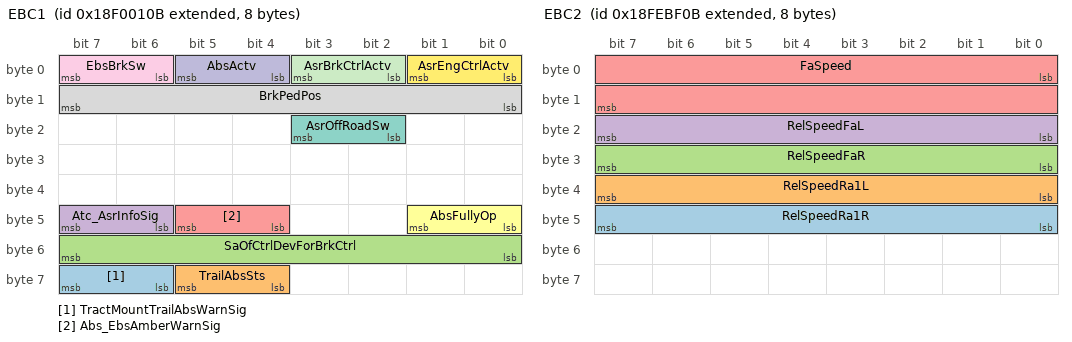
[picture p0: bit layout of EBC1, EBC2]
BO_ 2565865739 EBC1: 8 BSM
 SG_ TractMountTrailAbsWarnSig : 62|2@1+ (1,0) [0|3] ""  PCM
 SG_ TrailAbsSts : 60|2@1+ (1,0) [0|3] ""  PCM
 SG_ SaOfCtrlDevForBrkCtrl : 48|8@1+ (1,0) [0|255] "SA"  PCM
 SG_ Atc_AsrInfoSig : 46|2@1+ (1,0) [0|3] ""  PCM
 SG_ Abs_EbsAmberWarnSig : 44|2@1+ (1,0) [0|3] ""  PCM
 SG_ AbsFullyOp : 40|2@1+ (1,0) [0|3] ""  PCM
 SG_ AsrOffRoadSw : 18|2@1+ (1,0) [0|3] ""  PCM
 SG_ BrkPedPos : 8|8@1+ (0.4,0) [0|100] "%"  PCM
 SG_ EbsBrkSw : 6|2@1+ (1,0) [0|3] ""  PCM
 SG_ AbsActv : 4|2@1+ (1,0) [0|3] ""  PCM
 SG_ AsrBrkCtrlActv : 2|2@1+ (1,0) [0|3] ""  PCM
 SG_ AsrEngCtrlActv : 0|2@1+ (1,0) [0|3] ""  PCM

BO_ 2566831883 EBC2: 8 BSM
 SG_ RelSpeedRa1R : 40|8@1+ (0.0625,-7.8125) [-7.8125|7.8125] "km/h"  PCM
 SG_ RelSpeedRa1L : 32|8@1+ (0.0625,-7.8125) [-7.8125|7.8125] "km/h"  PCM
 SG_ RelSpeedFaR : 24|8@1+ (0.0625,-7.8125) [-7.8125|7.8125] "km/h"  PCM
 SG_ RelSpeedFaL : 16|8@1+ (0.0625,-7.8125) [-7.8125|7.8125] "km/h"  PCM
 SG_ FaSpeed : 0|16@1+ (0.00390625,0) [0|250.996] "km/h"  PCM

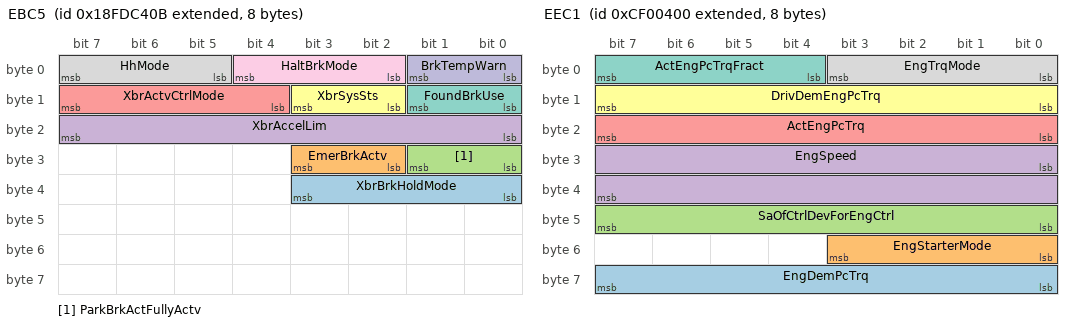
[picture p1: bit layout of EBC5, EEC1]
BO_ 2566767627 EBC5: 8 BSM
 SG_ XbrBrkHoldMode : 32|4@1+ (1,0) [0|15] ""  PCM
 SG_ EmerBrkActv : 26|2@1+ (1,0) [0|3] ""  PCM
 SG_ ParkBrkActFullyActv : 24|2@1+ (1,0) [0|3] ""  PCM
 SG_ XbrAccelLim : 16|8@1+ (0.1,-12.5) [-12.5|12.5] "m/s�"  PCM
 SG_ XbrActvCtrlMode : 12|4@1+ (1,0) [0|15] ""  PCM
 SG_ XbrSysSts : 10|2@1+ (1,0) [0|3] ""  PCM
 SG_ FoundBrkUse : 8|2@1+ (1,0) [0|3] ""  PCM
 SG_ HhMode : 5|3@1+ (1,0) [0|7] ""  PCM
 SG_ HaltBrkMode : 2|3@1+ (1,0) [0|7] ""  PCM
 SG_ BrkTempWarn : 0|2@1+ (1,0) [0|3] ""  PCM

BO_ 2566841088 EC1: 32 ECM
 SG_ EngJ : 240|16@1+ (0.004,0) [0|257.02] "kg*m�"  PCM
 SG_ EngReqSpeedCtrlRngUpLimXr : 224|16@1+ (0.125,0) [0|8031.875] "rpm"  PCM
 SG_ EngReqTrqCtrlRngUpLim : 216|8@1+ (1,-125) [-125|125] "%"  PCM
 SG_ EngReqTrqCtrlRngLowLim : 208|8@1+ (1,-125) [-125|125] "%"  PCM
 SG_ EngReqSpeedCtrlRngUpLim : 200|8@1+ (10,0) [0|2500] "rpm"  PCM
 SG_ EngReqSpeedCtrlRngLowLim : 192|8@1+ (10,0) [0|2500] "rpm"  PCM
 SG_ EngMaxMomOvrTimeLim : 184|8@1+ (0.1,0) [0|25] "s"  PCM
 SG_ EngMaxMomOvrSpeedPnt7 : 168|16@1+ (0.125,0) [0|8031.875] "rpm"  PCM
 SG_ EngRefTrq : 152|16@1+ (1,0) [0|64255] "Nm"  PCM
 SG_ EngGainEndspeedGov : 136|16@1+ (0.00078125,0) [0|50.2] "%/rpm"  PCM
 SG_ EngSpeedAtHighIdlePnt6 : 120|16@1+ (0.125,0) [0|8031.875] "rpm"  PCM
 SG_ EngPcTrqAtPnt5 : 112|8@1+ (1,-125) [-125|125] "%"  PCM
 SG_ EngSpeedAtPnt5 : 96|16@1+ (0.125,0) [0|8031.875] "rpm"  PCM
 SG_ EngPcTrqAtPnt4 : 88|8@1+ (1,-125) [-125|125] "%"  PCM
 SG_ EngSpeedAtPnt4 : 72|16@1+ (0.125,0) [0|8031.875] "rpm"  PCM
 SG_ EngPcTrqAtPnt3 : 64|8@1+ (1,-125) [-125|125] "%"  PCM
 SG_ EngSpeedAtPnt3 : 48|16@1+ (0.125,0) [0|8031.875] "rpm"  PCM
 SG_ EngPcTrqAtPnt2 : 40|8@1+ (1,-125) [-125|125] "%"  PCM
 SG_ EngSpeedAtPnt2 : 24|16@1+ (0.125,0) [0|8031.875] "rpm"  PCM
 SG_ EngPcTrqAtIdlePnt1 : 16|8@1+ (1,-125) [-125|125] "%"  PCM
 SG_ EngSpeedAtIdlePnt1 : 0|16@1+ (0.125,0) [0|8031.875] "rpm"  PCM

BO_ 2566767877 ECUID_05: 1005 NODE_5
 SG_ EcuHwId : 40|8@1+ (1,0) [0|255] "ASCII"  PCM
 SG_ EcuManName : 32|8@1+ (1,0) [0|255] "ASCII"  PCM
 SG_ EcuType : 24|8@1+ (1,0) [0|255] "ASCII"  PCM
 SG_ EcuLoc : 16|8@1+ (1,0) [0|255] "ASCII"  PCM
 SG_ EcuSn : 8|8@1+ (1,0) [0|255] "ASCII"  PCM
 SG_ EcuPn : 0|8@1+ (1,0) [0|255] "ASCII"  PCM

BO_ 2566767879 ECUID_07: 1005 NODE_7
 SG_ EcuHwId_FDC507 : 40|8@1+ (1,0) [0|255] "ASCII"  PCM
 SG_ EcuManName_FDC507 : 32|8@1+ (1,0) [0|255] "ASCII"  PCM
 SG_ EcuType_FDC507 : 24|8@1+ (1,0) [0|255] "ASCII"  PCM
 SG_ EcuLoc_FDC507 : 16|8@1+ (1,0) [0|255] "ASCII"  PCM
 SG_ EcuSn_FDC507 : 8|8@1+ (1,0) [0|255] "ASCII"  PCM
 SG_ EcuPn_FDC507 : 0|8@1+ (1,0) [0|255] "ASCII"  PCM

BO_ 2566767895 ECUID_17: 1005 ICC
 SG_ EcuHwId_FDC517 : 40|8@1+ (1,0) [0|255] "ASCII"  PCM
 SG_ EcuManName_FDC517 : 32|8@1+ (1,0) [0|255] "ASCII"  PCM
 SG_ EcuType_FDC517 : 24|8@1+ (1,0) [0|255] "ASCII"  PCM
 SG_ EcuLoc_FDC517 : 16|8@1+ (1,0) [0|255] "ASCII"  PCM
 SG_ EcuSn_FDC517 : 8|8@1+ (1,0) [0|255] "ASCII"  PCM
 SG_ EcuPn_FDC517 : 0|8@1+ (1,0) [0|255] "ASCII"  PCM

BO_ 2566767898 ECUID_1A: 1005 ECS
 SG_ EcuHwId_FDC51A : 40|8@1+ (1,0) [0|255] "ASCII"  PCM
 SG_ EcuManName_FDC51A : 32|8@1+ (1,0) [0|255] "ASCII"  PCM
 SG_ EcuType_FDC51A : 24|8@1+ (1,0) [0|255] "ASCII"  PCM
 SG_ EcuLoc_FDC51A : 16|8@1+ (1,0) [0|255] "ASCII"  PCM
 SG_ EcuSn_FDC51A : 8|8@1+ (1,0) [0|255] "ASCII"  PCM
 SG_ EcuPn_FDC51A : 0|8@1+ (1,0) [0|255] "ASCII"  PCM

BO_ 2566767901 ECUID_1D: 1005 SGW
 SG_ EcuHwId_FDC51D : 40|8@1+ (1,0) [0|255] "ASCII"  PCM
 SG_ EcuManName_FDC51D : 32|8@1+ (1,0) [0|255] "ASCII"  PCM
 SG_ EcuType_FDC51D : 24|8@1+ (1,0) [0|255] "ASCII"  PCM
 SG_ EcuLoc_FDC51D : 16|8@1+ (1,0) [0|255] "ASCII"  PCM
 SG_ EcuSn_FDC51D : 8|8@1+ (1,0) [0|255] "ASCII"  PCM
 SG_ EcuPn_FDC51D : 0|8@1+ (1,0) [0|255] "ASCII"  PCM

BO_ 2566767908 ECUID_24: 1005 NODE_24
 SG_ EcuHwId_FDC524 : 40|8@1+ (1,0) [0|255] "ASCII"  PCM
 SG_ EcuManName_FDC524 : 32|8@1+ (1,0) [0|255] "ASCII"  PCM
 SG_ EcuType_FDC524 : 24|8@1+ (1,0) [0|255] "ASCII"  PCM
 SG_ EcuLoc_FDC524 : 16|8@1+ (1,0) [0|255] "ASCII"  PCM
 SG_ EcuSn_FDC524 : 8|8@1+ (1,0) [0|255] "ASCII"  PCM
 SG_ EcuPn_FDC524 : 0|8@1+ (1,0) [0|255] "ASCII"  PCM

BO_ 2566767911 ECUID_27: 1005 VCM
 SG_ EcuHwId_FDC527 : 40|8@1+ (1,0) [0|255] "ASCII"  PCM
 SG_ EcuManName_FDC527 : 32|8@1+ (1,0) [0|255] "ASCII"  PCM
 SG_ EcuType_FDC527 : 24|8@1+ (1,0) [0|255] "ASCII"  PCM
 SG_ EcuLoc_FDC527 : 16|8@1+ (1,0) [0|255] "ASCII"  PCM
 SG_ EcuSn_FDC527 : 8|8@1+ (1,0) [0|255] "ASCII"  PCM
 SG_ EcuPn_FDC527 : 0|8@1+ (1,0) [0|255] "ASCII"  PCM

BO_ 2566767919 ECUID_2F: 1005 ECAS
 SG_ EcuHwId_FDC52F : 40|8@1+ (1,0) [0|255] "ASCII"  PCM
 SG_ EcuManName_FDC52F : 32|8@1+ (1,0) [0|255] "ASCII"  PCM
 SG_ EcuLoc_FDC52F : 16|8@1+ (1,0) [0|255] "ASCII"  PCM
 SG_ EcuSn_FDC52F : 8|8@1+ (1,0) [0|255] "ASCII"  PCM
 SG_ EcuPn_FDC52F : 0|8@1+ (1,0) [0|255] "ASCII"  PCM

BO_ 2566767920 ECUID_30: 1005 CDC
 SG_ EcuHwId_FDC530 : 40|8@1+ (1,0) [0|255] "ASCII"  PCM
 SG_ EcuManName_FDC530 : 32|8@1+ (1,0) [0|255] "ASCII"  PCM
 SG_ EcuType_FDC530 : 24|8@1+ (1,0) [0|255] "ASCII"  PCM
 SG_ EcuLoc_FDC530 : 16|8@1+ (1,0) [0|255] "ASCII"  PCM
 SG_ EcuSn_FDC530 : 8|8@1+ (1,0) [0|255] "ASCII"  PCM
 SG_ EcuPn_FDC530 : 0|8@1+ (1,0) [0|255] "ASCII"  PCM

BO_ 2566767923 ECUID_33: 1005 OptiTire
 SG_ EcuHwId_FDC533 : 40|8@1+ (1,0) [0|255] "ASCII"  PCM
 SG_ EcuManName_FDC533 : 32|8@1+ (1,0) [0|255] "ASCII"  PCM
 SG_ EcuType_FDC533 : 24|8@1+ (1,0) [0|255] "ASCII"  PCM
 SG_ EcuLoc_FDC533 : 16|8@1+ (1,0) [0|255] "ASCII"  PCM
 SG_ EcuSn_FDC533 : 8|8@1+ (1,0) [0|255] "ASCII"  PCM
 SG_ EcuPn_FDC533 : 0|8@1+ (1,0) [0|255] "ASCII"  PCM

BO_ 2566767937 ECUID_41: 1005 NIS_RDR
 SG_ EcuHwId_FDC541 : 40|8@1+ (1,0) [0|255] "ASCII"  PCM
 SG_ EcuManName_FDC541 : 32|8@1+ (1,0) [0|255] "ASCII"  PCM
 SG_ EcuType_FDC541 : 24|8@1+ (1,0) [0|255] "ASCII"  PCM
 SG_ EcuLoc_FDC541 : 16|8@1+ (1,0) [0|255] "ASCII"  PCM
 SG_ EcuSn_FDC541 : 8|8@1+ (1,0) [0|255] "ASCII"  PCM
 SG_ EcuPn_FDC541 : 0|8@1+ (1,0) [0|255] "ASCII"  PCM

BO_ 2566767945 ECUID_49: 1005 NODE_49
 SG_ EcuHwId_FDC549 : 40|8@1+ (1,0) [0|255] "ASCII"  PCM
 SG_ EcuManName_FDC549 : 32|8@1+ (1,0) [0|255] "ASCII"  PCM
 SG_ EcuType_FDC549 : 24|8@1+ (1,0) [0|255] "ASCII"  PCM
 SG_ EcuLoc_FDC549 : 16|8@1+ (1,0) [0|255] "ASCII"  PCM
 SG_ EcuSn_FDC549 : 8|8@1+ (1,0) [0|255] "ASCII"  PCM
 SG_ EcuPn_FDC549 : 0|8@1+ (1,0) [0|255] "ASCII"  PCM

BO_ 2566767946 ECUID_4A: 1005 PCM
 SG_ EcuHwId_FDC54A : 40|8@1+ (1,0) [0|255] "ASCII" Vector__XXX
 SG_ EcuManName_FDC54A : 32|8@1+ (1,0) [0|255] "ASCII" Vector__XXX
 SG_ EcuType_FDC54A : 24|8@1+ (1,0) [0|255] "ASCII" Vector__XXX
 SG_ EcuLoc_FDC54A : 16|8@1+ (1,0) [0|255] "ASCII" Vector__XXX
 SG_ EcuSn_FDC54A : 8|8@1+ (1,0) [0|255] "ASCII" Vector__XXX
 SG_ EcuPn_FDC54A : 0|8@1+ (1,0) [0|255] "ASCII" Vector__XXX

BO_ 2566767949 ECUID_4D: 1005 SCU
 SG_ EcuHwId_FDC54D : 40|8@1+ (1,0) [0|255] "ASCII"  PCM
 SG_ EcuManName_FDC54D : 32|8@1+ (1,0) [0|255] "ASCII"  PCM
 SG_ EcuType_FDC54D : 24|8@1+ (1,0) [0|255] "ASCII"  PCM
 SG_ EcuLoc_FDC54D : 16|8@1+ (1,0) [0|255] "ASCII"  PCM
 SG_ EcuSn_FDC54D : 8|8@1+ (1,0) [0|255] "ASCII"  PCM
 SG_ EcuPn_FDC54D : 0|8@1+ (1,0) [0|255] "ASCII"  PCM

BO_ 2566767955 ECUID_53: 1005 Airbag
 SG_ EcuHwId_FDC553 : 40|8@1+ (1,0) [0|255] "ASCII"  PCM
 SG_ EcuManName_FDC553 : 32|8@1+ (1,0) [0|255] "ASCII"  PCM
 SG_ EcuType_FDC553 : 24|8@1+ (1,0) [0|255] "ASCII"  PCM
 SG_ EcuLoc_FDC553 : 16|8@1+ (1,0) [0|255] "ASCII"  PCM
 SG_ EcuSn_FDC553 : 8|8@1+ (1,0) [0|255] "ASCII"  PCM
 SG_ EcuPn_FDC553 : 0|8@1+ (1,0) [0|255] "ASCII"  PCM

BO_ 2566767992 ECUID_78: 1005 PAM
 SG_ EcuHwId_FDC578 : 40|8@1+ (1,0) [0|255] "ASCII"  PCM
 SG_ EcuManName_FDC578 : 32|8@1+ (1,0) [0|255] "ASCII"  PCM
 SG_ EcuType_FDC578 : 24|8@1+ (1,0) [0|255] "ASCII"  PCM
 SG_ EcuLoc_FDC578 : 16|8@1+ (1,0) [0|255] "ASCII"  PCM
 SG_ EcuSn_FDC578 : 8|8@1+ (1,0) [0|255] "ASCII"  PCM
 SG_ EcuPn_FDC578 : 0|8@1+ (1,0) [0|255] "ASCII"  PCM

BO_ 2566767996 ECUID_7C: 1005 NODE_7C
 SG_ EcuHwId_FDC57C : 40|8@1+ (1,0) [0|255] "ASCII"  PCM
 SG_ EcuManName_FDC57C : 32|8@1+ (1,0) [0|255] "ASCII"  PCM
 SG_ EcuType_FDC57C : 24|8@1+ (1,0) [0|255] "ASCII"  PCM
 SG_ EcuLoc_FDC57C : 16|8@1+ (1,0) [0|255] "ASCII"  PCM
 SG_ EcuSn_FDC57C : 8|8@1+ (1,0) [0|255] "ASCII"  PCM
 SG_ EcuPn_FDC57C : 0|8@1+ (1,0) [0|255] "ASCII"  PCM

BO_ 2566768110 ECUID_EE: 1005 DTCO
 SG_ EcuPn_FDC5EE : 0|8@1+ (1,0) [0|255] "ASCII"  PCM

BO_ 2566768111 ECUID_EF: 1005 NODE_EF
 SG_ EcuHwId_FDC5EF : 40|8@1+ (1,0) [0|255] "ASCII"  PCM
 SG_ EcuManName_FDC5EF : 32|8@1+ (1,0) [0|255] "ASCII"  PCM
 SG_ EcuType_FDC5EF : 24|8@1+ (1,0) [0|255] "ASCII"  PCM
 SG_ EcuLoc_FDC5EF : 16|8@1+ (1,0) [0|255] "ASCII"  PCM
 SG_ EcuSn_FDC5EF : 8|8@1+ (1,0) [0|255] "ASCII"  PCM
 SG_ EcuPn_FDC5EF : 0|8@1+ (1,0) [0|255] "ASCII"  PCM

BO_ 2566768114 ECUID_F2: 1005 NODE_F2
 SG_ EcuHwId_FDC5F2 : 40|8@1+ (1,0) [0|255] "ASCII"  PCM
 SG_ EcuManName_FDC5F2 : 32|8@1+ (1,0) [0|255] "ASCII"  PCM
 SG_ EcuType_FDC5F2 : 24|8@1+ (1,0) [0|255] "ASCII"  PCM
 SG_ EcuLoc_FDC5F2 : 16|8@1+ (1,0) [0|255] "ASCII"  PCM
 SG_ EcuSn_FDC5F2 : 8|8@1+ (1,0) [0|255] "ASCII"  PCM
 SG_ EcuPn_FDC5F2 : 0|8@1+ (1,0) [0|255] "ASCII"  PCM

BO_ 2566768115 ECUID_F3: 1005 NODE_F3
 SG_ EcuHwId_FDC5F3 : 40|8@1+ (1,0) [0|255] "ASCII"  PCM
 SG_ EcuManName_FDC5F3 : 32|8@1+ (1,0) [0|255] "ASCII"  PCM
 SG_ EcuType_FDC5F3 : 24|8@1+ (1,0) [0|255] "ASCII"  PCM
 SG_ EcuLoc_FDC5F3 : 16|8@1+ (1,0) [0|255] "ASCII"  PCM
 SG_ EcuSn_FDC5F3 : 8|8@1+ (1,0) [0|255] "ASCII"  PCM
 SG_ EcuPn_FDC5F3 : 0|8@1+ (1,0) [0|255] "ASCII"  PCM

BO_ 2566856960 Edc2Bc: 8 ECM
 SG_ AtDpfAregenSts : 60|2@1+ (1,0) [0|3] ""  PCM
 SG_ FuelType : 58|2@1+ (1,0) [0|3] ""  PCM
 SG_ AcComprSts : 56|2@1+ (1,0) [0|3] ""  PCM
 SG_ EdcOpSts : 52|4@1+ (1,0) [0|15] ""  PCM
 SG_ EngDegrLev : 48|4@1+ (1,0) [0|15] ""  PCM
 SG_ FuelFiltHeat : 44|2@1+ (1,0) [0|3] ""  PCM
 SG_ WaterInFuelInd1 : 42|2@1+ (1,0) [0|3] ""  PCM
 SG_ EngOilPrsLow : 40|2@1+ (1,0) [0|3] ""  PCM
 SG_ RegenStsLamp : 34|2@1+ (1,0) [0|3] ""  PCM
 SG_ OilLifeMonSts : 32|2@1+ (1,0) [0|3] ""  PCM
 SG_ ExhGasTempSts : 30|2@1+ (1,0) [0|3] ""  PCM
 SG_ VslaSts : 28|2@1+ (1,0) [0|3] ""  PCM
 SG_ ElLoadReq : 26|2@1+ (1,0) [0|3] ""  PCM
 SG_ ObdMilSts : 24|2@1+ (1,0) [0|3] ""  PCM
 SG_ MaxVslSetp : 16|8@1+ (1,0) [0|250] "km/h"  PCM
 SG_ EngOverTemp : 13|3@1+ (1,0) [0|7] ""  PCM
 SG_ UnsuccRegenStsLamp1 : 12|1@1+ (1,0) [0|1] ""  PCM
 SG_ EngOverspeed : 10|2@1+ (1,0) [0|3] ""  PCM
 SG_ VslSts : 8|2@1+ (1,0) [0|3] ""  PCM
 SG_ FuelBlkByImmo : 4|2@1+ (1,0) [0|3] ""  PCM
 SG_ AtDpfSts : 0|3@1+ (1,0) [0|7] ""  PCM

BO_ 2364539904 EEC1: 8 ECM
 SG_ EngDemPcTrq : 56|8@1+ (1,-125) [-125|125] "%"  PCM
 SG_ EngStarterMode : 48|4@1+ (1,0) [0|15] ""  PCM
 SG_ SaOfCtrlDevForEngCtrl : 40|8@1+ (1,0) [0|255] "SA"  PCM
 SG_ EngSpeed : 24|16@1+ (0.125,0) [0|8031.875] "rpm"  PCM
 SG_ ActEngPcTrq : 16|8@1+ (1,-125) [-125|125] "%"  PCM
 SG_ DrivDemEngPcTrq : 8|8@1+ (1,-125) [-125|125] "%"  PCM
 SG_ ActEngPcTrqFract : 4|4@1+ (0.125,0) [0|0.875] "%"  PCM
 SG_ EngTrqMode : 0|4@1+ (1,0) [0|15] ""  PCM

BO_ 2566767104 EEC14: 8 ECM
 SG_ FuelType_FDC200 : 48|8@1+ (1,0) [0|255] ""  PCM

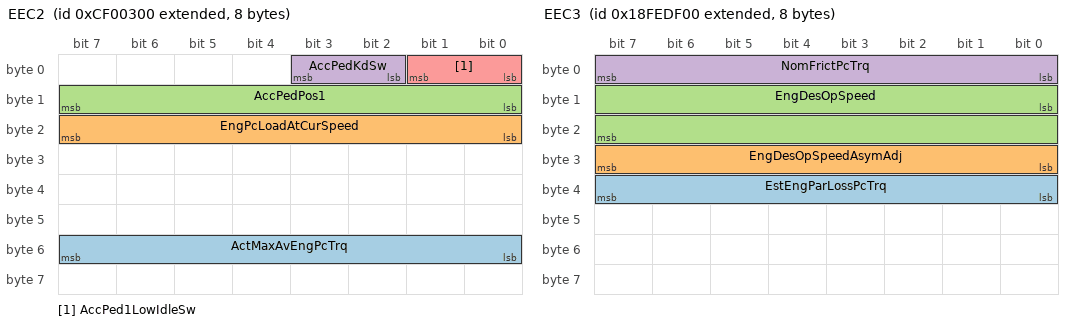
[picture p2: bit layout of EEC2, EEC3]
BO_ 2364539648 EEC2: 8 ECM
 SG_ ActMaxAvEngPcTrq : 48|8@1+ (0.4,0) [0|100] "%"  PCM
 SG_ EngPcLoadAtCurSpeed : 16|8@1+ (1,0) [0|250] "%"  PCM
 SG_ AccPedPos1 : 8|8@1+ (0.4,0) [0|100] "%"  PCM
 SG_ AccPedKdSw : 2|2@1+ (1,0) [0|3] ""  PCM
 SG_ AccPed1LowIdleSw : 0|2@1+ (1,0) [0|3] ""  PCM

BO_ 2566840064 EEC3: 8 ECM
 SG_ EstEngParLossPcTrq : 32|8@1+ (1,-125) [-125|125] "%"  PCM
 SG_ EngDesOpSpeedAsymAdj : 24|8@1+ (1,0) [0|250] ""  PCM
 SG_ EngDesOpSpeed : 8|16@1+ (0.125,0) [0|8031.875] "rpm"  PCM
 SG_ NomFrictPcTrq : 0|8@1+ (1,-125) [-125|125] "%"  PCM

BO_ 2566844160 EFLP1: 8 ECM
 SG_ EngCoolPrs1 : 48|8@1+ (2,0) [0|500] "kPa"  PCM
 SG_ EngOilLev : 16|8@1+ (0.4,0) [0|100] "%"  PCM

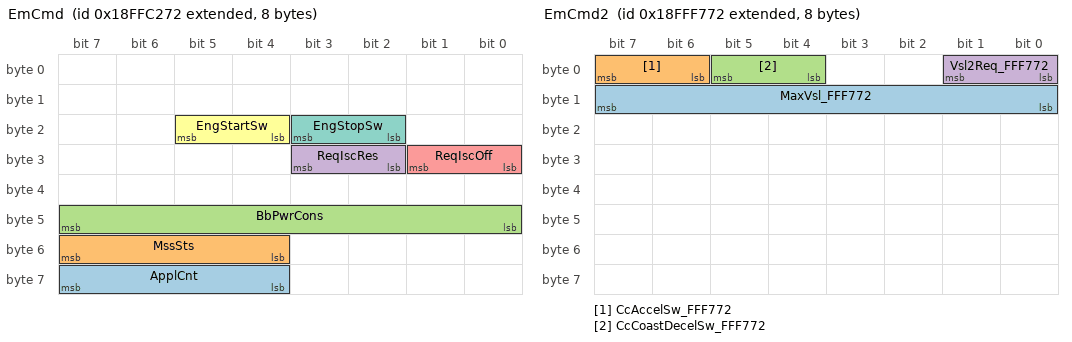
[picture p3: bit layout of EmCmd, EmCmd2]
BO_ 2566898290 EmCmd: 8 EM_PTO
 SG_ ApplCnt : 60|4@1+ (1,0) [0|15] ""  PCM
 SG_ MssSts : 52|4@1+ (1,0) [0|15] ""  PCM
 SG_ BbPwrCons : 40|8@1+ (1,0) [0|250] "kW"  PCM
 SG_ ReqIscRes : 26|2@1+ (1,0) [0|3] ""  PCM
 SG_ ReqIscOff : 24|2@1+ (1,0) [0|3] ""  PCM
 SG_ EngStartSw : 20|2@1+ (1,0) [0|3] ""  PCM
 SG_ EngStopSw : 18|2@1+ (1,0) [0|3] ""  PCM

BO_ 2566911858 EmCmd2: 8 EM_PTO
 SG_ MaxVsl_FFF772 : 8|8@1+ (1,0) [0|250] "km/h"  PCM
 SG_ CcAccelSw_FFF772 : 6|2@1+ (1,0) [0|3] ""  PCM
 SG_ CcCoastDecelSw_FFF772 : 4|2@1+ (1,0) [0|3] ""  PCM
 SG_ Vsl2Req_FFF772 : 0|2@1+ (1,0) [0|3] ""  PCM

BO_ 2565865505 ERC1_21: 8 BCM
 SG_ RetSelNonEng : 48|8@1+ (0.4,0) [0|100] "%"  PCM
 SG_ RetEnaBrkAssSw : 4|2@1+ (1,0) [0|3] ""  PCM

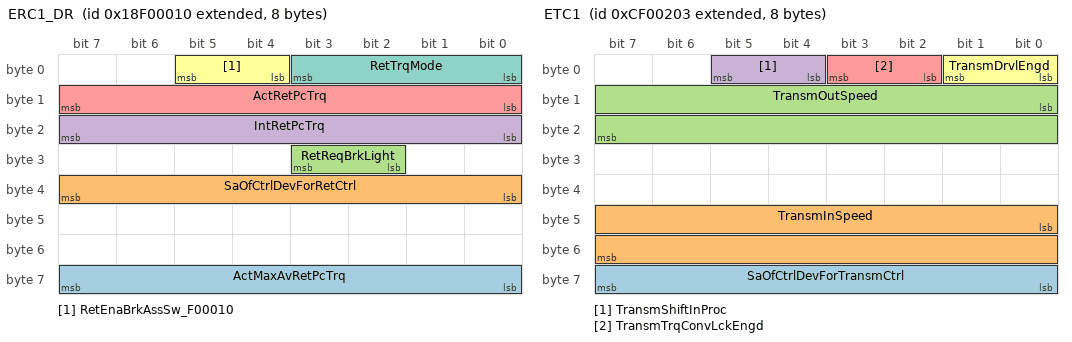
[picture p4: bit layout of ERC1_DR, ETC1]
BO_ 2565865488 ERC1_DR: 8 EST54_IRCS
 SG_ ActMaxAvRetPcTrq : 56|8@1+ (1,-125) [-125|125] "%"  PCM
 SG_ SaOfCtrlDevForRetCtrl : 32|8@1+ (1,0) [0|255] "SA"  PCM
 SG_ RetReqBrkLight : 26|2@1+ (1,0) [0|3] ""  PCM
 SG_ IntRetPcTrq : 16|8@1+ (1,-125) [-125|125] "%"  PCM
 SG_ ActRetPcTrq : 8|8@1+ (1,-125) [-125|125] "%"  PCM
 SG_ RetEnaBrkAssSw_F00010 : 4|2@1+ (1,0) [0|3] ""  PCM
 SG_ RetTrqMode : 0|4@1+ (1,0) [0|15] ""  PCM

BO_ 2566843904 ET1: 8 ECM
 SG_ EngFuel1Temp1 : 8|8@1+ (1,-40) [-40|210] "�C"  PCM
 SG_ EngCoolTemp : 0|8@1+ (1,-40) [-40|210] "�C"  PCM

BO_ 2364539395 ETC1: 8 AI_G5_TCM
 SG_ SaOfCtrlDevForTransmCtrl : 56|8@1+ (1,0) [0|255] "SA"  PCM
 SG_ TransmInSpeed : 40|16@1+ (0.125,0) [0|8031.875] "rpm"  PCM
 SG_ TransmOutSpeed : 8|16@1+ (0.125,0) [0|8031.875] "rpm"  PCM
 SG_ TransmShiftInProc : 4|2@1+ (1,0) [0|3] ""  PCM
 SG_ TransmTrqConvLckEngd : 2|2@1+ (1,0) [0|3] ""  PCM
 SG_ TransmDrvlEngd : 0|2@1+ (1,0) [0|3] ""  PCM

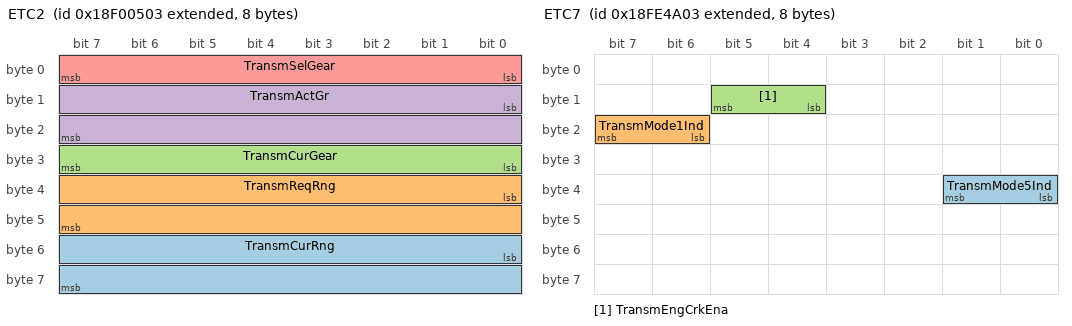
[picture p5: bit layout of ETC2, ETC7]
BO_ 2565866755 ETC2: 8 AI_G5_TCM
 SG_ TransmCurRng : 48|16@1+ (1,0) [0|255] "ASCII"  PCM
 SG_ TransmReqRng : 32|16@1+ (1,0) [0|255] "ASCII"  PCM
 SG_ TransmCurGear : 24|8@1+ (1,-125) [-125|125] "gear value"  PCM
 SG_ TransmActGr : 8|16@1+ (0.001,0) [0|64.255] ""  PCM
 SG_ TransmSelGear : 0|8@1+ (1,-125) [-125|125] "gear value"  PCM

BO_ 2633941763 ETC5: 8 AI_G5_TCM
 SG_ TransmRevDirSw : 8|2@1+ (1,0) [0|3] ""  PCM

BO_ 2566801923 ETC7: 8 AI_G5_TCM
 SG_ TransmMode5Ind : 32|2@1+ (1,0) [0|3] ""  PCM
 SG_ TransmMode1Ind : 22|2@1+ (1,0) [0|3] ""  PCM
 SG_ TransmEngCrkEna : 12|2@1+ (1,0) [0|3] ""  PCM

BO_ 2364541955 ETC8: 8 AI_G5_TCM
 SG_ TransmTrqConvRatio : 0|16@1+ (0.001,0) [0|64.255] ""  PCM

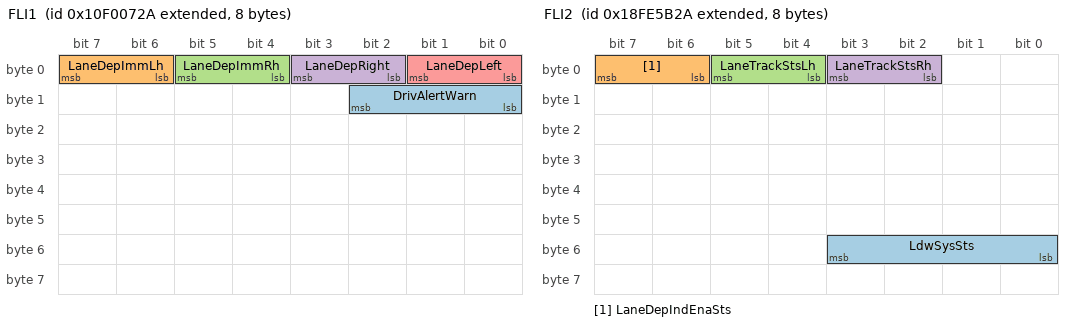
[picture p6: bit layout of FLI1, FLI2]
BO_ 2431649578 FLI1: 8 LDW
 SG_ DrivAlertWarn : 8|3@1+ (1,0) [0|7] ""  PCM
 SG_ LaneDepImmLh : 6|2@1+ (1,0) [0|3] ""  PCM
 SG_ LaneDepImmRh : 4|2@1+ (1,0) [0|3] ""  PCM
 SG_ LaneDepRight : 2|2@1+ (1,0) [0|3] ""  PCM
 SG_ LaneDepLeft : 0|2@1+ (1,0) [0|3] ""  PCM

BO_ 2566806314 FLI2: 8 LDW
 SG_ LdwSysSts : 48|4@1+ (1,0) [0|15] ""  PCM
 SG_ LaneDepIndEnaSts : 6|2@1+ (1,0) [0|3] ""  PCM
 SG_ LaneTrackStsLh : 4|2@1+ (1,0) [0|3] ""  PCM
 SG_ LaneTrackStsRh : 2|2@1+ (1,0) [0|3] ""  PCM

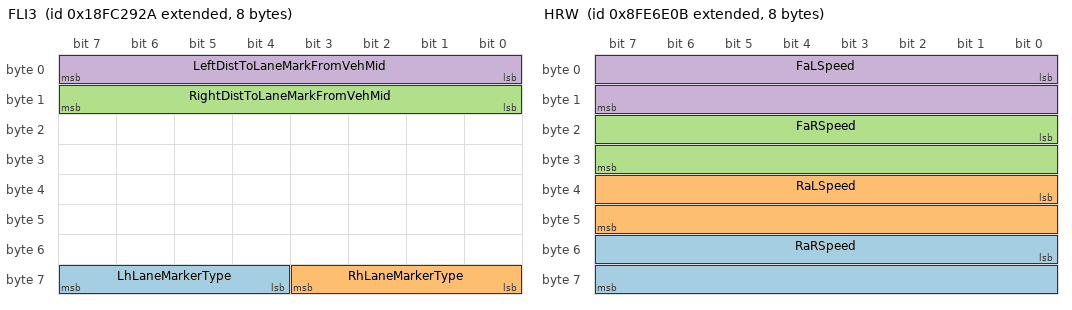
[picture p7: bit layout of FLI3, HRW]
BO_ 2566662442 FLI3: 8 LDW
 SG_ LhLaneMarkerType : 60|4@1+ (1,0) [0|15] ""  PCM
 SG_ RhLaneMarkerType : 56|4@1+ (1,0) [0|15] ""  PCM
 SG_ RightDistToLaneMarkFromVehMid : 8|8@1+ (0.02,0) [0|5] "m"  PCM
 SG_ LeftDistToLaneMarkFromVehMid : 0|8@1+ (0.02,0) [0|5] "m"  PCM

BO_ 2561223201 FLIC: 8 BCM
 SG_ LdwEnaCmd : 0|2@1+ (1,0) [0|3] ""  PCM,LDW

BO_ 2566749463 FMS1_17: 8 ICC
 SG_ FrontFogLight m0 : 60|3@1+ (1,0) [0|7] ""  PCM
 SG_ LdwSwdOff m3 : 60|3@1+ (1,0) [0|7] ""  PCM
 SG_ PosLightSideLight m0 : 56|3@1+ (1,0) [0|7] ""  PCM
 SG_ EngCoolLev m1 : 56|3@1+ (1,0) [0|7] ""  PCM
 SG_ EscSwdOff m3 : 56|3@1+ (1,0) [0|7] ""  PCM
 SG_ EngOil m0 : 52|3@1+ (1,0) [0|7] ""  PCM
 SG_ EngOilLev_FD7D17 m1 : 52|3@1+ (1,0) [0|7] ""  PCM
 SG_ TcoInd m3 : 52|3@1+ (1,0) [0|7] ""  PCM
 SG_ BatChgCond m0 : 48|3@1+ (1,0) [0|7] ""  PCM
 SG_ EngCoolTemp_FD7D17 m0 : 44|3@1+ (1,0) [0|7] ""  PCM
 SG_ Malf_GenFail m1 : 44|3@1+ (1,0) [0|7] ""  PCM
 SG_ AdblueLev m2 : 44|3@1+ (1,0) [0|7] ""  PCM
 SG_ Airbag m3 : 44|3@1+ (1,0) [0|7] ""  PCM
 SG_ FuelLev m0 : 40|3@1+ (1,0) [0|7] ""  PCM
 SG_ TireFail_Malf m1 : 40|3@1+ (1,0) [0|7] ""  PCM
 SG_ ElMotSts m4 : 40|3@1+ (1,0) [0|7] ""  PCM
 SG_ HatchOpen m0 : 36|3@1+ (1,0) [0|7] ""  PCM
 SG_ BatCool m4 : 36|3@1+ (1,0) [0|7] ""  PCM
 SG_ BrkFail_BrkSysMalf m0 : 32|3@1+ (1,0) [0|7] ""  PCM
 SG_ WornBrkLin m1 : 32|3@1+ (1,0) [0|7] ""  PCM
 SG_ Acc m3 : 32|3@1+ (1,0) [0|7] ""  PCM
 SG_ LimPerfElMot m4 : 32|3@1+ (1,0) [0|7] ""  PCM
 SG_ ParkBrk m0 : 28|3@1+ (1,0) [0|7] ""  PCM
 SG_ AntiLckBrkSysFail m1 : 28|3@1+ (1,0) [0|7] ""  PCM
 SG_ Aebs m3 : 28|3@1+ (1,0) [0|7] ""  PCM
 SG_ BatTemp_FD7D17 m4 : 28|3@1+ (1,0) [0|7] ""  PCM
 SG_ TransmFail_Malf m1 : 24|3@1+ (1,0) [0|7] ""  PCM
 SG_ BrkLight m2 : 24|3@1+ (1,0) [0|7] ""  PCM
 SG_ LaneDepInd m3 : 24|3@1+ (1,0) [0|7] ""  PCM
 SG_ HighVSysCaution m4 : 24|3@1+ (1,0) [0|7] ""  PCM
 SG_ HazardWarn m0 : 20|3@1+ (1,0) [0|7] ""  PCM
 SG_ TransmFluidTemp m1 : 20|3@1+ (1,0) [0|7] ""  PCM
 SG_ EscInd m2 : 20|3@1+ (1,0) [0|7] ""  PCM
 SG_ Bat m4 : 20|3@1+ (1,0) [0|7] ""  PCM
 SG_ TurnSigs m0 : 16|3@1+ (1,0) [0|7] ""  PCM
 SG_ ServCallForMaint m1 : 16|3@1+ (1,0) [0|7] ""  PCM
 SG_ EngEmisSysFailMil m2 : 16|3@1+ (1,0) [0|7] ""  PCM
 SG_ SeatBelt m3 : 16|3@1+ (1,0) [0|7] ""  PCM
 SG_ LowBeamDipBeam m0 : 12|3@1+ (1,0) [0|7] ""  PCM
 SG_ Eng_Mil m1 : 12|3@1+ (1,0) [0|7] ""  PCM
 SG_ Ret m2 : 12|3@1+ (1,0) [0|7] ""  PCM
 SG_ FuelFiltDiffPrs m3 : 12|3@1+ (1,0) [0|7] ""  PCM
 SG_ HighBeamMainBeam m0 : 8|3@1+ (1,0) [0|7] ""  PCM
 SG_ HtCtrl m2 : 8|3@1+ (1,0) [0|7] ""  PCM
 SG_ AirFiltClog m3 : 8|3@1+ (1,0) [0|7] ""  PCM
 SG_ ElMotFails m4 : 8|3@1+ (1,0) [0|7] ""  PCM
 SG_ RearFogLight m1 : 4|3@1+ (1,0) [0|7] ""  PCM
 SG_ EngEmisFilt m4 : 4|3@1+ (1,0) [0|7] ""  PCM
 SG_ TtBlkId M : 0|4@1+ (1,0) [0|15] ""  PCM

BO_ 2566896128 FUELE2: 8 ECM
 SG_ EngInstFuelEcon : 16|16@1+ (0.001953125,0) [0|125.498046875] "km/L"  PCM
 SG_ EngFuelRate : 0|16@1+ (0.05,0) [0|3212.75] "L/h"  PCM

BO_ 2566841600 HOURS: 8 ECM
 SG_ EngTotRevl : 32|32@1+ (1000,0) [0|4211081215000] "r"  PCM
 SG_ EngTotHrOfOp : 0|32@1+ (0.05,0) [0|210554060.75] "h"  PCM

BO_ 2566719744 HRLFC: 8 ECM
 SG_ EngTotFuelUsedHr : 32|32@1+ (0.001,0) [0|4211081.215] "L"  PCM

BO_ 2298375691 HRW: 8 BSM
 SG_ RaRSpeed : 48|16@1+ (0.00390625,0) [0|250.996] "km/h"  PCM
 SG_ RaLSpeed : 32|16@1+ (0.00390625,0) [0|250.996] "km/h"  PCM
 SG_ FaRSpeed : 16|16@1+ (0.00390625,0) [0|250.996] "km/h"  PCM
 SG_ FaLSpeed : 0|16@1+ (0.00390625,0) [0|250.996] "km/h"  PCM

BO_ 2566609652 HVESP1CFG_F4: 16 NODE_F4
 SG_ Hvesp1CellVminLim : 120|8@1+ (0.02044,0) [0|5.11] "V"  PCM
 SG_ Hvesp1CellVmaxLim : 112|8@1+ (0.02044,0) [0|5.11] "V"  PCM
 SG_ Hvesp1RecomMinOpTemp : 96|16@1+ (0.03125,-273) [-273|1734.96875] "�C"  PCM
 SG_ Hvesp1RecomMaxOpTemp : 80|16@1+ (0.03125,-273) [-273|1734.96875] "�C"  PCM
 SG_ Hvesp1RecomMaxSoc : 64|16@1+ (0.0015625,0) [0|100.3984375] "%"  PCM
 SG_ Hvesp1RecomMinSoc : 48|16@1+ (0.0015625,0) [0|100.3984375] "%"  PCM
 SG_ Hvesp1RecomMaxOpV : 32|16@1+ (0.05,0) [0|3212.75] "V"  PCM
 SG_ Hvesp1RecomMinOpV : 16|16@1+ (0.05,0) [0|3212.75] "V"  PCM
 SG_ Hvesp1NomV : 0|16@1+ (0.05,0) [0|3212.75] "V"  PCM

BO_ 2566609141 HVESP2CFG_F5: 16 NODE_F5
 SG_ Hvesp2CellVminLim : 120|8@1+ (0.02044,0) [0|5.11] "V"  PCM
 SG_ Hvesp2CellVmaxLim : 112|8@1+ (0.02044,0) [0|5.11] "V"  PCM
 SG_ Hvesp2RecomMinOpTemp : 96|16@1+ (0.03125,-273) [-273|1734.96875] "�C"  PCM
 SG_ Hvesp2RecomMaxOpTemp : 80|16@1+ (0.03125,-273) [-273|1734.96875] "�C"  PCM
 SG_ Hvesp2RecomMaxSoc : 64|16@1+ (0.0015625,0) [0|100.3984375] "%"  PCM
 SG_ Hvesp2RecomMinSoc : 48|16@1+ (0.0015625,0) [0|100.3984375] "%"  PCM
 SG_ Hvesp2RecomMaxOpV : 32|16@1+ (0.05,0) [0|3212.75] "V"  PCM
 SG_ Hvesp2RecomMinOpV : 16|16@1+ (0.05,0) [0|3212.75] "V"  PCM
 SG_ Hvesp2NomV : 0|16@1+ (0.05,0) [0|3212.75] "V"  PCM

BO_ 2566608630 HVESP3CFG_F6: 16 NODE_F6
 SG_ Hvesp3CellVminLim : 120|8@1+ (0.02044,0) [0|5.11] "V"  PCM
 SG_ Hvesp3CellVmaxLim : 112|8@1+ (0.02044,0) [0|5.11] "V"  PCM
 SG_ Hvesp3RecomMinOpTemp : 96|16@1+ (0.03125,-273) [-273|1734.96875] "�C"  PCM
 SG_ Hvesp3RecomMaxOpTemp : 80|16@1+ (0.03125,-273) [-273|1734.96875] "�C"  PCM
 SG_ Hvesp3RecomMaxSoc : 64|16@1+ (0.0015625,0) [0|100.3984375] "%"  PCM
 SG_ Hvesp3RecomMinSoc : 48|16@1+ (0.0015625,0) [0|100.3984375] "%"  PCM
 SG_ Hvesp3RecomMaxOpV : 32|16@1+ (0.05,0) [0|3212.75] "V"  PCM
 SG_ Hvesp3RecomMinOpV : 16|16@1+ (0.05,0) [0|3212.75] "V"  PCM
 SG_ Hvesp3NomV : 0|16@1+ (0.05,0) [0|3212.75] "V"  PCM

BO_ 2566608006 HVESP4CFG_86: 16 NODE_86
 SG_ Hvesp4CellVminLim : 120|8@1+ (0.02044,0) [0|5.11] "V"  PCM
 SG_ Hvesp4CellVmaxLim : 112|8@1+ (0.02044,0) [0|5.11] "V"  PCM
 SG_ Hvesp4RecomMinOpTemp : 96|16@1+ (0.03125,-273) [-273|1734.96875] "�C"  PCM
 SG_ Hvesp4RecomMaxOpTemp : 80|16@1+ (0.03125,-273) [-273|1734.96875] "�C"  PCM
 SG_ Hvesp4RecomMaxSoc : 64|16@1+ (0.0015625,0) [0|100.3984375] "%"  PCM
 SG_ Hvesp4RecomMinSoc : 48|16@1+ (0.0015625,0) [0|100.3984375] "%"  PCM
 SG_ Hvesp4RecomMaxOpV : 32|16@1+ (0.05,0) [0|3212.75] "V"  PCM
 SG_ Hvesp4RecomMinOpV : 16|16@1+ (0.05,0) [0|3212.75] "V"  PCM
 SG_ Hvesp4NomV : 0|16@1+ (0.05,0) [0|3212.75] "V"  PCM

BO_ 2566607495 HVESP5CFG_87: 16 NODE_87
 SG_ Hvesp5CellVminLim : 120|8@1+ (0.02044,0) [0|5.11] "V"  PCM
 SG_ Hvesp5CellVmaxLim : 112|8@1+ (0.02044,0) [0|5.11] "V"  PCM
 SG_ Hvesp5RecomMinOpTemp : 96|16@1+ (0.03125,-273) [-273|1734.96875] "�C"  PCM
 SG_ Hvesp5RecomMaxOpTemp : 80|16@1+ (0.03125,-273) [-273|1734.96875] "�C"  PCM
 SG_ Hvesp5RecomMaxSoc : 64|16@1+ (0.0015625,0) [0|100.3984375] "%"  PCM
 SG_ Hvesp5RecomMinSoc : 48|16@1+ (0.0015625,0) [0|100.3984375] "%"  PCM
 SG_ Hvesp5RecomMaxOpV : 32|16@1+ (0.05,0) [0|3212.75] "V"  PCM
 SG_ Hvesp5RecomMinOpV : 16|16@1+ (0.05,0) [0|3212.75] "V"  PCM
 SG_ Hvesp5NomV : 0|16@1+ (0.05,0) [0|3212.75] "V"  PCM

CM_ BO_ 2565865739 "- FMS Trans.Rate=100ms";
CM_ BO_ 2566831883 "- SGW MY19 routes this message on DTB only for retrocompatibily of DTCO 3.x and DTCO2.x";
CM_ BO_ 2566841088 "- Multipacket message handled by SAE Transport Protocol (J1939/21, par 5.10, Multipacket Broadcast with TP.CM/BAM, TP.DT)
-  Sae Trans.Rate=5000ms/OnChange";
CM_ BO_ 2566767877 "- Multipacket message handled by SAE Transport Protocol (J1939/21, par 5.10, Multipacket Broadcast with TP.CM/BAM, TP.DT)
-  Variable Message Length, maximum value used for dbc generation";
CM_ SG_ 2566767877 EcuHwId "- 15+1 characters maximum, (IVECO Std. 18-2253)
-  Variable signal length, 8 bits used for dbc generation only";
CM_ SG_ 2566767877 EcuManName "- 15+1 characters maximum, (IVECO Std. 18-2253)
-  Variable signal length, 8 bits used for dbc generation only";
CM_ SG_ 2566767877 EcuType "- 1 character, Empty field, delimiter only (IVECO Std. 18-2253)";
CM_ SG_ 2566767877 EcuLoc "- 10+1 characters maximum; concatenation of Subnetwork Identifiers Hex number in ASCII (IVECO Std. 18-2254)
-  Variable signal length, 8 bits used for dbc generation only";
CM_ SG_ 2566767877 EcuSn "- 10+1 characters maximum; Manufacturer assigned (IVECO Std. 18-2253)
-  Variable signal length, 8 bits used for dbc generation only";
CM_ SG_ 2566767877 EcuPn "- 15+1 characters maximum; Iveco assigned ECU Hw+Sw P/N (IVECO Std. 18-2253)
-  Variable signal length, 8 bits used for dbc generation only";
CM_ BO_ 2566767879 "- Multipacket message handled by SAE Transport Protocol (J1939/21, par 5.10, Multipacket Broadcast with TP.CM/BAM, TP.DT)
-  Transport Protocol with Control Flow  (RTS, CTS, EndOfMsgAck, Conn_Abort) shall be also supported by the receiver if the multipacket message has been solicited by a Destination Specific Request
-  Variable Message Length, maximum value used for dbc generation";
CM_ SG_ 2566767879 EcuHwId_FDC507 "- 15+1 characters maximum, (IVECO Std. 18-2253)
-  Variable signal length, 8 bits used for dbc generation only";
CM_ SG_ 2566767879 EcuManName_FDC507 "- 15+1 characters maximum, (IVECO Std. 18-2253)
-  Variable signal length, 8 bits used for dbc generation only";
CM_ SG_ 2566767879 EcuType_FDC507 "- 1 character, Empty field, delimiter only (IVECO Std. 18-2253)";
CM_ SG_ 2566767879 EcuLoc_FDC507 "- 10+1 characters maximum; concatenation of Subnetwork Identifiers Hex number in ASCII (IVECO Std. 18-2254)
-  Variable signal length, 8 bits used for dbc generation only";
CM_ SG_ 2566767879 EcuSn_FDC507 "- 10+1 characters maximum; Manufacturer assigned (IVECO Std. 18-2253)
-  Variable signal length, 8 bits used for dbc generation only";
CM_ SG_ 2566767879 EcuPn_FDC507 "- 15+1 characters maximum; Iveco assigned ECU Hw+Sw P/N (IVECO Std. 18-2253)
-  Variable signal length, 8 bits used for dbc generation only";
CM_ BO_ 2566767895 "- Multipacket message handled by SAE Transport Protocol (J1939/21, par 5.10, Multipacket Broadcast with TP.CM/BAM, TP.DT)
-  Variable Message Length, maximum value used for dbc generation";
CM_ SG_ 2566767895 EcuHwId_FDC517 "- 15+1 characters maximum, (IVECO Std. 18-2253)
-  Variable signal length, 8 bits used for dbc generation only";
CM_ SG_ 2566767895 EcuManName_FDC517 "- 15+1 characters maximum, (IVECO Std. 18-2253)
-  Variable signal length, 8 bits used for dbc generation only";
CM_ SG_ 2566767895 EcuType_FDC517 "- 1 character, Empty field, delimiter only (IVECO Std. 18-2253)";
CM_ SG_ 2566767895 EcuLoc_FDC517 "- 10+1 characters maximum; concatenation of Subnetwork Identifiers Hex number in ASCII (IVECO Std. 18-2254)
-  Variable signal length, 8 bits used for dbc generation only";
CM_ SG_ 2566767895 EcuSn_FDC517 "- 10+1 characters maximum; Manufacturer assigned (IVECO Std. 18-2253)
-  Variable signal length, 8 bits used for dbc generation only";
CM_ SG_ 2566767895 EcuPn_FDC517 "- 15+1 characters maximum; Iveco assigned ECU Hw+Sw P/N (IVECO Std. 18-2253)
-  Variable signal length, 8 bits used for dbc generation only";
CM_ BO_ 2566767898 "- Multipacket message handled by SAE Transport Protocol (J1939/21, par 5.10, Multipacket Broadcast with TP.CM/BAM, TP.DT)
-  Transport Protocol with Control Flow  (RTS, CTS, EndOfMsgAck, Conn_Abort) shall be also supported by the receiver if the multipacket message has been solicited by a Destination Specific Request
-  Variable Message Length, maximum value used for dbc generation";
CM_ SG_ 2566767898 EcuHwId_FDC51A "- 15+1 characters maximum, (IVECO Std. 18-2253)
-  Variable signal length, 8 bits used for dbc generation only";
CM_ SG_ 2566767898 EcuManName_FDC51A "- 15+1 characters maximum, (IVECO Std. 18-2253)
-  Variable signal length, 8 bits used for dbc generation only";
CM_ SG_ 2566767898 EcuType_FDC51A "- 1 character, Empty field, delimiter only (IVECO Std. 18-2253)";
CM_ SG_ 2566767898 EcuLoc_FDC51A "- 10+1 characters maximum; concatenation of Subnetwork Identifiers Hex number in ASCII (IVECO Std. 18-2254)
-  Variable signal length, 8 bits used for dbc generation only";
CM_ SG_ 2566767898 EcuSn_FDC51A "- 10+1 characters maximum; Manufacturer assigned (IVECO Std. 18-2253)
-  Variable signal length, 8 bits used for dbc generation only";
CM_ SG_ 2566767898 EcuPn_FDC51A "- 15+1 characters maximum; Iveco assigned ECU Hw+Sw P/N (IVECO Std. 18-2253)
-  Variable signal length, 8 bits used for dbc generation only";
CM_ BO_ 2566767901 "- Multipacket message handled by SAE Transport Protocol (J1939/21, par 5.10, Multipacket Broadcast with TP.CM/BAM, TP.DT)
-  Transport Protocol with Control Flow  (RTS, CTS, EndOfMsgAck, Conn_Abort) shall be also supported by the receiver if the multipacket message has been solicited by a Destination Specific Request
-  Variable Message Length, maximum value used for dbc generation";
CM_ SG_ 2566767901 EcuHwId_FDC51D "- 15+1 characters maximum, (IVECO Std. 18-2253)
-  Variable signal length, 8 bits used for dbc generation only";
CM_ SG_ 2566767901 EcuManName_FDC51D "- 15+1 characters maximum, (IVECO Std. 18-2253)
-  Variable signal length, 8 bits used for dbc generation only";
CM_ SG_ 2566767901 EcuType_FDC51D "- 1 character, Empty field, delimiter only (IVECO Std. 18-2253)";
CM_ SG_ 2566767901 EcuLoc_FDC51D "- 10+1 characters maximum; concatenation of Subnetwork Identifiers Hex number in ASCII (IVECO Std. 18-2254)
-  Variable signal length, 8 bits used for dbc generation only";
CM_ SG_ 2566767901 EcuSn_FDC51D "- 10+1 characters maximum; Manufacturer assigned (IVECO Std. 18-2253)
-  Variable signal length, 8 bits used for dbc generation only";
CM_ SG_ 2566767901 EcuPn_FDC51D "- 15+1 characters maximum; Iveco assigned ECU Hw+Sw P/N (IVECO Std. 18-2253)
-  Variable signal length, 8 bits used for dbc generation only";
CM_ BO_ 2566767908 "- Multipacket message handled by SAE Transport Protocol (J1939/21, par 5.10, Multipacket Broadcast with TP.CM/BAM, TP.DT)
-  Transport Protocol with Control Flow  (RTS, CTS, EndOfMsgAck, Conn_Abort) shall be also supported by the receiver if the multipacket message has been solicited by a Destination Specific Request
-  Variable Message Length, maximum value used for dbc generation";
CM_ SG_ 2566767908 EcuHwId_FDC524 "- 15+1 characters maximum, (IVECO Std. 18-2253)
-  Variable signal length, 8 bits used for dbc generation only";
CM_ SG_ 2566767908 EcuManName_FDC524 "- 15+1 characters maximum, (IVECO Std. 18-2253)
-  Variable signal length, 8 bits used for dbc generation only";
CM_ SG_ 2566767908 EcuType_FDC524 "- 1 character, Empty field, delimiter only (IVECO Std. 18-2253)";
CM_ SG_ 2566767908 EcuLoc_FDC524 "- 10+1 characters maximum; concatenation of Subnetwork Identifiers Hex number in ASCII (IVECO Std. 18-2254)
-  Variable signal length, 8 bits used for dbc generation only";
CM_ SG_ 2566767908 EcuSn_FDC524 "- 10+1 characters maximum; Manufacturer assigned (IVECO Std. 18-2253)
-  Variable signal length, 8 bits used for dbc generation only";
CM_ SG_ 2566767908 EcuPn_FDC524 "- 15+1 characters maximum; Iveco assigned ECU Hw+Sw P/N (IVECO Std. 18-2253)
-  Variable signal length, 8 bits used for dbc generation only";
CM_ BO_ 2566767911 "- Multipacket message handled by SAE Transport Protocol (J1939/21, par 5.10, Multipacket Broadcast with TP.CM/BAM, TP.DT)
-  Transport Protocol with Control Flow  (RTS, CTS, EndOfMsgAck, Conn_Abort) shall be also supported by the receiver if the multipacket message has been solicited by a Destination Specific Request
-  Variable Message Length, maximum value used for dbc generation";
CM_ SG_ 2566767911 EcuHwId_FDC527 "- 15+1 characters maximum, (IVECO Std. 18-2253)
-  Variable signal length, 8 bits used for dbc generation only";
CM_ SG_ 2566767911 EcuManName_FDC527 "- 15+1 characters maximum, (IVECO Std. 18-2253)
-  Variable signal length, 8 bits used for dbc generation only";
CM_ SG_ 2566767911 EcuType_FDC527 "- 1 character, Empty field, delimiter only (IVECO Std. 18-2253)";
CM_ SG_ 2566767911 EcuLoc_FDC527 "- 10+1 characters maximum; concatenation of Subnetwork Identifiers Hex number in ASCII (IVECO Std. 18-2254)
-  Variable signal length, 8 bits used for dbc generation only";
CM_ SG_ 2566767911 EcuSn_FDC527 "- 10+1 characters maximum; Manufacturer assigned (IVECO Std. 18-2253)
-  Variable signal length, 8 bits used for dbc generation only";
CM_ SG_ 2566767911 EcuPn_FDC527 "- 15+1 characters maximum; Iveco assigned ECU Hw+Sw P/N (IVECO Std. 18-2253)
-  Variable signal length, 8 bits used for dbc generation only";
CM_ BO_ 2566767919 "- Multipacket message handled by SAE Transport Protocol (J1939/21, par 5.10, Multipacket Broadcast with TP.CM/BAM, TP.DT)
-  Transport Protocol with Control Flow  (RTS, CTS, EndOfMsgAck, Conn_Abort) shall be also supported by the receiver if the multipacket message has been solicited by a Destination Specific Request
-  Variable Message Length, maximum value used for dbc generation";
CM_ SG_ 2566767919 EcuHwId_FDC52F "- 15+1 characters maximum, (IVECO Std. 18-2253)
-  Variable signal length, 8 bits used for dbc generation only";
CM_ SG_ 2566767919 EcuManName_FDC52F "- 15+1 characters maximum, (IVECO Std. 18-2253)
-  Variable signal length, 8 bits used for dbc generation only";
CM_ SG_ 2566767919 EcuLoc_FDC52F "- 10+1 characters maximum; concatenation of Subnetwork Identifiers Hex number in ASCII (IVECO Std. 18-2254)
-  Variable signal length, 8 bits used for dbc generation only";
CM_ SG_ 2566767919 EcuSn_FDC52F "- 10+1 characters maximum; Manufacturer assigned (IVECO Std. 18-2253)
-  Variable signal length, 8 bits used for dbc generation only";
CM_ SG_ 2566767919 EcuPn_FDC52F "- 15+1 characters maximum; Iveco assigned ECU Hw+Sw P/N (IVECO Std. 18-2253)
-  Variable signal length, 8 bits used for dbc generation only";
CM_ BO_ 2566767920 "- Multipacket message handled by SAE Transport Protocol (J1939/21, par 5.10, Multipacket Broadcast with TP.CM/BAM, TP.DT)
-  Transport Protocol with Control Flow  (RTS, CTS, EndOfMsgAck, Conn_Abort) shall be also supported by the receiver if the multipacket message has been solicited by a Destination Specific Request
-  Variable Message Length, maximum value used for dbc generation";
CM_ SG_ 2566767920 EcuHwId_FDC530 "- 15+1 characters maximum, (IVECO Std. 18-2253)
-  Variable signal length, 8 bits used for dbc generation only";
CM_ SG_ 2566767920 EcuManName_FDC530 "- 15+1 characters maximum, (IVECO Std. 18-2253)
-  Variable signal length, 8 bits used for dbc generation only";
CM_ SG_ 2566767920 EcuType_FDC530 "- 1 character, Empty field, delimiter only (IVECO Std. 18-2253)";
CM_ SG_ 2566767920 EcuLoc_FDC530 "- 10+1 characters maximum; concatenation of Subnetwork Identifiers Hex number in ASCII (IVECO Std. 18-2254)
-  Variable signal length, 8 bits used for dbc generation only";
CM_ SG_ 2566767920 EcuSn_FDC530 "- 10+1 characters maximum; Manufacturer assigned (IVECO Std. 18-2253)
-  Variable signal length, 8 bits used for dbc generation only";
CM_ SG_ 2566767920 EcuPn_FDC530 "- 15+1 characters maximum; Iveco assigned ECU Hw+Sw P/N (IVECO Std. 18-2253)
-  Variable signal length, 8 bits used for dbc generation only";
CM_ BO_ 2566767923 "- Multipacket message handled by SAE Transport Protocol (J1939/21, par 5.10, Multipacket Broadcast with TP.CM/BAM, TP.DT)
-  Transport Protocol with Control Flow  (RTS, CTS, EndOfMsgAck, Conn_Abort) shall be also supported by the receiver if the multipacket message has been solicited by a Destination Specific Request
-  Variable Message Length, maximum value used for dbc generation";
CM_ SG_ 2566767923 EcuHwId_FDC533 "- 15+1 characters maximum, (IVECO Std. 18-2253)
-  Variable signal length, 8 bits used for dbc generation only";
CM_ SG_ 2566767923 EcuManName_FDC533 "- 15+1 characters maximum, (IVECO Std. 18-2253)
-  Variable signal length, 8 bits used for dbc generation only";
CM_ SG_ 2566767923 EcuType_FDC533 "- 1 character, Empty field, delimiter only (IVECO Std. 18-2253)";
CM_ SG_ 2566767923 EcuLoc_FDC533 "- 10+1 characters maximum; concatenation of Subnetwork Identifiers Hex number in ASCII (IVECO Std. 18-2254)
-  Variable signal length, 8 bits used for dbc generation only";
CM_ SG_ 2566767923 EcuSn_FDC533 "- 10+1 characters maximum; Manufacturer assigned (IVECO Std. 18-2253)
-  Variable signal length, 8 bits used for dbc generation only";
CM_ SG_ 2566767923 EcuPn_FDC533 "- 15+1 characters maximum; Iveco assigned ECU Hw+Sw P/N (IVECO Std. 18-2253)
-  Variable signal length, 8 bits used for dbc generation only";
CM_ BO_ 2566767937 "- Multipacket message handled by SAE Transport Protocol (J1939/21, par 5.10, Multipacket Broadcast with TP.CM/BAM, TP.DT)
-  Transport Protocol with Control Flow  (RTS, CTS, EndOfMsgAck, Conn_Abort) shall be also supported by the receiver if the multipacket message has been solicited by a Destination Specific Request
-  Variable Message Length, maximum value used for dbc generation";
CM_ SG_ 2566767937 EcuHwId_FDC541 "- 15+1 characters maximum, (IVECO Std. 18-2253)
-  Variable signal length, 8 bits used for dbc generation only";
CM_ SG_ 2566767937 EcuManName_FDC541 "- 15+1 characters maximum, (IVECO Std. 18-2253)
-  Variable signal length, 8 bits used for dbc generation only";
CM_ SG_ 2566767937 EcuType_FDC541 "- 1 character, Empty field, delimiter only (IVECO Std. 18-2253)";
CM_ SG_ 2566767937 EcuLoc_FDC541 "- 10+1 characters maximum; concatenation of Subnetwork Identifiers Hex number in ASCII (IVECO Std. 18-2254)
-  Variable signal length, 8 bits used for dbc generation only";
CM_ SG_ 2566767937 EcuSn_FDC541 "- 10+1 characters maximum; Manufacturer assigned (IVECO Std. 18-2253)
-  Variable signal length, 8 bits used for dbc generation only";
CM_ SG_ 2566767937 EcuPn_FDC541 "- 15+1 characters maximum; Iveco assigned ECU Hw+Sw P/N (IVECO Std. 18-2253)
-  Variable signal length, 8 bits used for dbc generation only";
CM_ BO_ 2566767945 "- Multipacket message handled by SAE Transport Protocol (J1939/21, par 5.10, Multipacket Broadcast with TP.CM/BAM, TP.DT)
-  Transport Protocol with Control Flow  (RTS, CTS, EndOfMsgAck, Conn_Abort) shall be also supported by the receiver if the multipacket message has been solicited by a Destination Specific Request
-  Variable Message Length, maximum value used for dbc generation";
CM_ SG_ 2566767945 EcuHwId_FDC549 "- 15+1 characters maximum, (IVECO Std. 18-2253)
-  Variable signal length, 8 bits used for dbc generation only";
CM_ SG_ 2566767945 EcuManName_FDC549 "- 15+1 characters maximum, (IVECO Std. 18-2253)
-  Variable signal length, 8 bits used for dbc generation only";
CM_ SG_ 2566767945 EcuType_FDC549 "- 1 character, Empty field, delimiter only (IVECO Std. 18-2253)";
CM_ SG_ 2566767945 EcuLoc_FDC549 "- 10+1 characters maximum; concatenation of Subnetwork Identifiers Hex number in ASCII (IVECO Std. 18-2254)
-  Variable signal length, 8 bits used for dbc generation only";
CM_ SG_ 2566767945 EcuSn_FDC549 "- 10+1 characters maximum; Manufacturer assigned (IVECO Std. 18-2253)
-  Variable signal length, 8 bits used for dbc generation only";
CM_ SG_ 2566767945 EcuPn_FDC549 "- 15+1 characters maximum; Iveco assigned ECU Hw+Sw P/N (IVECO Std. 18-2253)
-  Variable signal length, 8 bits used for dbc generation only";
CM_ BO_ 2566767946 "- Multipacket message handled by SAE Transport Protocol (J1939/21, par 5.10, Multipacket Broadcast with TP.CM/BAM, TP.DT)
-  Transport Protocol with Control Flow  (RTS, CTS, EndOfMsgAck, Conn_Abort) shall be also supported by the receiver if the multipacket message has been solicited by a Destination Specific Request
-  Variable Message Length, maximum value used for dbc generation";
CM_ SG_ 2566767946 EcuHwId_FDC54A "- 15+1 characters maximum, (IVECO Std. 18-2253)
-  Variable signal length, 8 bits used for dbc generation only";
CM_ SG_ 2566767946 EcuManName_FDC54A "- 15+1 characters maximum, (IVECO Std. 18-2253)
-  Variable signal length, 8 bits used for dbc generation only";
CM_ SG_ 2566767946 EcuType_FDC54A "- 1 character, Empty field, delimiter only (IVECO Std. 18-2253)";
CM_ SG_ 2566767946 EcuLoc_FDC54A "- 10+1 characters maximum; concatenation of Subnetwork Identifiers Hex number in ASCII (IVECO Std. 18-2254)
-  Variable signal length, 8 bits used for dbc generation only";
CM_ SG_ 2566767946 EcuSn_FDC54A "- 10+1 characters maximum; Manufacturer assigned (IVECO Std. 18-2253)
-  Variable signal length, 8 bits used for dbc generation only";
CM_ SG_ 2566767946 EcuPn_FDC54A "- 15+1 characters maximum; Iveco assigned ECU Hw+Sw P/N (IVECO Std. 18-2253)
-  Variable signal length, 8 bits used for dbc generation only";
CM_ BO_ 2566767949 "- Multipacket message handled by SAE Transport Protocol (J1939/21, par 5.10, Multipacket Broadcast with TP.CM/BAM, TP.DT)
-  Transport Protocol with Control Flow  (RTS, CTS, EndOfMsgAck, Conn_Abort) shall be also supported by the receiver if the multipacket message has been solicited by a Destination Specific Request
-  Variable Message Length, maximum value used for dbc generation";
CM_ SG_ 2566767949 EcuHwId_FDC54D "- 15+1 characters maximum, (IVECO Std. 18-2253)
-  Variable signal length, 8 bits used for dbc generation only";
CM_ SG_ 2566767949 EcuManName_FDC54D "- 15+1 characters maximum, (IVECO Std. 18-2253)
-  Variable signal length, 8 bits used for dbc generation only";
CM_ SG_ 2566767949 EcuType_FDC54D "- 1 character, Empty field, delimiter only (IVECO Std. 18-2253)";
CM_ SG_ 2566767949 EcuLoc_FDC54D "- 10+1 characters maximum; concatenation of Subnetwork Identifiers Hex number in ASCII (IVECO Std. 18-2254)
-  Variable signal length, 8 bits used for dbc generation only";
CM_ SG_ 2566767949 EcuSn_FDC54D "- 10+1 characters maximum; Manufacturer assigned (IVECO Std. 18-2253)
-  Variable signal length, 8 bits used for dbc generation only";
CM_ SG_ 2566767949 EcuPn_FDC54D "- 15+1 characters maximum; Iveco assigned ECU Hw+Sw P/N (IVECO Std. 18-2253)
-  Variable signal length, 8 bits used for dbc generation only";
CM_ BO_ 2566767955 "- Multipacket message handled by SAE Transport Protocol (J1939/21, par 5.10, Multipacket Broadcast with TP.CM/BAM, TP.DT)
-  Transport Protocol with Control Flow  (RTS, CTS, EndOfMsgAck, Conn_Abort) shall be also supported by the receiver if the multipacket message has been solicited by a Destination Specific Request
-  Variable Message Length, maximum value used for dbc generation";
CM_ SG_ 2566767955 EcuHwId_FDC553 "- 15+1 characters maximum, (IVECO Std. 18-2253)
-  Variable signal length, 8 bits used for dbc generation only";
CM_ SG_ 2566767955 EcuManName_FDC553 "- 15+1 characters maximum, (IVECO Std. 18-2253)
-  Variable signal length, 8 bits used for dbc generation only";
CM_ SG_ 2566767955 EcuType_FDC553 "- 1 character, Empty field, delimiter only (IVECO Std. 18-2253)";
CM_ SG_ 2566767955 EcuLoc_FDC553 "- 10+1 characters maximum; concatenation of Subnetwork Identifiers Hex number in ASCII (IVECO Std. 18-2254)
-  Variable signal length, 8 bits used for dbc generation only";
CM_ SG_ 2566767955 EcuSn_FDC553 "- 10+1 characters maximum; Manufacturer assigned (IVECO Std. 18-2253)
-  Variable signal length, 8 bits used for dbc generation only";
CM_ SG_ 2566767955 EcuPn_FDC553 "- 15+1 characters maximum; Iveco assigned ECU Hw+Sw P/N (IVECO Std. 18-2253)
-  Variable signal length, 8 bits used for dbc generation only";
CM_ BO_ 2566767992 "- Multipacket message handled by SAE Transport Protocol (J1939/21, par 5.10, Multipacket Broadcast with TP.CM/BAM, TP.DT)
-  Transport Protocol with Control Flow  (RTS, CTS, EndOfMsgAck, Conn_Abort) shall be also supported by the receiver if the multipacket message has been solicited by a Destination Specific Request
-  Variable Message Length, maximum value used for dbc generation";
CM_ SG_ 2566767992 EcuHwId_FDC578 "- 15+1 characters maximum, (IVECO Std. 18-2253)
-  Variable signal length, 8 bits used for dbc generation only";
CM_ SG_ 2566767992 EcuManName_FDC578 "- 15+1 characters maximum, (IVECO Std. 18-2253)
-  Variable signal length, 8 bits used for dbc generation only";
CM_ SG_ 2566767992 EcuType_FDC578 "- 1 character, Empty field, delimiter only (IVECO Std. 18-2253)";
CM_ SG_ 2566767992 EcuLoc_FDC578 "- 10+1 characters maximum; concatenation of Subnetwork Identifiers Hex number in ASCII (IVECO Std. 18-2254)
-  Variable signal length, 8 bits used for dbc generation only";
CM_ SG_ 2566767992 EcuSn_FDC578 "- 10+1 characters maximum; Manufacturer assigned (IVECO Std. 18-2253)
-  Variable signal length, 8 bits used for dbc generation only";
CM_ SG_ 2566767992 EcuPn_FDC578 "- 15+1 characters maximum; Iveco assigned ECU Hw+Sw P/N (IVECO Std. 18-2253)
-  Variable signal length, 8 bits used for dbc generation only";
CM_ BO_ 2566767996 "- Multipacket message handled by SAE Transport Protocol (J1939/21, par 5.10, Multipacket Broadcast with TP.CM/BAM, TP.DT)
-  Transport Protocol with Control Flow  (RTS, CTS, EndOfMsgAck, Conn_Abort) shall be also supported by the receiver if the multipacket message has been solicited by a Destination Specific Request
-  Variable Message Length, maximum value used for dbc generation";
CM_ SG_ 2566767996 EcuHwId_FDC57C "- 15+1 characters maximum, (IVECO Std. 18-2253)
-  Variable signal length, 8 bits used for dbc generation only";
CM_ SG_ 2566767996 EcuManName_FDC57C "- 15+1 characters maximum, (IVECO Std. 18-2253)
-  Variable signal length, 8 bits used for dbc generation only";
CM_ SG_ 2566767996 EcuType_FDC57C "- 1 character, Empty field, delimiter only (IVECO Std. 18-2253)";
CM_ SG_ 2566767996 EcuLoc_FDC57C "- 10+1 characters maximum; concatenation of Subnetwork Identifiers Hex number in ASCII (IVECO Std. 18-2254)
-  Variable signal length, 8 bits used for dbc generation only";
CM_ SG_ 2566767996 EcuSn_FDC57C "- 10+1 characters maximum; Manufacturer assigned (IVECO Std. 18-2253)
-  Variable signal length, 8 bits used for dbc generation only";
CM_ SG_ 2566767996 EcuPn_FDC57C "- 15+1 characters maximum; Iveco assigned ECU Hw+Sw P/N (IVECO Std. 18-2253)
-  Variable signal length, 8 bits used for dbc generation only";
CM_ BO_ 2566768110 "- Multipacket message handled by SAE Transport Protocol (J1939/21, par 5.10, Multipacket Broadcast with TP.CM/BAM, TP.DT)
-  Transport Protocol with Control Flow  (RTS, CTS, EndOfMsgAck, Conn_Abort) shall be also supported by the receiver if the multipacket message has been solicited by a Destination Specific Request
-  Variable Message Length, maximum value used for dbc generation";
CM_ SG_ 2566768110 EcuPn_FDC5EE "- 15+1 characters maximum; Iveco assigned ECU Hw+Sw P/N (IVECO Std. 18-2253)
-  Variable signal length, 8 bits used for dbc generation only";
CM_ BO_ 2566768111 "- Multipacket message handled by SAE Transport Protocol (J1939/21, par 5.10, Multipacket Broadcast with TP.CM/BAM, TP.DT)
-  Transport Protocol with Control Flow  (RTS, CTS, EndOfMsgAck, Conn_Abort) shall be also supported by the receiver if the multipacket message has been solicited by a Destination Specific Request
-  Variable Message Length, maximum value used for dbc generation";
CM_ SG_ 2566768111 EcuHwId_FDC5EF "- 15+1 characters maximum, (IVECO Std. 18-2253)
-  Variable signal length, 8 bits used for dbc generation only";
CM_ SG_ 2566768111 EcuManName_FDC5EF "- 15+1 characters maximum, (IVECO Std. 18-2253)
-  Variable signal length, 8 bits used for dbc generation only";
CM_ SG_ 2566768111 EcuType_FDC5EF "- 1 character, Empty field, delimiter only (IVECO Std. 18-2253)";
CM_ SG_ 2566768111 EcuLoc_FDC5EF "- 10+1 characters maximum; concatenation of Subnetwork Identifiers Hex number in ASCII (IVECO Std. 18-2254)
-  Variable signal length, 8 bits used for dbc generation only";
CM_ SG_ 2566768111 EcuSn_FDC5EF "- 10+1 characters maximum; Manufacturer assigned (IVECO Std. 18-2253)
-  Variable signal length, 8 bits used for dbc generation only";
CM_ SG_ 2566768111 EcuPn_FDC5EF "- 15+1 characters maximum; Iveco assigned ECU Hw+Sw P/N (IVECO Std. 18-2253)
-  Variable signal length, 8 bits used for dbc generation only";
CM_ BO_ 2566768114 "- Multipacket message handled by SAE Transport Protocol (J1939/21, par 5.10, Multipacket Broadcast with TP.CM/BAM, TP.DT)
-  Transport Protocol with Control Flow  (RTS, CTS, EndOfMsgAck, Conn_Abort) shall be also supported by the receiver if the multipacket message has been solicited by a Destination Specific Request
-  Variable Message Length, maximum value used for dbc generation";
CM_ SG_ 2566768114 EcuHwId_FDC5F2 "- 15+1 characters maximum, (IVECO Std. 18-2253)
-  Variable signal length, 8 bits used for dbc generation only";
CM_ SG_ 2566768114 EcuManName_FDC5F2 "- 15+1 characters maximum, (IVECO Std. 18-2253)
-  Variable signal length, 8 bits used for dbc generation only";
CM_ SG_ 2566768114 EcuType_FDC5F2 "- 1 character, Empty field, delimiter only (IVECO Std. 18-2253)";
CM_ SG_ 2566768114 EcuLoc_FDC5F2 "- 10+1 characters maximum; concatenation of Subnetwork Identifiers Hex number in ASCII (IVECO Std. 18-2254)
-  Variable signal length, 8 bits used for dbc generation only";
CM_ SG_ 2566768114 EcuSn_FDC5F2 "- 10+1 characters maximum; Manufacturer assigned (IVECO Std. 18-2253)
-  Variable signal length, 8 bits used for dbc generation only";
CM_ SG_ 2566768114 EcuPn_FDC5F2 "- 15+1 characters maximum; Iveco assigned ECU Hw+Sw P/N (IVECO Std. 18-2253)
-  Variable signal length, 8 bits used for dbc generation only";
CM_ BO_ 2566768115 "- Multipacket message handled by SAE Transport Protocol (J1939/21, par 5.10, Multipacket Broadcast with TP.CM/BAM, TP.DT)
-  Transport Protocol with Control Flow  (RTS, CTS, EndOfMsgAck, Conn_Abort) shall be also supported by the receiver if the multipacket message has been solicited by a Destination Specific Request
-  Variable Message Length, maximum value used for dbc generation";
CM_ SG_ 2566768115 EcuHwId_FDC5F3 "- 15+1 characters maximum, (IVECO Std. 18-2253)
-  Variable signal length, 8 bits used for dbc generation only";
CM_ SG_ 2566768115 EcuManName_FDC5F3 "- 15+1 characters maximum, (IVECO Std. 18-2253)
-  Variable signal length, 8 bits used for dbc generation only";
CM_ SG_ 2566768115 EcuType_FDC5F3 "- 1 character, Empty field, delimiter only (IVECO Std. 18-2253)";
CM_ SG_ 2566768115 EcuLoc_FDC5F3 "- 10+1 characters maximum; concatenation of Subnetwork Identifiers Hex number in ASCII (IVECO Std. 18-2254)
-  Variable signal length, 8 bits used for dbc generation only";
CM_ SG_ 2566768115 EcuSn_FDC5F3 "- 10+1 characters maximum; Manufacturer assigned (IVECO Std. 18-2253)
-  Variable signal length, 8 bits used for dbc generation only";
CM_ SG_ 2566768115 EcuPn_FDC5F3 "- 15+1 characters maximum; Iveco assigned ECU Hw+Sw P/N (IVECO Std. 18-2253)
-  Variable signal length, 8 bits used for dbc generation only";
CM_ SG_ 2566856960 AcComprSts "- Available from EUROV HD Bi-Fuel and EUROV HD Diesel";
CM_ SG_ 2566856960 RegenStsLamp "- Conflicting with EDC2BC - Transmission Neutral Switch";
CM_ SG_ 2566856960 ObdMilSts "- Values 10b (Blinking), 11 (Not Available) not used on Daily and on M&H EuroVI";
CM_ SG_ 2566856960 EngOverTemp "- Values used on ICE (000 No Warning: 001 Warning) on BEV (000 No Warning; 010 Warning)";
CM_ SG_ 2566856960 FuelBlkByImmo "- BCM Stralis MY19 will use the initial value till VCM will transmit the first occurence of the message";
CM_ BO_ 2364539904 "- FMS Trans.Rate=100ms";
CM_ SG_ 2364539904 EngStarterMode "- BCM on Stralis MY19 uses internally 0xF value as initial value for K50 signal alignment status
-  On Daily BEV, value 0101 is used to indicate - Inhibited, Plug connected";
CM_ SG_ 2364539904 EngSpeed "- SAE J1939/73 Freeze Frame parameter";
CM_ SG_ 2364539904 EngTrqMode "- SAE J1939/73 Freeze Frame parameter";
CM_ BO_ 2566767104 "- FMS Trans.Rate=10s
-  SAE Trans.Rate=OnRequest";
CM_ SG_ 2364539648 EngPcLoadAtCurSpeed "- SAE J1939/73 Freeze Frame parameter";
CM_ SG_ 2364539648 AccPedPos1 "- As a deviation from SAE, does not contain the real pedal but a Virtual Pedal calculate from Driver's Demand when Cruise or Speed Limiters control the torque";
CM_ SG_ 2566898290 ApplCnt "- Updated at each EM internal PLC cycle (typically 250ms).";
CM_ SG_ 2566843904 EngCoolTemp "- SAE J1939/73 Freeze Frame parameter";
CM_ BO_ 2633941763 "- SAE Trans.Rate=100ms";
CM_ SG_ 2566801923 TransmMode5Ind "- 00b Normal, 01b Eco, 10b Error, 11b Not available";
CM_ SG_ 2566801923 TransmMode1Ind "- 00b Manual, 01b Automatic, 10b Error, 11b Not available";
CM_ BO_ 2364541955 "- Faster rate when torque converter is unlocked";
CM_ BO_ 2431649578 "- SAE Trans.Rate=50ms / -";
CM_ SG_ 2561223201 LdwEnaCmd "- Used for LC65";
CM_ SG_ 2566749463 AirFiltClog "- For Daily MY2019 this signal is used to report the status of the DPF Filter. For future improvement please consider the signal FMS1_17.EngEmisFilt";
CM_ BO_ 2566896128 "- Bi-Fuel application only";
CM_ BO_ 2566841600 "-  3 Message Variant(s): Transm.Rates 1000, 180000, OnRequest
-  Cyclic Transmission Rate as result of PGN requests
-  SGW requests this PGN with RQST_1D_00
-  Cyclic Transmission Rate as result of PGN requests";
CM_ SG_ 2566841600 EngTotHrOfOp "- SAE J1939/73 Freeze Frame parameter (AG+CE applications)";
BA_DEF_ BO_  "CI_MsgDefinition" STRING ;
BA_DEF_ BO_  "CI_MsgId" INT 0 2147483647;
BA_DEF_ BO_  "CI_MsgName" STRING ;
BA_DEF_ BO_  "GenMsgCycleTime" INT 0 3600000;
BA_DEF_ BO_  "GenMsgCycleTimeFast" INT 0 3600000;
BA_DEF_ BO_  "GenMsgDelayTime" INT 0 3600000;
BA_DEF_ BO_  "GenMsgILSupport" ENUM  "No","Yes";
BA_DEF_ BO_  "GenMsgNrOfRepetition" INT 0 1000000;
BA_DEF_ BO_  "GenMsgRequestable" INT 0 1;
BA_DEF_ BO_  "GenMsgSendType" ENUM  "cyclic","NotUsed","NotUsed","NotUsed","NotUsed","NotUsed","NotUsed","IfActive","noMsgSendType";
BA_DEF_ BO_  "GenMsgStartDelayTime" INT 0 100000;
BA_DEF_ BO_  "TpJ1939VarDlc" ENUM  "No","Yes";
BA_DEF_ BO_  "VFrameFormat" ENUM  "StandardCAN","ExtendedCAN","reserved","J1939PG";
BA_DEF_ SG_  "CI_ParId" STRING ;
BA_DEF_ SG_  "CI_SigId" INT 0 2147483647;
BA_DEF_ SG_  "CI_SigName" STRING ;
BA_DEF_ SG_  "GenSigEVName" STRING ;
BA_DEF_ SG_  "GenSigILSupport" ENUM  "No","Yes";
BA_DEF_ SG_  "GenSigInactiveValue" INT 0 2147483647;
BA_DEF_ SG_  "GenSigSendType" ENUM  "Cyclic","OnWrite","OnWriteWithRepetition","OnChange","OnChangeWithRepetition","IfActive","IfActiveWithRepetition","NoSigSendType";
BA_DEF_ SG_  "GenSigStartValue" INT 0 2147483647;
BA_DEF_ SG_  "GenSigTimeoutTime_PCM" INT 0 3600000;
BA_DEF_ SG_  "GenSigTimeoutTime_SGW" INT 0 3600000;
BA_DEF_ SG_  "SPN" INT 0 524287;
BA_DEF_ SG_  "SigType" ENUM  "Default","Range","RangeSigned","ASCII","Discrete","Control","ReferencePGN","DTC","StringDelimiter","StringLength","StringLengthControl";
BA_DEF_DEF_  "CI_MsgDefinition" "";
BA_DEF_DEF_  "CI_MsgId" 0;
BA_DEF_DEF_  "CI_MsgName" "";
BA_DEF_DEF_  "GenMsgCycleTime" 0;
BA_DEF_DEF_  "GenMsgCycleTimeFast" 0;
BA_DEF_DEF_  "GenMsgDelayTime" 1;
BA_DEF_DEF_  "GenMsgILSupport" "Yes";
BA_DEF_DEF_  "GenMsgNrOfRepetition" 0;
BA_DEF_DEF_  "GenMsgRequestable" 0;
BA_DEF_DEF_  "GenMsgSendType" "noMsgSendType";
BA_DEF_DEF_  "GenMsgStartDelayTime" 0;
BA_DEF_DEF_  "TpJ1939VarDlc" "No";
BA_DEF_DEF_  "VFrameFormat" "J1939PG";
BA_DEF_DEF_  "CI_ParId" "";
BA_DEF_DEF_  "CI_SigId" 0;
BA_DEF_DEF_  "CI_SigName" "";
BA_DEF_DEF_  "GenSigEVName" "Env@Nodename_@Signame";
BA_DEF_DEF_  "GenSigILSupport" "Yes";
BA_DEF_DEF_  "GenSigInactiveValue" 0;
BA_DEF_DEF_  "GenSigSendType" "NoSigSendType";
BA_DEF_DEF_  "GenSigStartValue" 0;
BA_DEF_DEF_  "GenSigTimeoutTime_PCM" 0;
BA_DEF_DEF_  "GenSigTimeoutTime_SGW" 0;
BA_DEF_DEF_  "SPN" 0;
BA_DEF_DEF_  "SigType" "Default";
BA_ "CI_MsgDefinition" BO_ 2565865739 "J1939DA";
BA_ "CI_MsgId" BO_ 2565865739 508;
BA_ "CI_MsgName" BO_ 2565865739 "EBC1 - Electronic Brake Controller 1";
BA_ "GenMsgCycleTime" BO_ 2565865739 20;
BA_ "GenMsgCycleTimeFast" BO_ 2565865739 20;
BA_ "GenMsgDelayTime" BO_ 2565865739 10;
BA_ "GenMsgSendType" BO_ 2565865739 0;
BA_ "GenMsgStartDelayTime" BO_ 2565865739 23;
BA_ "CI_MsgDefinition" BO_ 2566831883 "J1939DA";
BA_ "CI_MsgId" BO_ 2566831883 596;
BA_ "CI_MsgName" BO_ 2566831883 "EBC2 - Wheel Speed Information";
BA_ "GenMsgCycleTime" BO_ 2566831883 100;
BA_ "GenMsgCycleTimeFast" BO_ 2566831883 100;
BA_ "GenMsgDelayTime" BO_ 2566831883 50;
BA_ "GenMsgSendType" BO_ 2566831883 0;
BA_ "GenMsgStartDelayTime" BO_ 2566831883 77;
BA_ "CI_MsgDefinition" BO_ 2566767627 "J1939DA";
BA_ "CI_MsgId" BO_ 2566767627 647;
BA_ "CI_MsgName" BO_ 2566767627 "EBC5 - Electronic Brake Controller 5";
BA_ "GenMsgCycleTime" BO_ 2566767627 100;
BA_ "GenMsgCycleTimeFast" BO_ 2566767627 100;
BA_ "GenMsgDelayTime" BO_ 2566767627 10;
BA_ "GenMsgSendType" BO_ 2566767627 0;
BA_ "GenMsgStartDelayTime" BO_ 2566767627 69;
BA_ "CI_MsgDefinition" BO_ 2566841088 "J1939DA";
BA_ "CI_MsgId" BO_ 2566841088 1965;
BA_ "CI_MsgName" BO_ 2566841088 "EC1 - Engine Configuration 1";
BA_ "GenMsgCycleTime" BO_ 2566841088 1000;
BA_ "GenMsgCycleTimeFast" BO_ 2566841088 1000;
BA_ "GenMsgDelayTime" BO_ 2566841088 500;
BA_ "GenMsgSendType" BO_ 2566841088 0;
BA_ "GenMsgStartDelayTime" BO_ 2566841088 227;
BA_ "CI_MsgDefinition" BO_ 2566767877 "J1939DA";
BA_ "CI_MsgId" BO_ 2566767877 41040;
BA_ "CI_MsgName" BO_ 2566767877 "ECUID_05 - ECU Identification Information";
BA_ "TpJ1939VarDlc" BO_ 2566767877 1;
BA_ "CI_MsgDefinition" BO_ 2566767879 "J1939DA";
BA_ "CI_MsgId" BO_ 2566767879 38534;
BA_ "CI_MsgName" BO_ 2566767879 "ECUID_07 - ECU Identification Information";
BA_ "TpJ1939VarDlc" BO_ 2566767879 1;
BA_ "CI_MsgDefinition" BO_ 2566767895 "J1939DA";
BA_ "CI_MsgId" BO_ 2566767895 25877;
BA_ "CI_MsgName" BO_ 2566767895 "ECUID_17 - ECU Identification Information";
BA_ "TpJ1939VarDlc" BO_ 2566767895 1;
BA_ "CI_MsgDefinition" BO_ 2566767898 "J1939DA";
BA_ "CI_MsgId" BO_ 2566767898 34500;
BA_ "CI_MsgName" BO_ 2566767898 "ECUID_1A - ECU Identification Information";
BA_ "TpJ1939VarDlc" BO_ 2566767898 1;
BA_ "CI_MsgDefinition" BO_ 2566767901 "J1939DA";
BA_ "CI_MsgId" BO_ 2566767901 25898;
BA_ "CI_MsgName" BO_ 2566767901 "ECUID_1D - ECU Identification Information";
BA_ "TpJ1939VarDlc" BO_ 2566767901 1;
BA_ "CI_MsgDefinition" BO_ 2566767908 "J1939DA";
BA_ "CI_MsgId" BO_ 2566767908 38541;
BA_ "CI_MsgName" BO_ 2566767908 "ECUID_24 - ECU Identification Information";
BA_ "TpJ1939VarDlc" BO_ 2566767908 1;
BA_ "CI_MsgDefinition" BO_ 2566767911 "J1939DA";
BA_ "CI_MsgId" BO_ 2566767911 25912;
BA_ "CI_MsgName" BO_ 2566767911 "ECUID_27 - ECU Identification Information";
BA_ "TpJ1939VarDlc" BO_ 2566767911 1;
BA_ "CI_MsgDefinition" BO_ 2566767919 "J1939DA";
BA_ "CI_MsgId" BO_ 2566767919 25926;
BA_ "CI_MsgName" BO_ 2566767919 "ECUID_2F - ECU Identification Information";
BA_ "TpJ1939VarDlc" BO_ 2566767919 1;
BA_ "CI_MsgDefinition" BO_ 2566767920 "J1939DA";
BA_ "CI_MsgId" BO_ 2566767920 39842;
BA_ "CI_MsgName" BO_ 2566767920 "ECUID_30 - ECU Identification Information";
BA_ "GenMsgDelayTime" BO_ 2566767920 10;
BA_ "TpJ1939VarDlc" BO_ 2566767920 1;
BA_ "CI_MsgDefinition" BO_ 2566767923 "J1939DA";
BA_ "CI_MsgId" BO_ 2566767923 25933;
BA_ "CI_MsgName" BO_ 2566767923 "ECUID_33 - ECU Identification Information";
BA_ "TpJ1939VarDlc" BO_ 2566767923 1;
BA_ "CI_MsgDefinition" BO_ 2566767937 "J1939DA";
BA_ "CI_MsgId" BO_ 2566767937 25940;
BA_ "CI_MsgName" BO_ 2566767937 "ECUID_41 - ECU Identification Information";
BA_ "TpJ1939VarDlc" BO_ 2566767937 1;
BA_ "CI_MsgDefinition" BO_ 2566767945 "J1939DA";
BA_ "CI_MsgId" BO_ 2566767945 34507;
BA_ "CI_MsgName" BO_ 2566767945 "ECUID_49 - ECU Identification Information";
BA_ "TpJ1939VarDlc" BO_ 2566767945 1;
BA_ "CI_MsgDefinition" BO_ 2566767946 "J1939DA";
BA_ "CI_MsgId" BO_ 2566767946 25975;
BA_ "CI_MsgName" BO_ 2566767946 "ECUID_4A - ECU Identification Information";
BA_ "TpJ1939VarDlc" BO_ 2566767946 1;
BA_ "CI_MsgDefinition" BO_ 2566767949 "J1939DA";
BA_ "CI_MsgId" BO_ 2566767949 37235;
BA_ "CI_MsgName" BO_ 2566767949 "ECUID_4D - ECU Identification Information";
BA_ "TpJ1939VarDlc" BO_ 2566767949 1;
BA_ "CI_MsgDefinition" BO_ 2566767955 "J1939DA";
BA_ "CI_MsgId" BO_ 2566767955 25989;
BA_ "CI_MsgName" BO_ 2566767955 "ECUID_53 - ECU Identification Information";
BA_ "TpJ1939VarDlc" BO_ 2566767955 1;
BA_ "CI_MsgDefinition" BO_ 2566767992 "J1939DA";
BA_ "CI_MsgId" BO_ 2566767992 40183;
BA_ "CI_MsgName" BO_ 2566767992 "ECUID_78 - ECU Identification Information";
BA_ "TpJ1939VarDlc" BO_ 2566767992 1;
BA_ "CI_MsgDefinition" BO_ 2566767996 "J1939DA";
BA_ "CI_MsgId" BO_ 2566767996 36820;
BA_ "CI_MsgName" BO_ 2566767996 "ECUID_7C - ECU Identification Information";
BA_ "TpJ1939VarDlc" BO_ 2566767996 1;
BA_ "CI_MsgDefinition" BO_ 2566768110 "J1939DA";
BA_ "CI_MsgId" BO_ 2566768110 26031;
BA_ "CI_MsgName" BO_ 2566768110 "ECUID_EE - ECU Identification Information";
BA_ "TpJ1939VarDlc" BO_ 2566768110 1;
BA_ "CI_MsgDefinition" BO_ 2566768111 "J1939DA";
BA_ "CI_MsgId" BO_ 2566768111 34801;
BA_ "CI_MsgName" BO_ 2566768111 "ECUID_EF - ECU Identification Information";
BA_ "TpJ1939VarDlc" BO_ 2566768111 1;
BA_ "CI_MsgDefinition" BO_ 2566768114 "J1939DA";
BA_ "CI_MsgId" BO_ 2566768114 39070;
BA_ "CI_MsgName" BO_ 2566768114 "ECUID_F2 - ECU Identification Information";
BA_ "TpJ1939VarDlc" BO_ 2566768114 1;
BA_ "CI_MsgDefinition" BO_ 2566768115 "J1939DA";
BA_ "CI_MsgId" BO_ 2566768115 33387;
BA_ "CI_MsgName" BO_ 2566768115 "ECUID_F3 - ECU Identification Information";
BA_ "TpJ1939VarDlc" BO_ 2566768115 1;
BA_ "CI_MsgDefinition" BO_ 2566856960 "Iveco SPR1 Proprietary";
BA_ "CI_MsgId" BO_ 2566856960 11354;
BA_ "CI_MsgName" BO_ 2566856960 "Edc2Bc - EDC to Body Controller";
BA_ "GenMsgCycleTime" BO_ 2566856960 50;
BA_ "GenMsgCycleTimeFast" BO_ 2566856960 50;
BA_ "GenMsgDelayTime" BO_ 2566856960 25;
BA_ "GenMsgSendType" BO_ 2566856960 0;
BA_ "GenMsgStartDelayTime" BO_ 2566856960 44;
BA_ "CI_MsgDefinition" BO_ 2364539904 "J1939DA";
BA_ "CI_MsgId" BO_ 2364539904 1783;
BA_ "CI_MsgName" BO_ 2364539904 "EEC1 - Electronic Engine Controller 1";
BA_ "GenMsgCycleTime" BO_ 2364539904 10;
BA_ "GenMsgCycleTimeFast" BO_ 2364539904 10;
BA_ "GenMsgDelayTime" BO_ 2364539904 5;
BA_ "GenMsgSendType" BO_ 2364539904 0;
BA_ "GenMsgStartDelayTime" BO_ 2364539904 4;
BA_ "CI_MsgDefinition" BO_ 2566767104 "J1939DA";
BA_ "CI_MsgId" BO_ 2566767104 1886;
BA_ "CI_MsgName" BO_ 2566767104 "EEC14 - Electronic Engine Controller 14";
BA_ "GenMsgCycleTime" BO_ 2566767104 1000;
BA_ "GenMsgCycleTimeFast" BO_ 2566767104 1000;
BA_ "GenMsgDelayTime" BO_ 2566767104 500;
BA_ "GenMsgSendType" BO_ 2566767104 0;
BA_ "GenMsgStartDelayTime" BO_ 2566767104 171;
BA_ "CI_MsgDefinition" BO_ 2364539648 "J1939DA";
BA_ "CI_MsgId" BO_ 2364539648 1796;
BA_ "CI_MsgName" BO_ 2364539648 "EEC2 - Electronic Engine Controller 2";
BA_ "GenMsgCycleTime" BO_ 2364539648 50;
BA_ "GenMsgCycleTimeFast" BO_ 2364539648 50;
BA_ "GenMsgDelayTime" BO_ 2364539648 25;
BA_ "GenMsgSendType" BO_ 2364539648 0;
BA_ "GenMsgStartDelayTime" BO_ 2364539648 35;
BA_ "CI_MsgDefinition" BO_ 2566840064 "J1939DA";
BA_ "CI_MsgId" BO_ 2566840064 1832;
BA_ "CI_MsgName" BO_ 2566840064 "EEC3 - Electronic Engine Controller 3";
BA_ "GenMsgCycleTime" BO_ 2566840064 250;
BA_ "GenMsgCycleTimeFast" BO_ 2566840064 250;
BA_ "GenMsgDelayTime" BO_ 2566840064 125;
BA_ "GenMsgSendType" BO_ 2566840064 0;
BA_ "GenMsgStartDelayTime" BO_ 2566840064 109;
BA_ "CI_MsgDefinition" BO_ 2566844160 "J1939DA";
BA_ "CI_MsgId" BO_ 2566844160 2041;
BA_ "CI_MsgName" BO_ 2566844160 "EFLP1 - Engine Fluid Level/Pressure 1";
BA_ "GenMsgCycleTime" BO_ 2566844160 500;
BA_ "GenMsgCycleTimeFast" BO_ 2566844160 500;
BA_ "GenMsgDelayTime" BO_ 2566844160 250;
BA_ "GenMsgSendType" BO_ 2566844160 0;
BA_ "GenMsgStartDelayTime" BO_ 2566844160 127;
BA_ "CI_MsgDefinition" BO_ 2566898290 "Iveco SPR2 Proprietary";
BA_ "CI_MsgId" BO_ 2566898290 10961;
BA_ "CI_MsgName" BO_ 2566898290 "EmCmd - Expansion Module Command";
BA_ "GenMsgCycleTime" BO_ 2566898290 50;
BA_ "GenMsgCycleTimeFast" BO_ 2566898290 50;
BA_ "GenMsgDelayTime" BO_ 2566898290 25;
BA_ "GenMsgSendType" BO_ 2566898290 0;
BA_ "GenMsgStartDelayTime" BO_ 2566898290 49;
BA_ "CI_MsgDefinition" BO_ 2566911858 "Iveco Daily Proprietary";
BA_ "CI_MsgId" BO_ 2566911858 10991;
BA_ "CI_MsgName" BO_ 2566911858 "EmCmd2 - Expansion Module Commands #2";
BA_ "GenMsgCycleTime" BO_ 2566911858 50;
BA_ "GenMsgCycleTimeFast" BO_ 2566911858 50;
BA_ "GenMsgDelayTime" BO_ 2566911858 25;
BA_ "GenMsgSendType" BO_ 2566911858 0;
BA_ "GenMsgStartDelayTime" BO_ 2566911858 51;
BA_ "CI_MsgDefinition" BO_ 2565865505 "J1939DA";
BA_ "CI_MsgId" BO_ 2565865505 1016;
BA_ "CI_MsgName" BO_ 2565865505 "ERC1_21 - Electronic Retarder Controller 1";
BA_ "GenMsgCycleTime" BO_ 2565865505 100;
BA_ "GenMsgCycleTimeFast" BO_ 2565865505 100;
BA_ "GenMsgDelayTime" BO_ 2565865505 50;
BA_ "GenMsgSendType" BO_ 2565865505 0;
BA_ "GenMsgStartDelayTime" BO_ 2565865505 63;
BA_ "CI_MsgDefinition" BO_ 2565865488 "J1939DA";
BA_ "CI_MsgId" BO_ 2565865488 986;
BA_ "CI_MsgName" BO_ 2565865488 "ERC1_DR - Electronic Retarder Controller 1";
BA_ "GenMsgCycleTime" BO_ 2565865488 100;
BA_ "GenMsgCycleTimeFast" BO_ 2565865488 100;
BA_ "GenMsgDelayTime" BO_ 2565865488 50;
BA_ "GenMsgSendType" BO_ 2565865488 0;
BA_ "GenMsgStartDelayTime" BO_ 2565865488 62;
BA_ "CI_MsgDefinition" BO_ 2566843904 "J1939DA";
BA_ "CI_MsgId" BO_ 2566843904 2016;
BA_ "CI_MsgName" BO_ 2566843904 "ET1 - Engine Temperature 1";
BA_ "GenMsgCycleTime" BO_ 2566843904 1000;
BA_ "GenMsgCycleTimeFast" BO_ 2566843904 1000;
BA_ "GenMsgDelayTime" BO_ 2566843904 500;
BA_ "GenMsgSendType" BO_ 2566843904 0;
BA_ "GenMsgStartDelayTime" BO_ 2566843904 236;
BA_ "CI_MsgDefinition" BO_ 2364539395 "J1939DA";
BA_ "CI_MsgId" BO_ 2364539395 1251;
BA_ "CI_MsgName" BO_ 2364539395 "ETC1 - Electronic Transmission Controller 1";
BA_ "GenMsgCycleTime" BO_ 2364539395 10;
BA_ "GenMsgCycleTimeFast" BO_ 2364539395 10;
BA_ "GenMsgDelayTime" BO_ 2364539395 5;
BA_ "GenMsgSendType" BO_ 2364539395 0;
BA_ "GenMsgStartDelayTime" BO_ 2364539395 2;
BA_ "CI_MsgDefinition" BO_ 2565866755 "J1939DA";
BA_ "CI_MsgId" BO_ 2565866755 1288;
BA_ "CI_MsgName" BO_ 2565866755 "ETC2 - Electronic Transmission Controller 2";
BA_ "GenMsgCycleTime" BO_ 2565866755 100;
BA_ "GenMsgCycleTimeFast" BO_ 2565866755 100;
BA_ "GenMsgDelayTime" BO_ 2565866755 50;
BA_ "GenMsgSendType" BO_ 2565866755 0;
BA_ "GenMsgStartDelayTime" BO_ 2565866755 64;
BA_ "CI_MsgDefinition" BO_ 2633941763 "J1939DA";
BA_ "CI_MsgId" BO_ 2633941763 1321;
BA_ "CI_MsgName" BO_ 2633941763 "ETC5 - Electronic Transmission Controller 5";
BA_ "GenMsgCycleTime" BO_ 2633941763 1000;
BA_ "GenMsgCycleTimeFast" BO_ 2633941763 1000;
BA_ "GenMsgDelayTime" BO_ 2633941763 50;
BA_ "GenMsgSendType" BO_ 2633941763 0;
BA_ "GenMsgStartDelayTime" BO_ 2633941763 294;
BA_ "CI_MsgDefinition" BO_ 2566801923 "J1939DA";
BA_ "CI_MsgId" BO_ 2566801923 1357;
BA_ "CI_MsgName" BO_ 2566801923 "ETC7 - Electronic Transmission Controller 7";
BA_ "GenMsgCycleTime" BO_ 2566801923 100;
BA_ "GenMsgCycleTimeFast" BO_ 2566801923 100;
BA_ "GenMsgDelayTime" BO_ 2566801923 50;
BA_ "GenMsgSendType" BO_ 2566801923 0;
BA_ "GenMsgStartDelayTime" BO_ 2566801923 71;
BA_ "CI_MsgDefinition" BO_ 2364541955 "J1939DA";
BA_ "CI_MsgId" BO_ 2364541955 1389;
BA_ "CI_MsgName" BO_ 2364541955 "ETC8 - Electronic Transmission Controller #8";
BA_ "GenMsgCycleTime" BO_ 2364541955 100;
BA_ "GenMsgCycleTimeFast" BO_ 2364541955 20;
BA_ "GenMsgDelayTime" BO_ 2364541955 10;
BA_ "GenMsgSendType" BO_ 2364541955 0;
BA_ "GenMsgStartDelayTime" BO_ 2364541955 14;
BA_ "CI_MsgDefinition" BO_ 2431649578 "J1939DA";
BA_ "CI_MsgId" BO_ 2431649578 5831;
BA_ "CI_MsgName" BO_ 2431649578 "FLI1 - Forward Lane Image 1";
BA_ "GenMsgCycleTime" BO_ 2431649578 50;
BA_ "GenMsgCycleTimeFast" BO_ 2431649578 50;
BA_ "GenMsgDelayTime" BO_ 2431649578 25;
BA_ "GenMsgSendType" BO_ 2431649578 0;
BA_ "GenMsgStartDelayTime" BO_ 2431649578 42;
BA_ "CI_MsgDefinition" BO_ 2566806314 "J1939DA";
BA_ "CI_MsgId" BO_ 2566806314 5841;
BA_ "CI_MsgName" BO_ 2566806314 "FLI2 - Forward Lane Image 2";
BA_ "GenMsgCycleTime" BO_ 2566806314 100;
BA_ "GenMsgCycleTimeFast" BO_ 2566806314 100;
BA_ "GenMsgDelayTime" BO_ 2566806314 50;
BA_ "GenMsgSendType" BO_ 2566806314 0;
BA_ "GenMsgStartDelayTime" BO_ 2566806314 75;
BA_ "CI_MsgDefinition" BO_ 2566662442 "J1939DA";
BA_ "CI_MsgId" BO_ 2566662442 5851;
BA_ "CI_MsgName" BO_ 2566662442 "FLI3 - Forward Lane Image 3";
BA_ "GenMsgCycleTime" BO_ 2566662442 100;
BA_ "GenMsgCycleTimeFast" BO_ 2566662442 100;
BA_ "GenMsgDelayTime" BO_ 2566662442 50;
BA_ "GenMsgSendType" BO_ 2566662442 0;
BA_ "GenMsgStartDelayTime" BO_ 2566662442 67;
BA_ "CI_MsgDefinition" BO_ 2561223201 "J1939DA";
BA_ "CI_MsgId" BO_ 2561223201 5861;
BA_ "CI_MsgName" BO_ 2561223201 "FLIC - Forward Lane Image Command";
BA_ "CI_MsgDefinition" BO_ 2566749463 "FMS";
BA_ "CI_MsgId" BO_ 2566749463 5960;
BA_ "CI_MsgName" BO_ 2566749463 "FMS1_17 - Reserved for FMS Telltale status";
BA_ "GenMsgCycleTime" BO_ 2566749463 1000;
BA_ "GenMsgCycleTimeFast" BO_ 2566749463 1000;
BA_ "GenMsgDelayTime" BO_ 2566749463 500;
BA_ "GenMsgSendType" BO_ 2566749463 0;
BA_ "GenMsgStartDelayTime" BO_ 2566749463 166;
BA_ "CI_MsgDefinition" BO_ 2566896128 "Iveco Daily Proprietary";
BA_ "CI_MsgId" BO_ 2566896128 2108;
BA_ "CI_MsgName" BO_ 2566896128 "FUELE2 - Fuel economy 2 proprietary message";
BA_ "GenMsgCycleTime" BO_ 2566896128 100;
BA_ "GenMsgCycleTimeFast" BO_ 2566896128 100;
BA_ "GenMsgDelayTime" BO_ 2566896128 50;
BA_ "GenMsgSendType" BO_ 2566896128 0;
BA_ "GenMsgStartDelayTime" BO_ 2566896128 86;
BA_ "CI_MsgDefinition" BO_ 2566841600 "J1939DA";
BA_ "CI_MsgId" BO_ 2566841600 2069;
BA_ "CI_MsgName" BO_ 2566841600 "HOURS - Engine Hours, Revolutions";
BA_ "GenMsgCycleTime" BO_ 2566841600 1000;
BA_ "GenMsgCycleTimeFast" BO_ 2566841600 1000;
BA_ "GenMsgDelayTime" BO_ 2566841600 500;
BA_ "GenMsgSendType" BO_ 2566841600 0;
BA_ "GenMsgStartDelayTime" BO_ 2566841600 229;
BA_ "CI_MsgDefinition" BO_ 2566719744 "J1939DA";
BA_ "CI_MsgId" BO_ 2566719744 2095;
BA_ "CI_MsgName" BO_ 2566719744 "HRLFC - High Resolution Fuel Consumption (Liquid)";
BA_ "GenMsgCycleTime" BO_ 2566719744 1000;
BA_ "GenMsgCycleTimeFast" BO_ 2566719744 1000;
BA_ "GenMsgDelayTime" BO_ 2566719744 500;
BA_ "GenMsgSendType" BO_ 2566719744 0;
BA_ "GenMsgStartDelayTime" BO_ 2566719744 164;
BA_ "CI_MsgDefinition" BO_ 2298375691 "J1939DA";
BA_ "CI_MsgId" BO_ 2298375691 723;
BA_ "CI_MsgName" BO_ 2298375691 "HRW - High Resolution Wheel Speed";
BA_ "GenMsgCycleTime" BO_ 2298375691 20;
BA_ "GenMsgCycleTimeFast" BO_ 2298375691 20;
BA_ "GenMsgDelayTime" BO_ 2298375691 10;
BA_ "GenMsgSendType" BO_ 2298375691 0;
BA_ "GenMsgStartDelayTime" BO_ 2298375691 11;
BA_ "CI_MsgDefinition" BO_ 2566609652 "J1939DA";
BA_ "CI_MsgId" BO_ 2566609652 3732;
BA_ "CI_MsgName" BO_ 2566609652 "HVESP1CFG_F4 - High Voltage Energy Storage Pack 1 Configuration";
BA_ "TpJ1939VarDlc" BO_ 2566609652 1;
BA_ "CI_MsgDefinition" BO_ 2566609141 "J1939DA";
BA_ "CI_MsgId" BO_ 2566609141 3742;
BA_ "CI_MsgName" BO_ 2566609141 "HVESP2CFG_F5 - High Voltage Energy Storage Pack 2 Configuration";
BA_ "TpJ1939VarDlc" BO_ 2566609141 1;
BA_ "CI_MsgDefinition" BO_ 2566608630 "J1939DA";
BA_ "CI_MsgId" BO_ 2566608630 3752;
BA_ "CI_MsgName" BO_ 2566608630 "HVESP3CFG_F6 - High Voltage Energy Storage Pack 3 Configuration";
BA_ "TpJ1939VarDlc" BO_ 2566608630 1;
BA_ "CI_MsgDefinition" BO_ 2566608006 "J1939DA";
BA_ "CI_MsgId" BO_ 2566608006 40445;
BA_ "CI_MsgName" BO_ 2566608006 "HVESP4CFG_86 - High Voltage Energy Storage Pack 4 Configuration";
BA_ "TpJ1939VarDlc" BO_ 2566608006 1;
BA_ "CI_MsgDefinition" BO_ 2566607495 "J1939DA";
BA_ "CI_MsgId" BO_ 2566607495 40456;
BA_ "CI_MsgName" BO_ 2566607495 "HVESP5CFG_87 - High Voltage Energy Storage Pack 5 Configuration";
BA_ "TpJ1939VarDlc" BO_ 2566607495 1;
BA_ "CI_ParId" SG_ 2565865739 TractMountTrailAbsWarnSig "1792";
BA_ "CI_SigId" SG_ 2565865739 TractMountTrailAbsWarnSig 531;
BA_ "CI_SigName" SG_ 2565865739 TractMountTrailAbsWarnSig "Tractor-Mounted Trailer ABS Warning Signal";
BA_ "GenSigTimeoutTime_PCM" SG_ 2565865739 TractMountTrailAbsWarnSig 500;
BA_ "SPN" SG_ 2565865739 TractMountTrailAbsWarnSig 1792;
BA_ "SigType" SG_ 2565865739 TractMountTrailAbsWarnSig 4;
BA_ "CI_ParId" SG_ 2565865739 TrailAbsSts "1836";
BA_ "CI_SigId" SG_ 2565865739 TrailAbsSts 530;
BA_ "CI_SigName" SG_ 2565865739 TrailAbsSts "Trailer ABS Status";
BA_ "GenSigTimeoutTime_PCM" SG_ 2565865739 TrailAbsSts 500;
BA_ "SPN" SG_ 2565865739 TrailAbsSts 1836;
BA_ "SigType" SG_ 2565865739 TrailAbsSts 4;
BA_ "CI_ParId" SG_ 2565865739 SaOfCtrlDevForBrkCtrl "1481";
BA_ "CI_SigId" SG_ 2565865739 SaOfCtrlDevForBrkCtrl 527;
BA_ "CI_SigName" SG_ 2565865739 SaOfCtrlDevForBrkCtrl "Source Address of Controlling Device for Brake Control";
BA_ "GenSigTimeoutTime_PCM" SG_ 2565865739 SaOfCtrlDevForBrkCtrl 500;
BA_ "SPN" SG_ 2565865739 SaOfCtrlDevForBrkCtrl 1481;
BA_ "SigType" SG_ 2565865739 SaOfCtrlDevForBrkCtrl 1;
BA_ "CI_ParId" SG_ 2565865739 Atc_AsrInfoSig "1793";
BA_ "CI_SigId" SG_ 2565865739 Atc_AsrInfoSig 526;
BA_ "CI_SigName" SG_ 2565865739 Atc_AsrInfoSig "ATC/ASR Information Signal";
BA_ "GenSigTimeoutTime_PCM" SG_ 2565865739 Atc_AsrInfoSig 500;
BA_ "SPN" SG_ 2565865739 Atc_AsrInfoSig 1793;
BA_ "SigType" SG_ 2565865739 Atc_AsrInfoSig 4;
BA_ "CI_ParId" SG_ 2565865739 Abs_EbsAmberWarnSig "1438";
BA_ "CI_SigId" SG_ 2565865739 Abs_EbsAmberWarnSig 525;
BA_ "CI_SigName" SG_ 2565865739 Abs_EbsAmberWarnSig "ABS/EBS Amber Warning Signal (Powered Vehicle)";
BA_ "GenSigTimeoutTime_PCM" SG_ 2565865739 Abs_EbsAmberWarnSig 500;
BA_ "SPN" SG_ 2565865739 Abs_EbsAmberWarnSig 1438;
BA_ "SigType" SG_ 2565865739 Abs_EbsAmberWarnSig 4;
BA_ "CI_ParId" SG_ 2565865739 AbsFullyOp "1243";
BA_ "CI_SigId" SG_ 2565865739 AbsFullyOp 523;
BA_ "CI_SigName" SG_ 2565865739 AbsFullyOp "ABS Fully Operational";
BA_ "GenSigTimeoutTime_PCM" SG_ 2565865739 AbsFullyOp 500;
BA_ "SPN" SG_ 2565865739 AbsFullyOp 1243;
BA_ "SigType" SG_ 2565865739 AbsFullyOp 4;
BA_ "CI_ParId" SG_ 2565865739 AsrOffRoadSw "576";
BA_ "CI_SigId" SG_ 2565865739 AsrOffRoadSw 515;
BA_ "CI_SigName" SG_ 2565865739 AsrOffRoadSw "ASR Off-road Switch";
BA_ "GenSigTimeoutTime_PCM" SG_ 2565865739 AsrOffRoadSw 500;
BA_ "SPN" SG_ 2565865739 AsrOffRoadSw 576;
BA_ "SigType" SG_ 2565865739 AsrOffRoadSw 4;
BA_ "CI_ParId" SG_ 2565865739 BrkPedPos "521";
BA_ "CI_SigId" SG_ 2565865739 BrkPedPos 513;
BA_ "CI_SigName" SG_ 2565865739 BrkPedPos "Brake Pedal Position";
BA_ "GenSigTimeoutTime_PCM" SG_ 2565865739 BrkPedPos 500;
BA_ "SPN" SG_ 2565865739 BrkPedPos 521;
BA_ "SigType" SG_ 2565865739 BrkPedPos 1;
BA_ "CI_ParId" SG_ 2565865739 EbsBrkSw "1121";
BA_ "CI_SigId" SG_ 2565865739 EbsBrkSw 512;
BA_ "CI_SigName" SG_ 2565865739 EbsBrkSw "EBS Brake Switch";
BA_ "GenSigTimeoutTime_PCM" SG_ 2565865739 EbsBrkSw 500;
BA_ "SPN" SG_ 2565865739 EbsBrkSw 1121;
BA_ "SigType" SG_ 2565865739 EbsBrkSw 4;
BA_ "CI_ParId" SG_ 2565865739 AbsActv "563";
BA_ "CI_SigId" SG_ 2565865739 AbsActv 511;
BA_ "CI_SigName" SG_ 2565865739 AbsActv "Anti-Lock Braking (ABS) Active";
BA_ "GenSigTimeoutTime_PCM" SG_ 2565865739 AbsActv 500;
BA_ "SPN" SG_ 2565865739 AbsActv 563;
BA_ "SigType" SG_ 2565865739 AbsActv 4;
BA_ "CI_ParId" SG_ 2565865739 AsrBrkCtrlActv "562";
BA_ "CI_SigId" SG_ 2565865739 AsrBrkCtrlActv 510;
BA_ "CI_SigName" SG_ 2565865739 AsrBrkCtrlActv "ASR Brake Control Active";
BA_ "GenSigTimeoutTime_PCM" SG_ 2565865739 AsrBrkCtrlActv 500;
BA_ "SPN" SG_ 2565865739 AsrBrkCtrlActv 562;
BA_ "SigType" SG_ 2565865739 AsrBrkCtrlActv 4;
BA_ "CI_ParId" SG_ 2565865739 AsrEngCtrlActv "561";
BA_ "CI_SigId" SG_ 2565865739 AsrEngCtrlActv 509;
BA_ "CI_SigName" SG_ 2565865739 AsrEngCtrlActv "ASR Engine Control Active";
BA_ "GenSigTimeoutTime_PCM" SG_ 2565865739 AsrEngCtrlActv 500;
BA_ "SPN" SG_ 2565865739 AsrEngCtrlActv 561;
BA_ "SigType" SG_ 2565865739 AsrEngCtrlActv 4;
BA_ "CI_ParId" SG_ 2566831883 RelSpeedRa1R "908";
BA_ "CI_SigId" SG_ 2566831883 RelSpeedRa1R 602;
BA_ "CI_SigName" SG_ 2566831883 RelSpeedRa1R "Relative Speed; Rear Axle #1, Right Wheel";
BA_ "GenSigTimeoutTime_PCM" SG_ 2566831883 RelSpeedRa1R 500;
BA_ "SPN" SG_ 2566831883 RelSpeedRa1R 908;
BA_ "SigType" SG_ 2566831883 RelSpeedRa1R 1;
BA_ "CI_ParId" SG_ 2566831883 RelSpeedRa1L "907";
BA_ "CI_SigId" SG_ 2566831883 RelSpeedRa1L 601;
BA_ "CI_SigName" SG_ 2566831883 RelSpeedRa1L "Relative Speed; Rear Axle #1, Left Wheel";
BA_ "GenSigTimeoutTime_PCM" SG_ 2566831883 RelSpeedRa1L 500;
BA_ "SPN" SG_ 2566831883 RelSpeedRa1L 907;
BA_ "SigType" SG_ 2566831883 RelSpeedRa1L 1;
BA_ "CI_ParId" SG_ 2566831883 RelSpeedFaR "906";
BA_ "CI_SigId" SG_ 2566831883 RelSpeedFaR 600;
BA_ "CI_SigName" SG_ 2566831883 RelSpeedFaR "Relative Speed; Front Axle, Right Wheel";
BA_ "GenSigTimeoutTime_PCM" SG_ 2566831883 RelSpeedFaR 500;
BA_ "SPN" SG_ 2566831883 RelSpeedFaR 906;
BA_ "SigType" SG_ 2566831883 RelSpeedFaR 1;
BA_ "CI_ParId" SG_ 2566831883 RelSpeedFaL "905";
BA_ "CI_SigId" SG_ 2566831883 RelSpeedFaL 599;
BA_ "CI_SigName" SG_ 2566831883 RelSpeedFaL "Relative Speed; Front Axle, Left Wheel";
BA_ "GenSigTimeoutTime_PCM" SG_ 2566831883 RelSpeedFaL 500;
BA_ "SPN" SG_ 2566831883 RelSpeedFaL 905;
BA_ "SigType" SG_ 2566831883 RelSpeedFaL 1;
BA_ "CI_ParId" SG_ 2566831883 FaSpeed "904";
BA_ "CI_SigId" SG_ 2566831883 FaSpeed 598;
BA_ "CI_SigName" SG_ 2566831883 FaSpeed "Front Axle Speed";
BA_ "GenSigTimeoutTime_PCM" SG_ 2566831883 FaSpeed 500;
BA_ "SPN" SG_ 2566831883 FaSpeed 904;
BA_ "SigType" SG_ 2566831883 FaSpeed 1;
BA_ "CI_ParId" SG_ 2566767627 XbrBrkHoldMode "15264";
BA_ "CI_SigId" SG_ 2566767627 XbrBrkHoldMode 44235;
BA_ "CI_SigName" SG_ 2566767627 XbrBrkHoldMode "XBR Brake Hold Mode";
BA_ "GenSigSendType" SG_ 2566767627 XbrBrkHoldMode 3;
BA_ "GenSigTimeoutTime_PCM" SG_ 2566767627 XbrBrkHoldMode 500;
BA_ "SPN" SG_ 2566767627 XbrBrkHoldMode 15264;
BA_ "CI_ParId" SG_ 2566767627 EmerBrkActv "5847";
BA_ "CI_SigId" SG_ 2566767627 EmerBrkActv 656;
BA_ "CI_SigName" SG_ 2566767627 EmerBrkActv "Emergency Braking Active";
BA_ "GenSigSendType" SG_ 2566767627 EmerBrkActv 3;
BA_ "GenSigTimeoutTime_PCM" SG_ 2566767627 EmerBrkActv 500;
BA_ "SPN" SG_ 2566767627 EmerBrkActv 5847;
BA_ "SigType" SG_ 2566767627 EmerBrkActv 4;
BA_ "CI_ParId" SG_ 2566767627 ParkBrkActFullyActv "5275";
BA_ "CI_SigId" SG_ 2566767627 ParkBrkActFullyActv 655;
BA_ "CI_SigName" SG_ 2566767627 ParkBrkActFullyActv "Parking Brake Actuator Fully Activated";
BA_ "GenSigSendType" SG_ 2566767627 ParkBrkActFullyActv 3;
BA_ "GenSigTimeoutTime_PCM" SG_ 2566767627 ParkBrkActFullyActv 500;
BA_ "SPN" SG_ 2566767627 ParkBrkActFullyActv 5275;
BA_ "SigType" SG_ 2566767627 ParkBrkActFullyActv 4;
BA_ "CI_ParId" SG_ 2566767627 XbrAccelLim "2921";
BA_ "CI_SigId" SG_ 2566767627 XbrAccelLim 654;
BA_ "CI_SigName" SG_ 2566767627 XbrAccelLim "XBR Acceleration Limit";
BA_ "GenSigSendType" SG_ 2566767627 XbrAccelLim 3;
BA_ "GenSigTimeoutTime_PCM" SG_ 2566767627 XbrAccelLim 500;
BA_ "SPN" SG_ 2566767627 XbrAccelLim 2921;
BA_ "SigType" SG_ 2566767627 XbrAccelLim 1;
BA_ "CI_ParId" SG_ 2566767627 XbrActvCtrlMode "2918";
BA_ "CI_SigId" SG_ 2566767627 XbrActvCtrlMode 653;
BA_ "CI_SigName" SG_ 2566767627 XbrActvCtrlMode "XBR Active Control Mode";
BA_ "GenSigSendType" SG_ 2566767627 XbrActvCtrlMode 3;
BA_ "GenSigTimeoutTime_PCM" SG_ 2566767627 XbrActvCtrlMode 500;
BA_ "SPN" SG_ 2566767627 XbrActvCtrlMode 2918;
BA_ "CI_ParId" SG_ 2566767627 XbrSysSts "2917";
BA_ "CI_SigId" SG_ 2566767627 XbrSysSts 652;
BA_ "CI_SigName" SG_ 2566767627 XbrSysSts "XBR System State";
BA_ "GenSigSendType" SG_ 2566767627 XbrSysSts 3;
BA_ "GenSigTimeoutTime_PCM" SG_ 2566767627 XbrSysSts 500;
BA_ "SPN" SG_ 2566767627 XbrSysSts 2917;
BA_ "SigType" SG_ 2566767627 XbrSysSts 4;
BA_ "CI_ParId" SG_ 2566767627 FoundBrkUse "2919";
BA_ "CI_SigId" SG_ 2566767627 FoundBrkUse 651;
BA_ "CI_SigName" SG_ 2566767627 FoundBrkUse "Foundation Brake Use";
BA_ "GenSigSendType" SG_ 2566767627 FoundBrkUse 3;
BA_ "GenSigTimeoutTime_PCM" SG_ 2566767627 FoundBrkUse 500;
BA_ "SPN" SG_ 2566767627 FoundBrkUse 2919;
BA_ "SigType" SG_ 2566767627 FoundBrkUse 4;
BA_ "CI_ParId" SG_ 2566767627 HhMode "2912";
BA_ "CI_SigId" SG_ 2566767627 HhMode 650;
BA_ "CI_SigName" SG_ 2566767627 HhMode "Hill holder mode";
BA_ "GenSigSendType" SG_ 2566767627 HhMode 3;
BA_ "GenSigTimeoutTime_PCM" SG_ 2566767627 HhMode 500;
BA_ "SPN" SG_ 2566767627 HhMode 2912;
BA_ "CI_ParId" SG_ 2566767627 HaltBrkMode "2913";
BA_ "CI_SigId" SG_ 2566767627 HaltBrkMode 649;
BA_ "CI_SigName" SG_ 2566767627 HaltBrkMode "Halt brake mode";
BA_ "GenSigSendType" SG_ 2566767627 HaltBrkMode 3;
BA_ "GenSigTimeoutTime_PCM" SG_ 2566767627 HaltBrkMode 500;
BA_ "SPN" SG_ 2566767627 HaltBrkMode 2913;
BA_ "CI_ParId" SG_ 2566767627 BrkTempWarn "3839";
BA_ "CI_SigId" SG_ 2566767627 BrkTempWarn 648;
BA_ "CI_SigName" SG_ 2566767627 BrkTempWarn "Brake Temperature Warning";
BA_ "GenSigSendType" SG_ 2566767627 BrkTempWarn 3;
BA_ "GenSigTimeoutTime_PCM" SG_ 2566767627 BrkTempWarn 500;
BA_ "SPN" SG_ 2566767627 BrkTempWarn 3839;
BA_ "SigType" SG_ 2566767627 BrkTempWarn 4;
BA_ "CI_ParId" SG_ 2566841088 EngJ "1794";
BA_ "CI_SigId" SG_ 2566841088 EngJ 1990;
BA_ "CI_SigName" SG_ 2566841088 EngJ "Engine Moment of Inertia";
BA_ "GenSigTimeoutTime_PCM" SG_ 2566841088 EngJ 5000;
BA_ "SPN" SG_ 2566841088 EngJ 1794;
BA_ "SigType" SG_ 2566841088 EngJ 1;
BA_ "CI_ParId" SG_ 2566841088 EngReqSpeedCtrlRngUpLimXr "1712";
BA_ "CI_SigId" SG_ 2566841088 EngReqSpeedCtrlRngUpLimXr 1989;
BA_ "CI_SigName" SG_ 2566841088 EngReqSpeedCtrlRngUpLimXr "Engine Requested Speed Control Range Upper Limit (Extended Range)";
BA_ "GenSigTimeoutTime_PCM" SG_ 2566841088 EngReqSpeedCtrlRngUpLimXr 5000;
BA_ "SPN" SG_ 2566841088 EngReqSpeedCtrlRngUpLimXr 1712;
BA_ "SigType" SG_ 2566841088 EngReqSpeedCtrlRngUpLimXr 1;
BA_ "CI_ParId" SG_ 2566841088 EngReqTrqCtrlRngUpLim "538";
BA_ "CI_SigId" SG_ 2566841088 EngReqTrqCtrlRngUpLim 1988;
BA_ "CI_SigName" SG_ 2566841088 EngReqTrqCtrlRngUpLim "Engine Requested Torque Control Range Upper Limit";
BA_ "GenSigTimeoutTime_PCM" SG_ 2566841088 EngReqTrqCtrlRngUpLim 5000;
BA_ "SPN" SG_ 2566841088 EngReqTrqCtrlRngUpLim 538;
BA_ "SigType" SG_ 2566841088 EngReqTrqCtrlRngUpLim 1;
BA_ "CI_ParId" SG_ 2566841088 EngReqTrqCtrlRngLowLim "537";
BA_ "CI_SigId" SG_ 2566841088 EngReqTrqCtrlRngLowLim 1987;
BA_ "CI_SigName" SG_ 2566841088 EngReqTrqCtrlRngLowLim "Engine Requested Torque Control Range Lower Limit";
BA_ "GenSigTimeoutTime_PCM" SG_ 2566841088 EngReqTrqCtrlRngLowLim 5000;
BA_ "SPN" SG_ 2566841088 EngReqTrqCtrlRngLowLim 537;
BA_ "SigType" SG_ 2566841088 EngReqTrqCtrlRngLowLim 1;
BA_ "CI_ParId" SG_ 2566841088 EngReqSpeedCtrlRngUpLim "536";
BA_ "CI_SigId" SG_ 2566841088 EngReqSpeedCtrlRngUpLim 1986;
BA_ "CI_SigName" SG_ 2566841088 EngReqSpeedCtrlRngUpLim "Engine Requested Speed Control Range Upper Limit";
BA_ "GenSigTimeoutTime_PCM" SG_ 2566841088 EngReqSpeedCtrlRngUpLim 5000;
BA_ "SPN" SG_ 2566841088 EngReqSpeedCtrlRngUpLim 536;
BA_ "SigType" SG_ 2566841088 EngReqSpeedCtrlRngUpLim 1;
BA_ "CI_ParId" SG_ 2566841088 EngReqSpeedCtrlRngLowLim "535";
BA_ "CI_SigId" SG_ 2566841088 EngReqSpeedCtrlRngLowLim 1985;
BA_ "CI_SigName" SG_ 2566841088 EngReqSpeedCtrlRngLowLim "Engine Requested Speed Control Range Lower Limit";
BA_ "GenSigTimeoutTime_PCM" SG_ 2566841088 EngReqSpeedCtrlRngLowLim 5000;
BA_ "SPN" SG_ 2566841088 EngReqSpeedCtrlRngLowLim 535;
BA_ "SigType" SG_ 2566841088 EngReqSpeedCtrlRngLowLim 1;
BA_ "CI_ParId" SG_ 2566841088 EngMaxMomOvrTimeLim "534";
BA_ "CI_SigId" SG_ 2566841088 EngMaxMomOvrTimeLim 1984;
BA_ "CI_SigName" SG_ 2566841088 EngMaxMomOvrTimeLim "Engine Maximum Momentary Override Time Limit";
BA_ "GenSigTimeoutTime_PCM" SG_ 2566841088 EngMaxMomOvrTimeLim 5000;
BA_ "SPN" SG_ 2566841088 EngMaxMomOvrTimeLim 534;
BA_ "SigType" SG_ 2566841088 EngMaxMomOvrTimeLim 1;
BA_ "CI_ParId" SG_ 2566841088 EngMaxMomOvrSpeedPnt7 "533";
BA_ "CI_SigId" SG_ 2566841088 EngMaxMomOvrSpeedPnt7 1983;
BA_ "CI_SigName" SG_ 2566841088 EngMaxMomOvrSpeedPnt7 "Engine Maximum Momentary Override Speed, Point 7";
BA_ "GenSigTimeoutTime_PCM" SG_ 2566841088 EngMaxMomOvrSpeedPnt7 5000;
BA_ "SPN" SG_ 2566841088 EngMaxMomOvrSpeedPnt7 533;
BA_ "SigType" SG_ 2566841088 EngMaxMomOvrSpeedPnt7 1;
BA_ "CI_ParId" SG_ 2566841088 EngRefTrq "544";
BA_ "CI_SigId" SG_ 2566841088 EngRefTrq 1982;
BA_ "CI_SigName" SG_ 2566841088 EngRefTrq "Engine Reference Torque";
BA_ "GenSigTimeoutTime_PCM" SG_ 2566841088 EngRefTrq 5000;
BA_ "SPN" SG_ 2566841088 EngRefTrq 544;
BA_ "SigType" SG_ 2566841088 EngRefTrq 1;
BA_ "CI_ParId" SG_ 2566841088 EngGainEndspeedGov "545";
BA_ "CI_SigId" SG_ 2566841088 EngGainEndspeedGov 1981;
BA_ "CI_SigName" SG_ 2566841088 EngGainEndspeedGov "Engine Gain (kp) Of The Endspeed Governor";
BA_ "GenSigTimeoutTime_PCM" SG_ 2566841088 EngGainEndspeedGov 5000;
BA_ "SPN" SG_ 2566841088 EngGainEndspeedGov 545;
BA_ "SigType" SG_ 2566841088 EngGainEndspeedGov 1;
BA_ "CI_ParId" SG_ 2566841088 EngSpeedAtHighIdlePnt6 "532";
BA_ "CI_SigId" SG_ 2566841088 EngSpeedAtHighIdlePnt6 1980;
BA_ "CI_SigName" SG_ 2566841088 EngSpeedAtHighIdlePnt6 "Engine Speed At High Idle, Point 6";
BA_ "GenSigTimeoutTime_PCM" SG_ 2566841088 EngSpeedAtHighIdlePnt6 5000;
BA_ "SPN" SG_ 2566841088 EngSpeedAtHighIdlePnt6 532;
BA_ "SigType" SG_ 2566841088 EngSpeedAtHighIdlePnt6 1;
BA_ "CI_ParId" SG_ 2566841088 EngPcTrqAtPnt5 "543";
BA_ "CI_SigId" SG_ 2566841088 EngPcTrqAtPnt5 1979;
BA_ "CI_SigName" SG_ 2566841088 EngPcTrqAtPnt5 "Engine Percent Torque At Point 5";
BA_ "GenSigTimeoutTime_PCM" SG_ 2566841088 EngPcTrqAtPnt5 5000;
BA_ "SPN" SG_ 2566841088 EngPcTrqAtPnt5 543;
BA_ "SigType" SG_ 2566841088 EngPcTrqAtPnt5 1;
BA_ "CI_ParId" SG_ 2566841088 EngSpeedAtPnt5 "531";
BA_ "CI_SigId" SG_ 2566841088 EngSpeedAtPnt5 1978;
BA_ "CI_SigName" SG_ 2566841088 EngSpeedAtPnt5 "Engine Speed At Point 5";
BA_ "GenSigTimeoutTime_PCM" SG_ 2566841088 EngSpeedAtPnt5 5000;
BA_ "SPN" SG_ 2566841088 EngSpeedAtPnt5 531;
BA_ "SigType" SG_ 2566841088 EngSpeedAtPnt5 1;
BA_ "CI_ParId" SG_ 2566841088 EngPcTrqAtPnt4 "542";
BA_ "CI_SigId" SG_ 2566841088 EngPcTrqAtPnt4 1977;
BA_ "CI_SigName" SG_ 2566841088 EngPcTrqAtPnt4 "Engine Percent Torque At Point 4";
BA_ "GenSigTimeoutTime_PCM" SG_ 2566841088 EngPcTrqAtPnt4 5000;
BA_ "SPN" SG_ 2566841088 EngPcTrqAtPnt4 542;
BA_ "SigType" SG_ 2566841088 EngPcTrqAtPnt4 1;
BA_ "CI_ParId" SG_ 2566841088 EngSpeedAtPnt4 "530";
BA_ "CI_SigId" SG_ 2566841088 EngSpeedAtPnt4 1976;
BA_ "CI_SigName" SG_ 2566841088 EngSpeedAtPnt4 "Engine Speed At Point 4";
BA_ "GenSigTimeoutTime_PCM" SG_ 2566841088 EngSpeedAtPnt4 5000;
BA_ "SPN" SG_ 2566841088 EngSpeedAtPnt4 530;
BA_ "SigType" SG_ 2566841088 EngSpeedAtPnt4 1;
BA_ "CI_ParId" SG_ 2566841088 EngPcTrqAtPnt3 "541";
BA_ "CI_SigId" SG_ 2566841088 EngPcTrqAtPnt3 1975;
BA_ "CI_SigName" SG_ 2566841088 EngPcTrqAtPnt3 "Engine Percent Torque At Point 3";
BA_ "GenSigTimeoutTime_PCM" SG_ 2566841088 EngPcTrqAtPnt3 5000;
BA_ "SPN" SG_ 2566841088 EngPcTrqAtPnt3 541;
BA_ "SigType" SG_ 2566841088 EngPcTrqAtPnt3 1;
BA_ "CI_ParId" SG_ 2566841088 EngSpeedAtPnt3 "529";
BA_ "CI_SigId" SG_ 2566841088 EngSpeedAtPnt3 1974;
BA_ "CI_SigName" SG_ 2566841088 EngSpeedAtPnt3 "Engine Speed At Point 3";
BA_ "GenSigTimeoutTime_PCM" SG_ 2566841088 EngSpeedAtPnt3 5000;
BA_ "SPN" SG_ 2566841088 EngSpeedAtPnt3 529;
BA_ "SigType" SG_ 2566841088 EngSpeedAtPnt3 1;
BA_ "CI_ParId" SG_ 2566841088 EngPcTrqAtPnt2 "540";
BA_ "CI_SigId" SG_ 2566841088 EngPcTrqAtPnt2 1973;
BA_ "CI_SigName" SG_ 2566841088 EngPcTrqAtPnt2 "Engine Percent Torque At Point 2";
BA_ "GenSigTimeoutTime_PCM" SG_ 2566841088 EngPcTrqAtPnt2 5000;
BA_ "SPN" SG_ 2566841088 EngPcTrqAtPnt2 540;
BA_ "SigType" SG_ 2566841088 EngPcTrqAtPnt2 1;
BA_ "CI_ParId" SG_ 2566841088 EngSpeedAtPnt2 "528";
BA_ "CI_SigId" SG_ 2566841088 EngSpeedAtPnt2 1972;
BA_ "CI_SigName" SG_ 2566841088 EngSpeedAtPnt2 "Engine Speed At Point 2";
BA_ "GenSigTimeoutTime_PCM" SG_ 2566841088 EngSpeedAtPnt2 5000;
BA_ "SPN" SG_ 2566841088 EngSpeedAtPnt2 528;
BA_ "SigType" SG_ 2566841088 EngSpeedAtPnt2 1;
BA_ "CI_ParId" SG_ 2566841088 EngPcTrqAtIdlePnt1 "539";
BA_ "CI_SigId" SG_ 2566841088 EngPcTrqAtIdlePnt1 1971;
BA_ "CI_SigName" SG_ 2566841088 EngPcTrqAtIdlePnt1 "Engine Percent Torque At Idle, Point 1";
BA_ "GenSigTimeoutTime_PCM" SG_ 2566841088 EngPcTrqAtIdlePnt1 5000;
BA_ "SPN" SG_ 2566841088 EngPcTrqAtIdlePnt1 539;
BA_ "SigType" SG_ 2566841088 EngPcTrqAtIdlePnt1 1;
BA_ "CI_ParId" SG_ 2566841088 EngSpeedAtIdlePnt1 "188";
BA_ "CI_SigId" SG_ 2566841088 EngSpeedAtIdlePnt1 1970;
BA_ "CI_SigName" SG_ 2566841088 EngSpeedAtIdlePnt1 "Engine Speed At Idle, Point 1";
BA_ "GenSigTimeoutTime_PCM" SG_ 2566841088 EngSpeedAtIdlePnt1 5000;
BA_ "SPN" SG_ 2566841088 EngSpeedAtIdlePnt1 188;
BA_ "SigType" SG_ 2566841088 EngSpeedAtIdlePnt1 1;
BA_ "CI_ParId" SG_ 2566767877 EcuHwId "6714";
BA_ "CI_SigId" SG_ 2566767877 EcuHwId 41046;
BA_ "CI_SigName" SG_ 2566767877 EcuHwId "ECU Hardware ID";
BA_ "SPN" SG_ 2566767877 EcuHwId 6714;
BA_ "SigType" SG_ 2566767877 EcuHwId 8;
BA_ "CI_ParId" SG_ 2566767877 EcuManName "4304";
BA_ "CI_SigId" SG_ 2566767877 EcuManName 41045;
BA_ "CI_SigName" SG_ 2566767877 EcuManName "ECU Manufacturer Name";
BA_ "SPN" SG_ 2566767877 EcuManName 4304;
BA_ "SigType" SG_ 2566767877 EcuManName 8;
BA_ "CI_ParId" SG_ 2566767877 EcuType "2904";
BA_ "CI_SigId" SG_ 2566767877 EcuType 41044;
BA_ "CI_SigName" SG_ 2566767877 EcuType "ECU Type";
BA_ "SPN" SG_ 2566767877 EcuType 2904;
BA_ "SigType" SG_ 2566767877 EcuType 8;
BA_ "CI_ParId" SG_ 2566767877 EcuLoc "2903";
BA_ "CI_SigId" SG_ 2566767877 EcuLoc 41043;
BA_ "CI_SigName" SG_ 2566767877 EcuLoc "ECU Location";
BA_ "SPN" SG_ 2566767877 EcuLoc 2903;
BA_ "SigType" SG_ 2566767877 EcuLoc 8;
BA_ "CI_ParId" SG_ 2566767877 EcuSn "2902";
BA_ "CI_SigId" SG_ 2566767877 EcuSn 41042;
BA_ "CI_SigName" SG_ 2566767877 EcuSn "ECU Serial Number";
BA_ "SPN" SG_ 2566767877 EcuSn 2902;
BA_ "SigType" SG_ 2566767877 EcuSn 8;
BA_ "CI_ParId" SG_ 2566767877 EcuPn "2901";
BA_ "CI_SigId" SG_ 2566767877 EcuPn 41041;
BA_ "CI_SigName" SG_ 2566767877 EcuPn "ECU Part Number";
BA_ "SPN" SG_ 2566767877 EcuPn 2901;
BA_ "SigType" SG_ 2566767877 EcuPn 8;
BA_ "CI_ParId" SG_ 2566767879 EcuHwId_FDC507 "6714";
BA_ "CI_SigId" SG_ 2566767879 EcuHwId_FDC507 38540;
BA_ "CI_SigName" SG_ 2566767879 EcuHwId_FDC507 "ECU Hardware ID";
BA_ "SPN" SG_ 2566767879 EcuHwId_FDC507 6714;
BA_ "SigType" SG_ 2566767879 EcuHwId_FDC507 8;
BA_ "CI_ParId" SG_ 2566767879 EcuManName_FDC507 "4304";
BA_ "CI_SigId" SG_ 2566767879 EcuManName_FDC507 38539;
BA_ "CI_SigName" SG_ 2566767879 EcuManName_FDC507 "ECU Manufacturer Name";
BA_ "SPN" SG_ 2566767879 EcuManName_FDC507 4304;
BA_ "SigType" SG_ 2566767879 EcuManName_FDC507 8;
BA_ "CI_ParId" SG_ 2566767879 EcuType_FDC507 "2904";
BA_ "CI_SigId" SG_ 2566767879 EcuType_FDC507 38538;
BA_ "CI_SigName" SG_ 2566767879 EcuType_FDC507 "ECU Type";
BA_ "SPN" SG_ 2566767879 EcuType_FDC507 2904;
BA_ "SigType" SG_ 2566767879 EcuType_FDC507 8;
BA_ "CI_ParId" SG_ 2566767879 EcuLoc_FDC507 "2903";
BA_ "CI_SigId" SG_ 2566767879 EcuLoc_FDC507 38537;
BA_ "CI_SigName" SG_ 2566767879 EcuLoc_FDC507 "ECU Location";
BA_ "SPN" SG_ 2566767879 EcuLoc_FDC507 2903;
BA_ "SigType" SG_ 2566767879 EcuLoc_FDC507 8;
BA_ "CI_ParId" SG_ 2566767879 EcuSn_FDC507 "2902";
BA_ "CI_SigId" SG_ 2566767879 EcuSn_FDC507 38536;
BA_ "CI_SigName" SG_ 2566767879 EcuSn_FDC507 "ECU Serial Number";
BA_ "SPN" SG_ 2566767879 EcuSn_FDC507 2902;
BA_ "SigType" SG_ 2566767879 EcuSn_FDC507 8;
BA_ "CI_ParId" SG_ 2566767879 EcuPn_FDC507 "2901";
BA_ "CI_SigId" SG_ 2566767879 EcuPn_FDC507 38535;
BA_ "CI_SigName" SG_ 2566767879 EcuPn_FDC507 "ECU Part Number";
BA_ "SPN" SG_ 2566767879 EcuPn_FDC507 2901;
BA_ "SigType" SG_ 2566767879 EcuPn_FDC507 8;
BA_ "CI_ParId" SG_ 2566767895 EcuHwId_FDC517 "6714";
BA_ "CI_SigId" SG_ 2566767895 EcuHwId_FDC517 25883;
BA_ "CI_SigName" SG_ 2566767895 EcuHwId_FDC517 "ECU Hardware ID";
BA_ "SPN" SG_ 2566767895 EcuHwId_FDC517 6714;
BA_ "SigType" SG_ 2566767895 EcuHwId_FDC517 8;
BA_ "CI_ParId" SG_ 2566767895 EcuManName_FDC517 "4304";
BA_ "CI_SigId" SG_ 2566767895 EcuManName_FDC517 25882;
BA_ "CI_SigName" SG_ 2566767895 EcuManName_FDC517 "ECU Manufacturer Name";
BA_ "SPN" SG_ 2566767895 EcuManName_FDC517 4304;
BA_ "SigType" SG_ 2566767895 EcuManName_FDC517 8;
BA_ "CI_ParId" SG_ 2566767895 EcuType_FDC517 "2904";
BA_ "CI_SigId" SG_ 2566767895 EcuType_FDC517 25881;
BA_ "CI_SigName" SG_ 2566767895 EcuType_FDC517 "ECU Type";
BA_ "SPN" SG_ 2566767895 EcuType_FDC517 2904;
BA_ "SigType" SG_ 2566767895 EcuType_FDC517 8;
BA_ "CI_ParId" SG_ 2566767895 EcuLoc_FDC517 "2903";
BA_ "CI_SigId" SG_ 2566767895 EcuLoc_FDC517 25880;
BA_ "CI_SigName" SG_ 2566767895 EcuLoc_FDC517 "ECU Location";
BA_ "SPN" SG_ 2566767895 EcuLoc_FDC517 2903;
BA_ "SigType" SG_ 2566767895 EcuLoc_FDC517 8;
BA_ "CI_ParId" SG_ 2566767895 EcuSn_FDC517 "2902";
BA_ "CI_SigId" SG_ 2566767895 EcuSn_FDC517 25879;
BA_ "CI_SigName" SG_ 2566767895 EcuSn_FDC517 "ECU Serial Number";
BA_ "SPN" SG_ 2566767895 EcuSn_FDC517 2902;
BA_ "SigType" SG_ 2566767895 EcuSn_FDC517 8;
BA_ "CI_ParId" SG_ 2566767895 EcuPn_FDC517 "2901";
BA_ "CI_SigId" SG_ 2566767895 EcuPn_FDC517 25878;
BA_ "CI_SigName" SG_ 2566767895 EcuPn_FDC517 "ECU Part Number";
BA_ "SPN" SG_ 2566767895 EcuPn_FDC517 2901;
BA_ "SigType" SG_ 2566767895 EcuPn_FDC517 8;
BA_ "CI_ParId" SG_ 2566767898 EcuHwId_FDC51A "6714";
BA_ "CI_SigId" SG_ 2566767898 EcuHwId_FDC51A 34506;
BA_ "CI_SigName" SG_ 2566767898 EcuHwId_FDC51A "ECU Hardware ID";
BA_ "SPN" SG_ 2566767898 EcuHwId_FDC51A 6714;
BA_ "SigType" SG_ 2566767898 EcuHwId_FDC51A 8;
BA_ "CI_ParId" SG_ 2566767898 EcuManName_FDC51A "4304";
BA_ "CI_SigId" SG_ 2566767898 EcuManName_FDC51A 34505;
BA_ "CI_SigName" SG_ 2566767898 EcuManName_FDC51A "ECU Manufacturer Name";
BA_ "SPN" SG_ 2566767898 EcuManName_FDC51A 4304;
BA_ "SigType" SG_ 2566767898 EcuManName_FDC51A 8;
BA_ "CI_ParId" SG_ 2566767898 EcuType_FDC51A "2904";
BA_ "CI_SigId" SG_ 2566767898 EcuType_FDC51A 34504;
BA_ "CI_SigName" SG_ 2566767898 EcuType_FDC51A "ECU Type";
BA_ "SPN" SG_ 2566767898 EcuType_FDC51A 2904;
BA_ "SigType" SG_ 2566767898 EcuType_FDC51A 8;
BA_ "CI_ParId" SG_ 2566767898 EcuLoc_FDC51A "2903";
BA_ "CI_SigId" SG_ 2566767898 EcuLoc_FDC51A 34503;
BA_ "CI_SigName" SG_ 2566767898 EcuLoc_FDC51A "ECU Location";
BA_ "SPN" SG_ 2566767898 EcuLoc_FDC51A 2903;
BA_ "SigType" SG_ 2566767898 EcuLoc_FDC51A 8;
BA_ "CI_ParId" SG_ 2566767898 EcuSn_FDC51A "2902";
BA_ "CI_SigId" SG_ 2566767898 EcuSn_FDC51A 34502;
BA_ "CI_SigName" SG_ 2566767898 EcuSn_FDC51A "ECU Serial Number";
BA_ "SPN" SG_ 2566767898 EcuSn_FDC51A 2902;
BA_ "SigType" SG_ 2566767898 EcuSn_FDC51A 8;
BA_ "CI_ParId" SG_ 2566767898 EcuPn_FDC51A "2901";
BA_ "CI_SigId" SG_ 2566767898 EcuPn_FDC51A 34501;
BA_ "CI_SigName" SG_ 2566767898 EcuPn_FDC51A "ECU Part Number";
BA_ "SPN" SG_ 2566767898 EcuPn_FDC51A 2901;
BA_ "SigType" SG_ 2566767898 EcuPn_FDC51A 8;
BA_ "CI_ParId" SG_ 2566767901 EcuHwId_FDC51D "6714";
BA_ "CI_SigId" SG_ 2566767901 EcuHwId_FDC51D 25904;
BA_ "CI_SigName" SG_ 2566767901 EcuHwId_FDC51D "ECU Hardware ID";
BA_ "SPN" SG_ 2566767901 EcuHwId_FDC51D 6714;
BA_ "SigType" SG_ 2566767901 EcuHwId_FDC51D 8;
BA_ "CI_ParId" SG_ 2566767901 EcuManName_FDC51D "4304";
BA_ "CI_SigId" SG_ 2566767901 EcuManName_FDC51D 25903;
BA_ "CI_SigName" SG_ 2566767901 EcuManName_FDC51D "ECU Manufacturer Name";
BA_ "SPN" SG_ 2566767901 EcuManName_FDC51D 4304;
BA_ "SigType" SG_ 2566767901 EcuManName_FDC51D 8;
BA_ "CI_ParId" SG_ 2566767901 EcuType_FDC51D "2904";
BA_ "CI_SigId" SG_ 2566767901 EcuType_FDC51D 25902;
BA_ "CI_SigName" SG_ 2566767901 EcuType_FDC51D "ECU Type";
BA_ "SPN" SG_ 2566767901 EcuType_FDC51D 2904;
BA_ "SigType" SG_ 2566767901 EcuType_FDC51D 8;
BA_ "CI_ParId" SG_ 2566767901 EcuLoc_FDC51D "2903";
BA_ "CI_SigId" SG_ 2566767901 EcuLoc_FDC51D 25901;
BA_ "CI_SigName" SG_ 2566767901 EcuLoc_FDC51D "ECU Location";
BA_ "SPN" SG_ 2566767901 EcuLoc_FDC51D 2903;
BA_ "SigType" SG_ 2566767901 EcuLoc_FDC51D 8;
BA_ "CI_ParId" SG_ 2566767901 EcuSn_FDC51D "2902";
BA_ "CI_SigId" SG_ 2566767901 EcuSn_FDC51D 25900;
BA_ "CI_SigName" SG_ 2566767901 EcuSn_FDC51D "ECU Serial Number";
BA_ "SPN" SG_ 2566767901 EcuSn_FDC51D 2902;
BA_ "SigType" SG_ 2566767901 EcuSn_FDC51D 8;
BA_ "CI_ParId" SG_ 2566767901 EcuPn_FDC51D "2901";
BA_ "CI_SigId" SG_ 2566767901 EcuPn_FDC51D 25899;
BA_ "CI_SigName" SG_ 2566767901 EcuPn_FDC51D "ECU Part Number";
BA_ "SPN" SG_ 2566767901 EcuPn_FDC51D 2901;
BA_ "SigType" SG_ 2566767901 EcuPn_FDC51D 8;
BA_ "CI_ParId" SG_ 2566767908 EcuHwId_FDC524 "6714";
BA_ "CI_SigId" SG_ 2566767908 EcuHwId_FDC524 38547;
BA_ "CI_SigName" SG_ 2566767908 EcuHwId_FDC524 "ECU Hardware ID";
BA_ "SPN" SG_ 2566767908 EcuHwId_FDC524 6714;
BA_ "SigType" SG_ 2566767908 EcuHwId_FDC524 8;
BA_ "CI_ParId" SG_ 2566767908 EcuManName_FDC524 "4304";
BA_ "CI_SigId" SG_ 2566767908 EcuManName_FDC524 38546;
BA_ "CI_SigName" SG_ 2566767908 EcuManName_FDC524 "ECU Manufacturer Name";
BA_ "SPN" SG_ 2566767908 EcuManName_FDC524 4304;
BA_ "SigType" SG_ 2566767908 EcuManName_FDC524 8;
BA_ "CI_ParId" SG_ 2566767908 EcuType_FDC524 "2904";
BA_ "CI_SigId" SG_ 2566767908 EcuType_FDC524 38545;
BA_ "CI_SigName" SG_ 2566767908 EcuType_FDC524 "ECU Type";
BA_ "SPN" SG_ 2566767908 EcuType_FDC524 2904;
BA_ "SigType" SG_ 2566767908 EcuType_FDC524 8;
BA_ "CI_ParId" SG_ 2566767908 EcuLoc_FDC524 "2903";
BA_ "CI_SigId" SG_ 2566767908 EcuLoc_FDC524 38544;
BA_ "CI_SigName" SG_ 2566767908 EcuLoc_FDC524 "ECU Location";
BA_ "SPN" SG_ 2566767908 EcuLoc_FDC524 2903;
BA_ "SigType" SG_ 2566767908 EcuLoc_FDC524 8;
BA_ "CI_ParId" SG_ 2566767908 EcuSn_FDC524 "2902";
BA_ "CI_SigId" SG_ 2566767908 EcuSn_FDC524 38543;
BA_ "CI_SigName" SG_ 2566767908 EcuSn_FDC524 "ECU Serial Number";
BA_ "SPN" SG_ 2566767908 EcuSn_FDC524 2902;
BA_ "SigType" SG_ 2566767908 EcuSn_FDC524 8;
BA_ "CI_ParId" SG_ 2566767908 EcuPn_FDC524 "2901";
BA_ "CI_SigId" SG_ 2566767908 EcuPn_FDC524 38542;
BA_ "CI_SigName" SG_ 2566767908 EcuPn_FDC524 "ECU Part Number";
BA_ "SPN" SG_ 2566767908 EcuPn_FDC524 2901;
BA_ "SigType" SG_ 2566767908 EcuPn_FDC524 8;
BA_ "CI_ParId" SG_ 2566767911 EcuHwId_FDC527 "6714";
BA_ "CI_SigId" SG_ 2566767911 EcuHwId_FDC527 25918;
BA_ "CI_SigName" SG_ 2566767911 EcuHwId_FDC527 "ECU Hardware ID";
BA_ "SPN" SG_ 2566767911 EcuHwId_FDC527 6714;
BA_ "SigType" SG_ 2566767911 EcuHwId_FDC527 8;
BA_ "CI_ParId" SG_ 2566767911 EcuManName_FDC527 "4304";
BA_ "CI_SigId" SG_ 2566767911 EcuManName_FDC527 25917;
BA_ "CI_SigName" SG_ 2566767911 EcuManName_FDC527 "ECU Manufacturer Name";
BA_ "SPN" SG_ 2566767911 EcuManName_FDC527 4304;
BA_ "SigType" SG_ 2566767911 EcuManName_FDC527 8;
BA_ "CI_ParId" SG_ 2566767911 EcuType_FDC527 "2904";
BA_ "CI_SigId" SG_ 2566767911 EcuType_FDC527 25916;
BA_ "CI_SigName" SG_ 2566767911 EcuType_FDC527 "ECU Type";
BA_ "SPN" SG_ 2566767911 EcuType_FDC527 2904;
BA_ "SigType" SG_ 2566767911 EcuType_FDC527 8;
BA_ "CI_ParId" SG_ 2566767911 EcuLoc_FDC527 "2903";
BA_ "CI_SigId" SG_ 2566767911 EcuLoc_FDC527 25915;
BA_ "CI_SigName" SG_ 2566767911 EcuLoc_FDC527 "ECU Location";
BA_ "SPN" SG_ 2566767911 EcuLoc_FDC527 2903;
BA_ "SigType" SG_ 2566767911 EcuLoc_FDC527 8;
BA_ "CI_ParId" SG_ 2566767911 EcuSn_FDC527 "2902";
BA_ "CI_SigId" SG_ 2566767911 EcuSn_FDC527 25914;
BA_ "CI_SigName" SG_ 2566767911 EcuSn_FDC527 "ECU Serial Number";
BA_ "SPN" SG_ 2566767911 EcuSn_FDC527 2902;
BA_ "SigType" SG_ 2566767911 EcuSn_FDC527 8;
BA_ "CI_ParId" SG_ 2566767911 EcuPn_FDC527 "2901";
BA_ "CI_SigId" SG_ 2566767911 EcuPn_FDC527 25913;
BA_ "CI_SigName" SG_ 2566767911 EcuPn_FDC527 "ECU Part Number";
BA_ "SPN" SG_ 2566767911 EcuPn_FDC527 2901;
BA_ "SigType" SG_ 2566767911 EcuPn_FDC527 8;
BA_ "CI_ParId" SG_ 2566767919 EcuHwId_FDC52F "6714";
BA_ "CI_SigId" SG_ 2566767919 EcuHwId_FDC52F 25932;
BA_ "CI_SigName" SG_ 2566767919 EcuHwId_FDC52F "ECU Hardware ID";
BA_ "SPN" SG_ 2566767919 EcuHwId_FDC52F 6714;
BA_ "SigType" SG_ 2566767919 EcuHwId_FDC52F 8;
BA_ "CI_ParId" SG_ 2566767919 EcuManName_FDC52F "4304";
BA_ "CI_SigId" SG_ 2566767919 EcuManName_FDC52F 25931;
BA_ "CI_SigName" SG_ 2566767919 EcuManName_FDC52F "ECU Manufacturer Name";
BA_ "SPN" SG_ 2566767919 EcuManName_FDC52F 4304;
BA_ "SigType" SG_ 2566767919 EcuManName_FDC52F 8;
BA_ "CI_ParId" SG_ 2566767919 EcuLoc_FDC52F "2903";
BA_ "CI_SigId" SG_ 2566767919 EcuLoc_FDC52F 25929;
BA_ "CI_SigName" SG_ 2566767919 EcuLoc_FDC52F "ECU Location";
BA_ "SPN" SG_ 2566767919 EcuLoc_FDC52F 2903;
BA_ "SigType" SG_ 2566767919 EcuLoc_FDC52F 8;
BA_ "CI_ParId" SG_ 2566767919 EcuSn_FDC52F "2902";
BA_ "CI_SigId" SG_ 2566767919 EcuSn_FDC52F 25928;
BA_ "CI_SigName" SG_ 2566767919 EcuSn_FDC52F "ECU Serial Number";
BA_ "SPN" SG_ 2566767919 EcuSn_FDC52F 2902;
BA_ "SigType" SG_ 2566767919 EcuSn_FDC52F 8;
BA_ "CI_ParId" SG_ 2566767919 EcuPn_FDC52F "2901";
BA_ "CI_SigId" SG_ 2566767919 EcuPn_FDC52F 25927;
BA_ "CI_SigName" SG_ 2566767919 EcuPn_FDC52F "ECU Part Number";
BA_ "SPN" SG_ 2566767919 EcuPn_FDC52F 2901;
BA_ "SigType" SG_ 2566767919 EcuPn_FDC52F 8;
BA_ "CI_ParId" SG_ 2566767920 EcuHwId_FDC530 "6714";
BA_ "CI_SigId" SG_ 2566767920 EcuHwId_FDC530 34827;
BA_ "CI_SigName" SG_ 2566767920 EcuHwId_FDC530 "ECU Hardware ID";
BA_ "SPN" SG_ 2566767920 EcuHwId_FDC530 6714;
BA_ "SigType" SG_ 2566767920 EcuHwId_FDC530 8;
BA_ "CI_ParId" SG_ 2566767920 EcuManName_FDC530 "4304";
BA_ "CI_SigId" SG_ 2566767920 EcuManName_FDC530 34826;
BA_ "CI_SigName" SG_ 2566767920 EcuManName_FDC530 "ECU Manufacturer Name";
BA_ "SPN" SG_ 2566767920 EcuManName_FDC530 4304;
BA_ "SigType" SG_ 2566767920 EcuManName_FDC530 8;
BA_ "CI_ParId" SG_ 2566767920 EcuType_FDC530 "2904";
BA_ "CI_SigId" SG_ 2566767920 EcuType_FDC530 34825;
BA_ "CI_SigName" SG_ 2566767920 EcuType_FDC530 "ECU Type";
BA_ "SPN" SG_ 2566767920 EcuType_FDC530 2904;
BA_ "SigType" SG_ 2566767920 EcuType_FDC530 8;
BA_ "CI_ParId" SG_ 2566767920 EcuLoc_FDC530 "2903";
BA_ "CI_SigId" SG_ 2566767920 EcuLoc_FDC530 34824;
BA_ "CI_SigName" SG_ 2566767920 EcuLoc_FDC530 "ECU Location";
BA_ "SPN" SG_ 2566767920 EcuLoc_FDC530 2903;
BA_ "SigType" SG_ 2566767920 EcuLoc_FDC530 8;
BA_ "CI_ParId" SG_ 2566767920 EcuSn_FDC530 "2902";
BA_ "CI_SigId" SG_ 2566767920 EcuSn_FDC530 34823;
BA_ "CI_SigName" SG_ 2566767920 EcuSn_FDC530 "ECU Serial Number";
BA_ "SPN" SG_ 2566767920 EcuSn_FDC530 2902;
BA_ "SigType" SG_ 2566767920 EcuSn_FDC530 8;
BA_ "CI_ParId" SG_ 2566767920 EcuPn_FDC530 "2901";
BA_ "CI_SigId" SG_ 2566767920 EcuPn_FDC530 34822;
BA_ "CI_SigName" SG_ 2566767920 EcuPn_FDC530 "ECU Part Number";
BA_ "SPN" SG_ 2566767920 EcuPn_FDC530 2901;
BA_ "SigType" SG_ 2566767920 EcuPn_FDC530 8;
BA_ "CI_ParId" SG_ 2566767923 EcuHwId_FDC533 "6714";
BA_ "CI_SigId" SG_ 2566767923 EcuHwId_FDC533 25939;
BA_ "CI_SigName" SG_ 2566767923 EcuHwId_FDC533 "ECU Hardware ID";
BA_ "SPN" SG_ 2566767923 EcuHwId_FDC533 6714;
BA_ "SigType" SG_ 2566767923 EcuHwId_FDC533 8;
BA_ "CI_ParId" SG_ 2566767923 EcuManName_FDC533 "4304";
BA_ "CI_SigId" SG_ 2566767923 EcuManName_FDC533 25938;
BA_ "CI_SigName" SG_ 2566767923 EcuManName_FDC533 "ECU Manufacturer Name";
BA_ "SPN" SG_ 2566767923 EcuManName_FDC533 4304;
BA_ "SigType" SG_ 2566767923 EcuManName_FDC533 8;
BA_ "CI_ParId" SG_ 2566767923 EcuType_FDC533 "2904";
BA_ "CI_SigId" SG_ 2566767923 EcuType_FDC533 25937;
BA_ "CI_SigName" SG_ 2566767923 EcuType_FDC533 "ECU Type";
BA_ "SPN" SG_ 2566767923 EcuType_FDC533 2904;
BA_ "SigType" SG_ 2566767923 EcuType_FDC533 8;
BA_ "CI_ParId" SG_ 2566767923 EcuLoc_FDC533 "2903";
BA_ "CI_SigId" SG_ 2566767923 EcuLoc_FDC533 25936;
BA_ "CI_SigName" SG_ 2566767923 EcuLoc_FDC533 "ECU Location";
BA_ "SPN" SG_ 2566767923 EcuLoc_FDC533 2903;
BA_ "SigType" SG_ 2566767923 EcuLoc_FDC533 8;
BA_ "CI_ParId" SG_ 2566767923 EcuSn_FDC533 "2902";
BA_ "CI_SigId" SG_ 2566767923 EcuSn_FDC533 25935;
BA_ "CI_SigName" SG_ 2566767923 EcuSn_FDC533 "ECU Serial Number";
BA_ "SPN" SG_ 2566767923 EcuSn_FDC533 2902;
BA_ "SigType" SG_ 2566767923 EcuSn_FDC533 8;
BA_ "CI_ParId" SG_ 2566767923 EcuPn_FDC533 "2901";
BA_ "CI_SigId" SG_ 2566767923 EcuPn_FDC533 25934;
BA_ "CI_SigName" SG_ 2566767923 EcuPn_FDC533 "ECU Part Number";
BA_ "SPN" SG_ 2566767923 EcuPn_FDC533 2901;
BA_ "SigType" SG_ 2566767923 EcuPn_FDC533 8;
BA_ "CI_ParId" SG_ 2566767937 EcuHwId_FDC541 "6714";
BA_ "CI_SigId" SG_ 2566767937 EcuHwId_FDC541 25946;
BA_ "CI_SigName" SG_ 2566767937 EcuHwId_FDC541 "ECU Hardware ID";
BA_ "SPN" SG_ 2566767937 EcuHwId_FDC541 6714;
BA_ "SigType" SG_ 2566767937 EcuHwId_FDC541 8;
BA_ "CI_ParId" SG_ 2566767937 EcuManName_FDC541 "4304";
BA_ "CI_SigId" SG_ 2566767937 EcuManName_FDC541 25945;
BA_ "CI_SigName" SG_ 2566767937 EcuManName_FDC541 "ECU Manufacturer Name";
BA_ "SPN" SG_ 2566767937 EcuManName_FDC541 4304;
BA_ "SigType" SG_ 2566767937 EcuManName_FDC541 8;
BA_ "CI_ParId" SG_ 2566767937 EcuType_FDC541 "2904";
BA_ "CI_SigId" SG_ 2566767937 EcuType_FDC541 25944;
BA_ "CI_SigName" SG_ 2566767937 EcuType_FDC541 "ECU Type";
BA_ "SPN" SG_ 2566767937 EcuType_FDC541 2904;
BA_ "SigType" SG_ 2566767937 EcuType_FDC541 8;
BA_ "CI_ParId" SG_ 2566767937 EcuLoc_FDC541 "2903";
BA_ "CI_SigId" SG_ 2566767937 EcuLoc_FDC541 25943;
BA_ "CI_SigName" SG_ 2566767937 EcuLoc_FDC541 "ECU Location";
BA_ "SPN" SG_ 2566767937 EcuLoc_FDC541 2903;
BA_ "SigType" SG_ 2566767937 EcuLoc_FDC541 8;
BA_ "CI_ParId" SG_ 2566767937 EcuSn_FDC541 "2902";
BA_ "CI_SigId" SG_ 2566767937 EcuSn_FDC541 25942;
BA_ "CI_SigName" SG_ 2566767937 EcuSn_FDC541 "ECU Serial Number";
BA_ "SPN" SG_ 2566767937 EcuSn_FDC541 2902;
BA_ "SigType" SG_ 2566767937 EcuSn_FDC541 8;
BA_ "CI_ParId" SG_ 2566767937 EcuPn_FDC541 "2901";
BA_ "CI_SigId" SG_ 2566767937 EcuPn_FDC541 25941;
BA_ "CI_SigName" SG_ 2566767937 EcuPn_FDC541 "ECU Part Number";
BA_ "SPN" SG_ 2566767937 EcuPn_FDC541 2901;
BA_ "SigType" SG_ 2566767937 EcuPn_FDC541 8;
BA_ "CI_ParId" SG_ 2566767945 EcuHwId_FDC549 "6714";
BA_ "CI_SigId" SG_ 2566767945 EcuHwId_FDC549 34513;
BA_ "CI_SigName" SG_ 2566767945 EcuHwId_FDC549 "ECU Hardware ID";
BA_ "SPN" SG_ 2566767945 EcuHwId_FDC549 6714;
BA_ "SigType" SG_ 2566767945 EcuHwId_FDC549 8;
BA_ "CI_ParId" SG_ 2566767945 EcuManName_FDC549 "4304";
BA_ "CI_SigId" SG_ 2566767945 EcuManName_FDC549 34512;
BA_ "CI_SigName" SG_ 2566767945 EcuManName_FDC549 "ECU Manufacturer Name";
BA_ "SPN" SG_ 2566767945 EcuManName_FDC549 4304;
BA_ "SigType" SG_ 2566767945 EcuManName_FDC549 8;
BA_ "CI_ParId" SG_ 2566767945 EcuType_FDC549 "2904";
BA_ "CI_SigId" SG_ 2566767945 EcuType_FDC549 34511;
BA_ "CI_SigName" SG_ 2566767945 EcuType_FDC549 "ECU Type";
BA_ "SPN" SG_ 2566767945 EcuType_FDC549 2904;
BA_ "SigType" SG_ 2566767945 EcuType_FDC549 8;
BA_ "CI_ParId" SG_ 2566767945 EcuLoc_FDC549 "2903";
BA_ "CI_SigId" SG_ 2566767945 EcuLoc_FDC549 34510;
BA_ "CI_SigName" SG_ 2566767945 EcuLoc_FDC549 "ECU Location";
BA_ "SPN" SG_ 2566767945 EcuLoc_FDC549 2903;
BA_ "SigType" SG_ 2566767945 EcuLoc_FDC549 8;
BA_ "CI_ParId" SG_ 2566767945 EcuSn_FDC549 "2902";
BA_ "CI_SigId" SG_ 2566767945 EcuSn_FDC549 34509;
BA_ "CI_SigName" SG_ 2566767945 EcuSn_FDC549 "ECU Serial Number";
BA_ "SPN" SG_ 2566767945 EcuSn_FDC549 2902;
BA_ "SigType" SG_ 2566767945 EcuSn_FDC549 8;
BA_ "CI_ParId" SG_ 2566767945 EcuPn_FDC549 "2901";
BA_ "CI_SigId" SG_ 2566767945 EcuPn_FDC549 34508;
BA_ "CI_SigName" SG_ 2566767945 EcuPn_FDC549 "ECU Part Number";
BA_ "SPN" SG_ 2566767945 EcuPn_FDC549 2901;
BA_ "SigType" SG_ 2566767945 EcuPn_FDC549 8;
BA_ "CI_ParId" SG_ 2566767946 EcuHwId_FDC54A "6714";
BA_ "CI_SigId" SG_ 2566767946 EcuHwId_FDC54A 25981;
BA_ "CI_SigName" SG_ 2566767946 EcuHwId_FDC54A "ECU Hardware ID";
BA_ "SPN" SG_ 2566767946 EcuHwId_FDC54A 6714;
BA_ "SigType" SG_ 2566767946 EcuHwId_FDC54A 8;
BA_ "CI_ParId" SG_ 2566767946 EcuManName_FDC54A "4304";
BA_ "CI_SigId" SG_ 2566767946 EcuManName_FDC54A 25980;
BA_ "CI_SigName" SG_ 2566767946 EcuManName_FDC54A "ECU Manufacturer Name";
BA_ "SPN" SG_ 2566767946 EcuManName_FDC54A 4304;
BA_ "SigType" SG_ 2566767946 EcuManName_FDC54A 8;
BA_ "CI_ParId" SG_ 2566767946 EcuType_FDC54A "2904";
BA_ "CI_SigId" SG_ 2566767946 EcuType_FDC54A 25979;
BA_ "CI_SigName" SG_ 2566767946 EcuType_FDC54A "ECU Type";
BA_ "SPN" SG_ 2566767946 EcuType_FDC54A 2904;
BA_ "SigType" SG_ 2566767946 EcuType_FDC54A 8;
BA_ "CI_ParId" SG_ 2566767946 EcuLoc_FDC54A "2903";
BA_ "CI_SigId" SG_ 2566767946 EcuLoc_FDC54A 25978;
BA_ "CI_SigName" SG_ 2566767946 EcuLoc_FDC54A "ECU Location";
BA_ "SPN" SG_ 2566767946 EcuLoc_FDC54A 2903;
BA_ "SigType" SG_ 2566767946 EcuLoc_FDC54A 8;
BA_ "CI_ParId" SG_ 2566767946 EcuSn_FDC54A "2902";
BA_ "CI_SigId" SG_ 2566767946 EcuSn_FDC54A 25977;
BA_ "CI_SigName" SG_ 2566767946 EcuSn_FDC54A "ECU Serial Number";
BA_ "SPN" SG_ 2566767946 EcuSn_FDC54A 2902;
BA_ "SigType" SG_ 2566767946 EcuSn_FDC54A 8;
BA_ "CI_ParId" SG_ 2566767946 EcuPn_FDC54A "2901";
BA_ "CI_SigId" SG_ 2566767946 EcuPn_FDC54A 25976;
BA_ "CI_SigName" SG_ 2566767946 EcuPn_FDC54A "ECU Part Number";
BA_ "SPN" SG_ 2566767946 EcuPn_FDC54A 2901;
BA_ "SigType" SG_ 2566767946 EcuPn_FDC54A 8;
BA_ "CI_ParId" SG_ 2566767949 EcuHwId_FDC54D "6714";
BA_ "CI_SigId" SG_ 2566767949 EcuHwId_FDC54D 37241;
BA_ "CI_SigName" SG_ 2566767949 EcuHwId_FDC54D "ECU Hardware ID";
BA_ "SPN" SG_ 2566767949 EcuHwId_FDC54D 6714;
BA_ "SigType" SG_ 2566767949 EcuHwId_FDC54D 8;
BA_ "CI_ParId" SG_ 2566767949 EcuManName_FDC54D "4304";
BA_ "CI_SigId" SG_ 2566767949 EcuManName_FDC54D 37240;
BA_ "CI_SigName" SG_ 2566767949 EcuManName_FDC54D "ECU Manufacturer Name";
BA_ "SPN" SG_ 2566767949 EcuManName_FDC54D 4304;
BA_ "SigType" SG_ 2566767949 EcuManName_FDC54D 8;
BA_ "CI_ParId" SG_ 2566767949 EcuType_FDC54D "2904";
BA_ "CI_SigId" SG_ 2566767949 EcuType_FDC54D 37239;
BA_ "CI_SigName" SG_ 2566767949 EcuType_FDC54D "ECU Type";
BA_ "SPN" SG_ 2566767949 EcuType_FDC54D 2904;
BA_ "SigType" SG_ 2566767949 EcuType_FDC54D 8;
BA_ "CI_ParId" SG_ 2566767949 EcuLoc_FDC54D "2903";
BA_ "CI_SigId" SG_ 2566767949 EcuLoc_FDC54D 37238;
BA_ "CI_SigName" SG_ 2566767949 EcuLoc_FDC54D "ECU Location";
BA_ "SPN" SG_ 2566767949 EcuLoc_FDC54D 2903;
BA_ "SigType" SG_ 2566767949 EcuLoc_FDC54D 8;
BA_ "CI_ParId" SG_ 2566767949 EcuSn_FDC54D "2902";
BA_ "CI_SigId" SG_ 2566767949 EcuSn_FDC54D 37237;
BA_ "CI_SigName" SG_ 2566767949 EcuSn_FDC54D "ECU Serial Number";
BA_ "SPN" SG_ 2566767949 EcuSn_FDC54D 2902;
BA_ "SigType" SG_ 2566767949 EcuSn_FDC54D 8;
BA_ "CI_ParId" SG_ 2566767949 EcuPn_FDC54D "2901";
BA_ "CI_SigId" SG_ 2566767949 EcuPn_FDC54D 37236;
BA_ "CI_SigName" SG_ 2566767949 EcuPn_FDC54D "ECU Part Number";
BA_ "SPN" SG_ 2566767949 EcuPn_FDC54D 2901;
BA_ "SigType" SG_ 2566767949 EcuPn_FDC54D 8;
BA_ "CI_ParId" SG_ 2566767955 EcuHwId_FDC553 "6714";
BA_ "CI_SigId" SG_ 2566767955 EcuHwId_FDC553 25995;
BA_ "CI_SigName" SG_ 2566767955 EcuHwId_FDC553 "ECU Hardware ID";
BA_ "SPN" SG_ 2566767955 EcuHwId_FDC553 6714;
BA_ "SigType" SG_ 2566767955 EcuHwId_FDC553 8;
BA_ "CI_ParId" SG_ 2566767955 EcuManName_FDC553 "4304";
BA_ "CI_SigId" SG_ 2566767955 EcuManName_FDC553 25994;
BA_ "CI_SigName" SG_ 2566767955 EcuManName_FDC553 "ECU Manufacturer Name";
BA_ "SPN" SG_ 2566767955 EcuManName_FDC553 4304;
BA_ "SigType" SG_ 2566767955 EcuManName_FDC553 8;
BA_ "CI_ParId" SG_ 2566767955 EcuType_FDC553 "2904";
BA_ "CI_SigId" SG_ 2566767955 EcuType_FDC553 25993;
BA_ "CI_SigName" SG_ 2566767955 EcuType_FDC553 "ECU Type";
BA_ "SPN" SG_ 2566767955 EcuType_FDC553 2904;
BA_ "SigType" SG_ 2566767955 EcuType_FDC553 8;
BA_ "CI_ParId" SG_ 2566767955 EcuLoc_FDC553 "2903";
BA_ "CI_SigId" SG_ 2566767955 EcuLoc_FDC553 25992;
BA_ "CI_SigName" SG_ 2566767955 EcuLoc_FDC553 "ECU Location";
BA_ "SPN" SG_ 2566767955 EcuLoc_FDC553 2903;
BA_ "SigType" SG_ 2566767955 EcuLoc_FDC553 8;
BA_ "CI_ParId" SG_ 2566767955 EcuSn_FDC553 "2902";
BA_ "CI_SigId" SG_ 2566767955 EcuSn_FDC553 25991;
BA_ "CI_SigName" SG_ 2566767955 EcuSn_FDC553 "ECU Serial Number";
BA_ "SPN" SG_ 2566767955 EcuSn_FDC553 2902;
BA_ "SigType" SG_ 2566767955 EcuSn_FDC553 8;
BA_ "CI_ParId" SG_ 2566767955 EcuPn_FDC553 "2901";
BA_ "CI_SigId" SG_ 2566767955 EcuPn_FDC553 25990;
BA_ "CI_SigName" SG_ 2566767955 EcuPn_FDC553 "ECU Part Number";
BA_ "SPN" SG_ 2566767955 EcuPn_FDC553 2901;
BA_ "SigType" SG_ 2566767955 EcuPn_FDC553 8;
BA_ "CI_ParId" SG_ 2566767992 EcuHwId_FDC578 "6714";
BA_ "CI_SigId" SG_ 2566767992 EcuHwId_FDC578 40189;
BA_ "CI_SigName" SG_ 2566767992 EcuHwId_FDC578 "ECU Hardware ID";
BA_ "SPN" SG_ 2566767992 EcuHwId_FDC578 6714;
BA_ "SigType" SG_ 2566767992 EcuHwId_FDC578 8;
BA_ "CI_ParId" SG_ 2566767992 EcuManName_FDC578 "4304";
BA_ "CI_SigId" SG_ 2566767992 EcuManName_FDC578 40188;
BA_ "CI_SigName" SG_ 2566767992 EcuManName_FDC578 "ECU Manufacturer Name";
BA_ "SPN" SG_ 2566767992 EcuManName_FDC578 4304;
BA_ "SigType" SG_ 2566767992 EcuManName_FDC578 8;
BA_ "CI_ParId" SG_ 2566767992 EcuType_FDC578 "2904";
BA_ "CI_SigId" SG_ 2566767992 EcuType_FDC578 40187;
BA_ "CI_SigName" SG_ 2566767992 EcuType_FDC578 "ECU Type";
BA_ "SPN" SG_ 2566767992 EcuType_FDC578 2904;
BA_ "SigType" SG_ 2566767992 EcuType_FDC578 8;
BA_ "CI_ParId" SG_ 2566767992 EcuLoc_FDC578 "2903";
BA_ "CI_SigId" SG_ 2566767992 EcuLoc_FDC578 40186;
BA_ "CI_SigName" SG_ 2566767992 EcuLoc_FDC578 "ECU Location";
BA_ "SPN" SG_ 2566767992 EcuLoc_FDC578 2903;
BA_ "SigType" SG_ 2566767992 EcuLoc_FDC578 8;
BA_ "CI_ParId" SG_ 2566767992 EcuSn_FDC578 "2902";
BA_ "CI_SigId" SG_ 2566767992 EcuSn_FDC578 40185;
BA_ "CI_SigName" SG_ 2566767992 EcuSn_FDC578 "ECU Serial Number";
BA_ "SPN" SG_ 2566767992 EcuSn_FDC578 2902;
BA_ "SigType" SG_ 2566767992 EcuSn_FDC578 8;
BA_ "CI_ParId" SG_ 2566767992 EcuPn_FDC578 "2901";
BA_ "CI_SigId" SG_ 2566767992 EcuPn_FDC578 40184;
BA_ "CI_SigName" SG_ 2566767992 EcuPn_FDC578 "ECU Part Number";
BA_ "SPN" SG_ 2566767992 EcuPn_FDC578 2901;
BA_ "SigType" SG_ 2566767992 EcuPn_FDC578 8;
BA_ "CI_ParId" SG_ 2566767996 EcuHwId_FDC57C "6714";
BA_ "CI_SigId" SG_ 2566767996 EcuHwId_FDC57C 36826;
BA_ "CI_SigName" SG_ 2566767996 EcuHwId_FDC57C "ECU Hardware ID";
BA_ "SPN" SG_ 2566767996 EcuHwId_FDC57C 6714;
BA_ "SigType" SG_ 2566767996 EcuHwId_FDC57C 8;
BA_ "CI_ParId" SG_ 2566767996 EcuManName_FDC57C "4304";
BA_ "CI_SigId" SG_ 2566767996 EcuManName_FDC57C 36825;
BA_ "CI_SigName" SG_ 2566767996 EcuManName_FDC57C "ECU Manufacturer Name";
BA_ "SPN" SG_ 2566767996 EcuManName_FDC57C 4304;
BA_ "SigType" SG_ 2566767996 EcuManName_FDC57C 8;
BA_ "CI_ParId" SG_ 2566767996 EcuType_FDC57C "2904";
BA_ "CI_SigId" SG_ 2566767996 EcuType_FDC57C 36824;
BA_ "CI_SigName" SG_ 2566767996 EcuType_FDC57C "ECU Type";
BA_ "SPN" SG_ 2566767996 EcuType_FDC57C 2904;
BA_ "SigType" SG_ 2566767996 EcuType_FDC57C 8;
BA_ "CI_ParId" SG_ 2566767996 EcuLoc_FDC57C "2903";
BA_ "CI_SigId" SG_ 2566767996 EcuLoc_FDC57C 36823;
BA_ "CI_SigName" SG_ 2566767996 EcuLoc_FDC57C "ECU Location";
BA_ "SPN" SG_ 2566767996 EcuLoc_FDC57C 2903;
BA_ "SigType" SG_ 2566767996 EcuLoc_FDC57C 8;
BA_ "CI_ParId" SG_ 2566767996 EcuSn_FDC57C "2902";
BA_ "CI_SigId" SG_ 2566767996 EcuSn_FDC57C 36822;
BA_ "CI_SigName" SG_ 2566767996 EcuSn_FDC57C "ECU Serial Number";
BA_ "SPN" SG_ 2566767996 EcuSn_FDC57C 2902;
BA_ "SigType" SG_ 2566767996 EcuSn_FDC57C 8;
BA_ "CI_ParId" SG_ 2566767996 EcuPn_FDC57C "2901";
BA_ "CI_SigId" SG_ 2566767996 EcuPn_FDC57C 36821;
BA_ "CI_SigName" SG_ 2566767996 EcuPn_FDC57C "ECU Part Number";
BA_ "SPN" SG_ 2566767996 EcuPn_FDC57C 2901;
BA_ "SigType" SG_ 2566767996 EcuPn_FDC57C 8;
BA_ "CI_ParId" SG_ 2566768110 EcuPn_FDC5EE "2901";
BA_ "CI_SigId" SG_ 2566768110 EcuPn_FDC5EE 26032;
BA_ "CI_SigName" SG_ 2566768110 EcuPn_FDC5EE "ECU Part Number";
BA_ "SPN" SG_ 2566768110 EcuPn_FDC5EE 2901;
BA_ "SigType" SG_ 2566768110 EcuPn_FDC5EE 8;
BA_ "CI_ParId" SG_ 2566768111 EcuHwId_FDC5EF "6714";
BA_ "CI_SigId" SG_ 2566768111 EcuHwId_FDC5EF 34807;
BA_ "CI_SigName" SG_ 2566768111 EcuHwId_FDC5EF "ECU Hardware ID";
BA_ "SPN" SG_ 2566768111 EcuHwId_FDC5EF 6714;
BA_ "SigType" SG_ 2566768111 EcuHwId_FDC5EF 8;
BA_ "CI_ParId" SG_ 2566768111 EcuManName_FDC5EF "4304";
BA_ "CI_SigId" SG_ 2566768111 EcuManName_FDC5EF 34806;
BA_ "CI_SigName" SG_ 2566768111 EcuManName_FDC5EF "ECU Manufacturer Name";
BA_ "SPN" SG_ 2566768111 EcuManName_FDC5EF 4304;
BA_ "SigType" SG_ 2566768111 EcuManName_FDC5EF 8;
BA_ "CI_ParId" SG_ 2566768111 EcuType_FDC5EF "2904";
BA_ "CI_SigId" SG_ 2566768111 EcuType_FDC5EF 34805;
BA_ "CI_SigName" SG_ 2566768111 EcuType_FDC5EF "ECU Type";
BA_ "SPN" SG_ 2566768111 EcuType_FDC5EF 2904;
BA_ "SigType" SG_ 2566768111 EcuType_FDC5EF 8;
BA_ "CI_ParId" SG_ 2566768111 EcuLoc_FDC5EF "2903";
BA_ "CI_SigId" SG_ 2566768111 EcuLoc_FDC5EF 34804;
BA_ "CI_SigName" SG_ 2566768111 EcuLoc_FDC5EF "ECU Location";
BA_ "SPN" SG_ 2566768111 EcuLoc_FDC5EF 2903;
BA_ "SigType" SG_ 2566768111 EcuLoc_FDC5EF 8;
BA_ "CI_ParId" SG_ 2566768111 EcuSn_FDC5EF "2902";
BA_ "CI_SigId" SG_ 2566768111 EcuSn_FDC5EF 34803;
BA_ "CI_SigName" SG_ 2566768111 EcuSn_FDC5EF "ECU Serial Number";
BA_ "SPN" SG_ 2566768111 EcuSn_FDC5EF 2902;
BA_ "SigType" SG_ 2566768111 EcuSn_FDC5EF 8;
BA_ "CI_ParId" SG_ 2566768111 EcuPn_FDC5EF "2901";
BA_ "CI_SigId" SG_ 2566768111 EcuPn_FDC5EF 34802;
BA_ "CI_SigName" SG_ 2566768111 EcuPn_FDC5EF "ECU Part Number";
BA_ "SPN" SG_ 2566768111 EcuPn_FDC5EF 2901;
BA_ "SigType" SG_ 2566768111 EcuPn_FDC5EF 8;
BA_ "CI_ParId" SG_ 2566768114 EcuHwId_FDC5F2 "6714";
BA_ "CI_SigId" SG_ 2566768114 EcuHwId_FDC5F2 39076;
BA_ "CI_SigName" SG_ 2566768114 EcuHwId_FDC5F2 "ECU Hardware ID";
BA_ "SPN" SG_ 2566768114 EcuHwId_FDC5F2 6714;
BA_ "SigType" SG_ 2566768114 EcuHwId_FDC5F2 8;
BA_ "CI_ParId" SG_ 2566768114 EcuManName_FDC5F2 "4304";
BA_ "CI_SigId" SG_ 2566768114 EcuManName_FDC5F2 39075;
BA_ "CI_SigName" SG_ 2566768114 EcuManName_FDC5F2 "ECU Manufacturer Name";
BA_ "SPN" SG_ 2566768114 EcuManName_FDC5F2 4304;
BA_ "SigType" SG_ 2566768114 EcuManName_FDC5F2 8;
BA_ "CI_ParId" SG_ 2566768114 EcuType_FDC5F2 "2904";
BA_ "CI_SigId" SG_ 2566768114 EcuType_FDC5F2 39074;
BA_ "CI_SigName" SG_ 2566768114 EcuType_FDC5F2 "ECU Type";
BA_ "SPN" SG_ 2566768114 EcuType_FDC5F2 2904;
BA_ "SigType" SG_ 2566768114 EcuType_FDC5F2 8;
BA_ "CI_ParId" SG_ 2566768114 EcuLoc_FDC5F2 "2903";
BA_ "CI_SigId" SG_ 2566768114 EcuLoc_FDC5F2 39073;
BA_ "CI_SigName" SG_ 2566768114 EcuLoc_FDC5F2 "ECU Location";
BA_ "SPN" SG_ 2566768114 EcuLoc_FDC5F2 2903;
BA_ "SigType" SG_ 2566768114 EcuLoc_FDC5F2 8;
BA_ "CI_ParId" SG_ 2566768114 EcuSn_FDC5F2 "2902";
BA_ "CI_SigId" SG_ 2566768114 EcuSn_FDC5F2 39072;
BA_ "CI_SigName" SG_ 2566768114 EcuSn_FDC5F2 "ECU Serial Number";
BA_ "SPN" SG_ 2566768114 EcuSn_FDC5F2 2902;
BA_ "SigType" SG_ 2566768114 EcuSn_FDC5F2 8;
BA_ "CI_ParId" SG_ 2566768114 EcuPn_FDC5F2 "2901";
BA_ "CI_SigId" SG_ 2566768114 EcuPn_FDC5F2 39071;
BA_ "CI_SigName" SG_ 2566768114 EcuPn_FDC5F2 "ECU Part Number";
BA_ "SPN" SG_ 2566768114 EcuPn_FDC5F2 2901;
BA_ "SigType" SG_ 2566768114 EcuPn_FDC5F2 8;
BA_ "CI_ParId" SG_ 2566768115 EcuHwId_FDC5F3 "6714";
BA_ "CI_SigId" SG_ 2566768115 EcuHwId_FDC5F3 33393;
BA_ "CI_SigName" SG_ 2566768115 EcuHwId_FDC5F3 "ECU Hardware ID";
BA_ "SPN" SG_ 2566768115 EcuHwId_FDC5F3 6714;
BA_ "SigType" SG_ 2566768115 EcuHwId_FDC5F3 8;
BA_ "CI_ParId" SG_ 2566768115 EcuManName_FDC5F3 "4304";
BA_ "CI_SigId" SG_ 2566768115 EcuManName_FDC5F3 33392;
BA_ "CI_SigName" SG_ 2566768115 EcuManName_FDC5F3 "ECU Manufacturer Name";
BA_ "SPN" SG_ 2566768115 EcuManName_FDC5F3 4304;
BA_ "SigType" SG_ 2566768115 EcuManName_FDC5F3 8;
BA_ "CI_ParId" SG_ 2566768115 EcuType_FDC5F3 "2904";
BA_ "CI_SigId" SG_ 2566768115 EcuType_FDC5F3 33391;
BA_ "CI_SigName" SG_ 2566768115 EcuType_FDC5F3 "ECU Type";
BA_ "SPN" SG_ 2566768115 EcuType_FDC5F3 2904;
BA_ "SigType" SG_ 2566768115 EcuType_FDC5F3 8;
BA_ "CI_ParId" SG_ 2566768115 EcuLoc_FDC5F3 "2903";
BA_ "CI_SigId" SG_ 2566768115 EcuLoc_FDC5F3 33390;
BA_ "CI_SigName" SG_ 2566768115 EcuLoc_FDC5F3 "ECU Location";
BA_ "SPN" SG_ 2566768115 EcuLoc_FDC5F3 2903;
BA_ "SigType" SG_ 2566768115 EcuLoc_FDC5F3 8;
BA_ "CI_ParId" SG_ 2566768115 EcuSn_FDC5F3 "2902";
BA_ "CI_SigId" SG_ 2566768115 EcuSn_FDC5F3 33389;
BA_ "CI_SigName" SG_ 2566768115 EcuSn_FDC5F3 "ECU Serial Number";
BA_ "SPN" SG_ 2566768115 EcuSn_FDC5F3 2902;
BA_ "SigType" SG_ 2566768115 EcuSn_FDC5F3 8;
BA_ "CI_ParId" SG_ 2566768115 EcuPn_FDC5F3 "2901";
BA_ "CI_SigId" SG_ 2566768115 EcuPn_FDC5F3 33388;
BA_ "CI_SigName" SG_ 2566768115 EcuPn_FDC5F3 "ECU Part Number";
BA_ "SPN" SG_ 2566768115 EcuPn_FDC5F3 2901;
BA_ "SigType" SG_ 2566768115 EcuPn_FDC5F3 8;
BA_ "CI_ParId" SG_ 2566856960 AtDpfAregenSts "3700";
BA_ "CI_SigId" SG_ 2566856960 AtDpfAregenSts 42192;
BA_ "CI_SigName" SG_ 2566856960 AtDpfAregenSts "Aftertreatment Diesel Particulate Filter Active Regeneration Status";
BA_ "GenSigTimeoutTime_PCM" SG_ 2566856960 AtDpfAregenSts 500;
BA_ "SPN" SG_ 2566856960 AtDpfAregenSts 3700;
BA_ "SigType" SG_ 2566856960 AtDpfAregenSts 4;
BA_ "CI_ParId" SG_ 2566856960 FuelType "ID0161";
BA_ "CI_SigId" SG_ 2566856960 FuelType 11394;
BA_ "CI_SigName" SG_ 2566856960 FuelType "Fuel Type";
BA_ "GenSigTimeoutTime_PCM" SG_ 2566856960 FuelType 500;
BA_ "SigType" SG_ 2566856960 FuelType 4;
BA_ "CI_ParId" SG_ 2566856960 AcComprSts "ID0160";
BA_ "CI_SigId" SG_ 2566856960 AcComprSts 11392;
BA_ "CI_SigName" SG_ 2566856960 AcComprSts "A/C Compressor Status ";
BA_ "GenSigTimeoutTime_PCM" SG_ 2566856960 AcComprSts 500;
BA_ "SigType" SG_ 2566856960 AcComprSts 4;
BA_ "CI_ParId" SG_ 2566856960 EdcOpSts "I027";
BA_ "CI_SigId" SG_ 2566856960 EdcOpSts 11389;
BA_ "CI_SigName" SG_ 2566856960 EdcOpSts "EDC Operational Status";
BA_ "GenSigTimeoutTime_PCM" SG_ 2566856960 EdcOpSts 500;
BA_ "CI_ParId" SG_ 2566856960 EngDegrLev "I080";
BA_ "CI_SigId" SG_ 2566856960 EngDegrLev 11388;
BA_ "CI_SigName" SG_ 2566856960 EngDegrLev "Engine Degradation Level";
BA_ "GenSigTimeoutTime_PCM" SG_ 2566856960 EngDegrLev 500;
BA_ "CI_ParId" SG_ 2566856960 FuelFiltHeat "I036";
BA_ "CI_SigId" SG_ 2566856960 FuelFiltHeat 11386;
BA_ "CI_SigName" SG_ 2566856960 FuelFiltHeat "Fuel Filter Heating";
BA_ "GenSigTimeoutTime_PCM" SG_ 2566856960 FuelFiltHeat 500;
BA_ "SigType" SG_ 2566856960 FuelFiltHeat 4;
BA_ "CI_ParId" SG_ 2566856960 WaterInFuelInd1 "97";
BA_ "CI_SigId" SG_ 2566856960 WaterInFuelInd1 11384;
BA_ "CI_SigName" SG_ 2566856960 WaterInFuelInd1 "Water In Fuel Indicator 1";
BA_ "GenSigTimeoutTime_PCM" SG_ 2566856960 WaterInFuelInd1 500;
BA_ "SPN" SG_ 2566856960 WaterInFuelInd1 97;
BA_ "SigType" SG_ 2566856960 WaterInFuelInd1 4;
BA_ "CI_ParId" SG_ 2566856960 EngOilPrsLow "I022";
BA_ "CI_SigId" SG_ 2566856960 EngOilPrsLow 11383;
BA_ "CI_SigName" SG_ 2566856960 EngOilPrsLow "Engine Oil Pressure Low";
BA_ "GenSigTimeoutTime_PCM" SG_ 2566856960 EngOilPrsLow 500;
BA_ "SigType" SG_ 2566856960 EngOilPrsLow 4;
BA_ "CI_ParId" SG_ 2566856960 RegenStsLamp "F021";
BA_ "CI_SigId" SG_ 2566856960 RegenStsLamp 11377;
BA_ "CI_SigName" SG_ 2566856960 RegenStsLamp "Regeneration Status Lamp";
BA_ "GenSigTimeoutTime_PCM" SG_ 2566856960 RegenStsLamp 500;
BA_ "SigType" SG_ 2566856960 RegenStsLamp 4;
BA_ "CI_ParId" SG_ 2566856960 OilLifeMonSts "F031";
BA_ "CI_SigId" SG_ 2566856960 OilLifeMonSts 11375;
BA_ "CI_SigName" SG_ 2566856960 OilLifeMonSts "Oil life monitoring status";
BA_ "GenSigTimeoutTime_PCM" SG_ 2566856960 OilLifeMonSts 500;
BA_ "SigType" SG_ 2566856960 OilLifeMonSts 4;
BA_ "CI_ParId" SG_ 2566856960 ExhGasTempSts "ID0159";
BA_ "CI_SigId" SG_ 2566856960 ExhGasTempSts 11372;
BA_ "CI_SigName" SG_ 2566856960 ExhGasTempSts "Exhaust Gas Temperature Status";
BA_ "GenSigTimeoutTime_PCM" SG_ 2566856960 ExhGasTempSts 500;
BA_ "SigType" SG_ 2566856960 ExhGasTempSts 4;
BA_ "CI_ParId" SG_ 2566856960 VslaSts "I107";
BA_ "CI_SigId" SG_ 2566856960 VslaSts 11371;
BA_ "CI_SigName" SG_ 2566856960 VslaSts "Adjustable Vehicle Speed Limit Status";
BA_ "GenSigTimeoutTime_PCM" SG_ 2566856960 VslaSts 500;
BA_ "SigType" SG_ 2566856960 VslaSts 4;
BA_ "CI_ParId" SG_ 2566856960 ElLoadReq "ID0158";
BA_ "CI_SigId" SG_ 2566856960 ElLoadReq 11369;
BA_ "CI_SigName" SG_ 2566856960 ElLoadReq "Electric Load Request";
BA_ "GenSigTimeoutTime_PCM" SG_ 2566856960 ElLoadReq 500;
BA_ "SigType" SG_ 2566856960 ElLoadReq 4;
BA_ "CI_ParId" SG_ 2566856960 ObdMilSts "IS653";
BA_ "CI_SigId" SG_ 2566856960 ObdMilSts 11368;
BA_ "CI_SigName" SG_ 2566856960 ObdMilSts "OBD MIL Status";
BA_ "GenSigTimeoutTime_PCM" SG_ 2566856960 ObdMilSts 500;
BA_ "SigType" SG_ 2566856960 ObdMilSts 4;
BA_ "CI_ParId" SG_ 2566856960 MaxVslSetp "I025";
BA_ "CI_SigId" SG_ 2566856960 MaxVslSetp 11366;
BA_ "CI_SigName" SG_ 2566856960 MaxVslSetp "Maximum Vehicle Speed Limit Setpoint";
BA_ "GenSigTimeoutTime_PCM" SG_ 2566856960 MaxVslSetp 500;
BA_ "SigType" SG_ 2566856960 MaxVslSetp 1;
BA_ "CI_ParId" SG_ 2566856960 EngOverTemp "I254";
BA_ "CI_SigId" SG_ 2566856960 EngOverTemp 11364;
BA_ "CI_SigName" SG_ 2566856960 EngOverTemp "Engine Over Temperature";
BA_ "GenSigTimeoutTime_PCM" SG_ 2566856960 EngOverTemp 500;
BA_ "CI_ParId" SG_ 2566856960 UnsuccRegenStsLamp1 "F030";
BA_ "CI_SigId" SG_ 2566856960 UnsuccRegenStsLamp1 11362;
BA_ "CI_SigName" SG_ 2566856960 UnsuccRegenStsLamp1 "Unsuccessful Regeneration Status Lamp 1";
BA_ "GenSigTimeoutTime_PCM" SG_ 2566856960 UnsuccRegenStsLamp1 500;
BA_ "CI_ParId" SG_ 2566856960 EngOverspeed "I023";
BA_ "CI_SigId" SG_ 2566856960 EngOverspeed 11360;
BA_ "CI_SigName" SG_ 2566856960 EngOverspeed "Engine Overspeed";
BA_ "GenSigTimeoutTime_PCM" SG_ 2566856960 EngOverspeed 500;
BA_ "SigType" SG_ 2566856960 EngOverspeed 4;
BA_ "CI_ParId" SG_ 2566856960 VslSts "I024";
BA_ "CI_SigId" SG_ 2566856960 VslSts 11358;
BA_ "CI_SigName" SG_ 2566856960 VslSts "Vehicle Speed Limiter Status";
BA_ "GenSigTimeoutTime_PCM" SG_ 2566856960 VslSts 500;
BA_ "SigType" SG_ 2566856960 VslSts 4;
BA_ "CI_ParId" SG_ 2566856960 FuelBlkByImmo "I019";
BA_ "CI_SigId" SG_ 2566856960 FuelBlkByImmo 11356;
BA_ "CI_SigName" SG_ 2566856960 FuelBlkByImmo "Fuel Blocked by Immobilizer";
BA_ "GenSigStartValue" SG_ 2566856960 FuelBlkByImmo 3;
BA_ "GenSigTimeoutTime_PCM" SG_ 2566856960 FuelBlkByImmo 500;
BA_ "SigType" SG_ 2566856960 FuelBlkByImmo 4;
BA_ "CI_ParId" SG_ 2566856960 AtDpfSts "3701";
BA_ "CI_SigId" SG_ 2566856960 AtDpfSts 43017;
BA_ "CI_SigName" SG_ 2566856960 AtDpfSts "Aftertreatment Diesel Particulate Filter Status";
BA_ "GenSigTimeoutTime_PCM" SG_ 2566856960 AtDpfSts 500;
BA_ "SPN" SG_ 2566856960 AtDpfSts 3701;
BA_ "CI_ParId" SG_ 2364539904 EngDemPcTrq "2432";
BA_ "CI_SigId" SG_ 2364539904 EngDemPcTrq 1791;
BA_ "CI_SigName" SG_ 2364539904 EngDemPcTrq "Engine Demand - Percent Torque";
BA_ "GenSigTimeoutTime_PCM" SG_ 2364539904 EngDemPcTrq 500;
BA_ "SPN" SG_ 2364539904 EngDemPcTrq 2432;
BA_ "SigType" SG_ 2364539904 EngDemPcTrq 1;
BA_ "CI_ParId" SG_ 2364539904 EngStarterMode "1675";
BA_ "CI_SigId" SG_ 2364539904 EngStarterMode 1790;
BA_ "CI_SigName" SG_ 2364539904 EngStarterMode "Engine Starter Mode";
BA_ "GenSigStartValue" SG_ 2364539904 EngStarterMode 15;
BA_ "GenSigTimeoutTime_PCM" SG_ 2364539904 EngStarterMode 500;
BA_ "SPN" SG_ 2364539904 EngStarterMode 1675;
BA_ "CI_ParId" SG_ 2364539904 SaOfCtrlDevForEngCtrl "1483";
BA_ "CI_SigId" SG_ 2364539904 SaOfCtrlDevForEngCtrl 1789;
BA_ "CI_SigName" SG_ 2364539904 SaOfCtrlDevForEngCtrl "Source Address of Controlling Device for Engine Control";
BA_ "GenSigTimeoutTime_PCM" SG_ 2364539904 SaOfCtrlDevForEngCtrl 500;
BA_ "SPN" SG_ 2364539904 SaOfCtrlDevForEngCtrl 1483;
BA_ "SigType" SG_ 2364539904 SaOfCtrlDevForEngCtrl 1;
BA_ "CI_ParId" SG_ 2364539904 EngSpeed "190";
BA_ "CI_SigId" SG_ 2364539904 EngSpeed 1788;
BA_ "CI_SigName" SG_ 2364539904 EngSpeed "Engine Speed";
BA_ "GenSigTimeoutTime_PCM" SG_ 2364539904 EngSpeed 500;
BA_ "SPN" SG_ 2364539904 EngSpeed 190;
BA_ "SigType" SG_ 2364539904 EngSpeed 1;
BA_ "CI_ParId" SG_ 2364539904 ActEngPcTrq "513";
BA_ "CI_SigId" SG_ 2364539904 ActEngPcTrq 1787;
BA_ "CI_SigName" SG_ 2364539904 ActEngPcTrq "Actual Engine - Percent Torque";
BA_ "GenSigTimeoutTime_PCM" SG_ 2364539904 ActEngPcTrq 500;
BA_ "SPN" SG_ 2364539904 ActEngPcTrq 513;
BA_ "SigType" SG_ 2364539904 ActEngPcTrq 1;
BA_ "CI_ParId" SG_ 2364539904 DrivDemEngPcTrq "512";
BA_ "CI_SigId" SG_ 2364539904 DrivDemEngPcTrq 1786;
BA_ "CI_SigName" SG_ 2364539904 DrivDemEngPcTrq "Driver's Demand Engine - Percent Torque";
BA_ "GenSigTimeoutTime_PCM" SG_ 2364539904 DrivDemEngPcTrq 500;
BA_ "SPN" SG_ 2364539904 DrivDemEngPcTrq 512;
BA_ "SigType" SG_ 2364539904 DrivDemEngPcTrq 1;
BA_ "CI_ParId" SG_ 2364539904 ActEngPcTrqFract "4154";
BA_ "CI_SigId" SG_ 2364539904 ActEngPcTrqFract 1785;
BA_ "CI_SigName" SG_ 2364539904 ActEngPcTrqFract "Actual Engine - Percent Torque (Fractional)";
BA_ "GenSigTimeoutTime_PCM" SG_ 2364539904 ActEngPcTrqFract 500;
BA_ "SPN" SG_ 2364539904 ActEngPcTrqFract 4154;
BA_ "CI_ParId" SG_ 2364539904 EngTrqMode "899";
BA_ "CI_SigId" SG_ 2364539904 EngTrqMode 1784;
BA_ "CI_SigName" SG_ 2364539904 EngTrqMode "Engine Torque Mode";
BA_ "GenSigTimeoutTime_PCM" SG_ 2364539904 EngTrqMode 500;
BA_ "SPN" SG_ 2364539904 EngTrqMode 899;
BA_ "CI_ParId" SG_ 2566767104 FuelType_FDC200 "5837";
BA_ "CI_SigId" SG_ 2566767104 FuelType_FDC200 1890;
BA_ "CI_SigName" SG_ 2566767104 FuelType_FDC200 "Fuel Type";
BA_ "GenSigTimeoutTime_PCM" SG_ 2566767104 FuelType_FDC200 5000;
BA_ "SPN" SG_ 2566767104 FuelType_FDC200 5837;
BA_ "CI_ParId" SG_ 2364539648 ActMaxAvEngPcTrq "3357";
BA_ "CI_SigId" SG_ 2364539648 ActMaxAvEngPcTrq 1810;
BA_ "CI_SigName" SG_ 2364539648 ActMaxAvEngPcTrq "Actual Maximum Available Engine - Percent Torque";
BA_ "GenSigTimeoutTime_PCM" SG_ 2364539648 ActMaxAvEngPcTrq 500;
BA_ "SPN" SG_ 2364539648 ActMaxAvEngPcTrq 3357;
BA_ "SigType" SG_ 2364539648 ActMaxAvEngPcTrq 1;
BA_ "CI_ParId" SG_ 2364539648 EngPcLoadAtCurSpeed "92";
BA_ "CI_SigId" SG_ 2364539648 EngPcLoadAtCurSpeed 1803;
BA_ "CI_SigName" SG_ 2364539648 EngPcLoadAtCurSpeed "Engine Percent Load At Current Speed";
BA_ "GenSigTimeoutTime_PCM" SG_ 2364539648 EngPcLoadAtCurSpeed 500;
BA_ "SPN" SG_ 2364539648 EngPcLoadAtCurSpeed 92;
BA_ "SigType" SG_ 2364539648 EngPcLoadAtCurSpeed 1;
BA_ "CI_ParId" SG_ 2364539648 AccPedPos1 "91";
BA_ "CI_SigId" SG_ 2364539648 AccPedPos1 1802;
BA_ "CI_SigName" SG_ 2364539648 AccPedPos1 "Accelerator Pedal Position 1";
BA_ "GenSigTimeoutTime_PCM" SG_ 2364539648 AccPedPos1 500;
BA_ "SPN" SG_ 2364539648 AccPedPos1 91;
BA_ "SigType" SG_ 2364539648 AccPedPos1 1;
BA_ "CI_ParId" SG_ 2364539648 AccPedKdSw "559";
BA_ "CI_SigId" SG_ 2364539648 AccPedKdSw 1799;
BA_ "CI_SigName" SG_ 2364539648 AccPedKdSw "Accelerator Pedal Kickdown Switch";
BA_ "GenSigTimeoutTime_PCM" SG_ 2364539648 AccPedKdSw 500;
BA_ "SPN" SG_ 2364539648 AccPedKdSw 559;
BA_ "SigType" SG_ 2364539648 AccPedKdSw 4;
BA_ "CI_ParId" SG_ 2364539648 AccPed1LowIdleSw "558";
BA_ "CI_SigId" SG_ 2364539648 AccPed1LowIdleSw 1798;
BA_ "CI_SigName" SG_ 2364539648 AccPed1LowIdleSw "Accelerator Pedal 1 Low Idle Switch";
BA_ "GenSigTimeoutTime_PCM" SG_ 2364539648 AccPed1LowIdleSw 500;
BA_ "SPN" SG_ 2364539648 AccPed1LowIdleSw 558;
BA_ "SigType" SG_ 2364539648 AccPed1LowIdleSw 4;
BA_ "CI_ParId" SG_ 2566840064 EstEngParLossPcTrq "2978";
BA_ "CI_SigId" SG_ 2566840064 EstEngParLossPcTrq 1836;
BA_ "CI_SigName" SG_ 2566840064 EstEngParLossPcTrq "Estimated Engine Parasitic Losses - Percent Torque";
BA_ "GenSigTimeoutTime_PCM" SG_ 2566840064 EstEngParLossPcTrq 1250;
BA_ "SPN" SG_ 2566840064 EstEngParLossPcTrq 2978;
BA_ "SigType" SG_ 2566840064 EstEngParLossPcTrq 1;
BA_ "CI_ParId" SG_ 2566840064 EngDesOpSpeedAsymAdj "519";
BA_ "CI_SigId" SG_ 2566840064 EngDesOpSpeedAsymAdj 1835;
BA_ "CI_SigName" SG_ 2566840064 EngDesOpSpeedAsymAdj "Engine's Desired Operating Speed Asymmetry Adjustment";
BA_ "GenSigTimeoutTime_PCM" SG_ 2566840064 EngDesOpSpeedAsymAdj 1250;
BA_ "SPN" SG_ 2566840064 EngDesOpSpeedAsymAdj 519;
BA_ "CI_ParId" SG_ 2566840064 EngDesOpSpeed "515";
BA_ "CI_SigId" SG_ 2566840064 EngDesOpSpeed 1834;
BA_ "CI_SigName" SG_ 2566840064 EngDesOpSpeed "Engine's Desired Operating Speed";
BA_ "GenSigTimeoutTime_PCM" SG_ 2566840064 EngDesOpSpeed 1250;
BA_ "SPN" SG_ 2566840064 EngDesOpSpeed 515;
BA_ "SigType" SG_ 2566840064 EngDesOpSpeed 1;
BA_ "CI_ParId" SG_ 2566840064 NomFrictPcTrq "514";
BA_ "CI_SigId" SG_ 2566840064 NomFrictPcTrq 1833;
BA_ "CI_SigName" SG_ 2566840064 NomFrictPcTrq "Nominal Friction - Percent Torque";
BA_ "GenSigTimeoutTime_PCM" SG_ 2566840064 NomFrictPcTrq 1250;
BA_ "SPN" SG_ 2566840064 NomFrictPcTrq 514;
BA_ "SigType" SG_ 2566840064 NomFrictPcTrq 1;
BA_ "CI_ParId" SG_ 2566844160 EngCoolPrs1 "109";
BA_ "CI_SigId" SG_ 2566844160 EngCoolPrs1 2048;
BA_ "CI_SigName" SG_ 2566844160 EngCoolPrs1 "Engine Coolant Pressure 1";
BA_ "GenSigTimeoutTime_PCM" SG_ 2566844160 EngCoolPrs1 2500;
BA_ "SPN" SG_ 2566844160 EngCoolPrs1 109;
BA_ "SigType" SG_ 2566844160 EngCoolPrs1 1;
BA_ "CI_ParId" SG_ 2566844160 EngOilLev "98";
BA_ "CI_SigId" SG_ 2566844160 EngOilLev 2045;
BA_ "CI_SigName" SG_ 2566844160 EngOilLev "Engine Oil Level";
BA_ "GenSigTimeoutTime_PCM" SG_ 2566844160 EngOilLev 2500;
BA_ "SPN" SG_ 2566844160 EngOilLev 98;
BA_ "SigType" SG_ 2566844160 EngOilLev 1;
BA_ "CI_ParId" SG_ 2566898290 ApplCnt "I193";
BA_ "CI_SigId" SG_ 2566898290 ApplCnt 10990;
BA_ "CI_SigName" SG_ 2566898290 ApplCnt "Application Counter (4 bits)";
BA_ "GenSigTimeoutTime_PCM" SG_ 2566898290 ApplCnt 500;
BA_ "CI_ParId" SG_ 2566898290 MssSts "I002";
BA_ "CI_SigId" SG_ 2566898290 MssSts 10987;
BA_ "CI_SigName" SG_ 2566898290 MssSts "Multiple State Switch Status";
BA_ "GenSigTimeoutTime_PCM" SG_ 2566898290 MssSts 500;
BA_ "CI_ParId" SG_ 2566898290 BbPwrCons "IS738";
BA_ "CI_SigId" SG_ 2566898290 BbPwrCons 10983;
BA_ "CI_SigName" SG_ 2566898290 BbPwrCons "BB Power Consumption";
BA_ "GenSigTimeoutTime_PCM" SG_ 2566898290 BbPwrCons 500;
BA_ "SigType" SG_ 2566898290 BbPwrCons 1;
BA_ "CI_ParId" SG_ 2566898290 ReqIscRes "IS736";
BA_ "CI_SigId" SG_ 2566898290 ReqIscRes 10976;
BA_ "CI_SigName" SG_ 2566898290 ReqIscRes "Request ISC Resume";
BA_ "GenSigTimeoutTime_PCM" SG_ 2566898290 ReqIscRes 500;
BA_ "SigType" SG_ 2566898290 ReqIscRes 4;
BA_ "CI_ParId" SG_ 2566898290 ReqIscOff "IS737";
BA_ "CI_SigId" SG_ 2566898290 ReqIscOff 10975;
BA_ "CI_SigName" SG_ 2566898290 ReqIscOff "Request ISC Off";
BA_ "GenSigTimeoutTime_PCM" SG_ 2566898290 ReqIscOff 500;
BA_ "SigType" SG_ 2566898290 ReqIscOff 4;
BA_ "CI_ParId" SG_ 2566898290 EngStartSw "IS002";
BA_ "CI_SigId" SG_ 2566898290 EngStartSw 10972;
BA_ "CI_SigName" SG_ 2566898290 EngStartSw "Engine Start Switch";
BA_ "GenSigTimeoutTime_PCM" SG_ 2566898290 EngStartSw 500;
BA_ "SigType" SG_ 2566898290 EngStartSw 4;
BA_ "CI_ParId" SG_ 2566898290 EngStopSw "IS003";
BA_ "CI_SigId" SG_ 2566898290 EngStopSw 10971;
BA_ "CI_SigName" SG_ 2566898290 EngStopSw "Engine Stop Switch";
BA_ "GenSigTimeoutTime_PCM" SG_ 2566898290 EngStopSw 500;
BA_ "SigType" SG_ 2566898290 EngStopSw 4;
BA_ "CI_ParId" SG_ 2566911858 MaxVsl_FFF772 "74";
BA_ "CI_SigId" SG_ 2566911858 MaxVsl_FFF772 10995;
BA_ "CI_SigName" SG_ 2566911858 MaxVsl_FFF772 "Maximum Vehicle Speed Limit";
BA_ "GenSigTimeoutTime_PCM" SG_ 2566911858 MaxVsl_FFF772 500;
BA_ "SPN" SG_ 2566911858 MaxVsl_FFF772 74;
BA_ "SigType" SG_ 2566911858 MaxVsl_FFF772 1;
BA_ "CI_ParId" SG_ 2566911858 CcAccelSw_FFF772 "602";
BA_ "CI_SigId" SG_ 2566911858 CcAccelSw_FFF772 10994;
BA_ "CI_SigName" SG_ 2566911858 CcAccelSw_FFF772 "Cruise Control Accelerate Switch";
BA_ "GenSigTimeoutTime_PCM" SG_ 2566911858 CcAccelSw_FFF772 500;
BA_ "SPN" SG_ 2566911858 CcAccelSw_FFF772 602;
BA_ "SigType" SG_ 2566911858 CcAccelSw_FFF772 4;
BA_ "CI_ParId" SG_ 2566911858 CcCoastDecelSw_FFF772 "600";
BA_ "CI_SigId" SG_ 2566911858 CcCoastDecelSw_FFF772 10993;
BA_ "CI_SigName" SG_ 2566911858 CcCoastDecelSw_FFF772 "Cruise Control Coast (Decelerate) Switch";
BA_ "GenSigTimeoutTime_PCM" SG_ 2566911858 CcCoastDecelSw_FFF772 500;
BA_ "SPN" SG_ 2566911858 CcCoastDecelSw_FFF772 600;
BA_ "SigType" SG_ 2566911858 CcCoastDecelSw_FFF772 4;
BA_ "CI_ParId" SG_ 2566911858 Vsl2Req_FFF772 "I003";
BA_ "CI_SigId" SG_ 2566911858 Vsl2Req_FFF772 10992;
BA_ "CI_SigName" SG_ 2566911858 Vsl2Req_FFF772 "Second Vehicle Speed Limit Request";
BA_ "GenSigTimeoutTime_PCM" SG_ 2566911858 Vsl2Req_FFF772 500;
BA_ "SigType" SG_ 2566911858 Vsl2Req_FFF772 4;
BA_ "CI_ParId" SG_ 2565865505 RetSelNonEng "1716";
BA_ "CI_SigId" SG_ 2565865505 RetSelNonEng 1018;
BA_ "CI_SigName" SG_ 2565865505 RetSelNonEng "Retarder Selection, non-engine";
BA_ "GenSigTimeoutTime_PCM" SG_ 2565865505 RetSelNonEng 500;
BA_ "SPN" SG_ 2565865505 RetSelNonEng 1716;
BA_ "SigType" SG_ 2565865505 RetSelNonEng 1;
BA_ "CI_ParId" SG_ 2565865505 RetEnaBrkAssSw "571";
BA_ "CI_SigId" SG_ 2565865505 RetEnaBrkAssSw 1017;
BA_ "CI_SigName" SG_ 2565865505 RetEnaBrkAssSw "Retarder Enable - Brake Assist Switch";
BA_ "GenSigTimeoutTime_PCM" SG_ 2565865505 RetEnaBrkAssSw 500;
BA_ "SPN" SG_ 2565865505 RetEnaBrkAssSw 571;
BA_ "SigType" SG_ 2565865505 RetEnaBrkAssSw 4;
BA_ "CI_ParId" SG_ 2565865488 ActMaxAvRetPcTrq "1717";
BA_ "CI_SigId" SG_ 2565865488 ActMaxAvRetPcTrq 999;
BA_ "CI_SigName" SG_ 2565865488 ActMaxAvRetPcTrq "Actual Maximum Available Retarder - Percent Torque";
BA_ "GenSigTimeoutTime_PCM" SG_ 2565865488 ActMaxAvRetPcTrq 500;
BA_ "SPN" SG_ 2565865488 ActMaxAvRetPcTrq 1717;
BA_ "SigType" SG_ 2565865488 ActMaxAvRetPcTrq 1;
BA_ "CI_ParId" SG_ 2565865488 SaOfCtrlDevForRetCtrl "1480";
BA_ "CI_SigId" SG_ 2565865488 SaOfCtrlDevForRetCtrl 996;
BA_ "CI_SigName" SG_ 2565865488 SaOfCtrlDevForRetCtrl "Source Address of Controlling Device for Retarder Control";
BA_ "GenSigTimeoutTime_PCM" SG_ 2565865488 SaOfCtrlDevForRetCtrl 500;
BA_ "SPN" SG_ 2565865488 SaOfCtrlDevForRetCtrl 1480;
BA_ "SigType" SG_ 2565865488 SaOfCtrlDevForRetCtrl 1;
BA_ "CI_ParId" SG_ 2565865488 RetReqBrkLight "1667";
BA_ "CI_SigId" SG_ 2565865488 RetReqBrkLight 993;
BA_ "CI_SigName" SG_ 2565865488 RetReqBrkLight "Retarder Requesting Brake Light";
BA_ "GenSigTimeoutTime_PCM" SG_ 2565865488 RetReqBrkLight 500;
BA_ "SPN" SG_ 2565865488 RetReqBrkLight 1667;
BA_ "SigType" SG_ 2565865488 RetReqBrkLight 4;
BA_ "CI_ParId" SG_ 2565865488 IntRetPcTrq "1085";
BA_ "CI_SigId" SG_ 2565865488 IntRetPcTrq 991;
BA_ "CI_SigName" SG_ 2565865488 IntRetPcTrq "Intended Retarder Percent Torque";
BA_ "GenSigTimeoutTime_PCM" SG_ 2565865488 IntRetPcTrq 500;
BA_ "SPN" SG_ 2565865488 IntRetPcTrq 1085;
BA_ "SigType" SG_ 2565865488 IntRetPcTrq 1;
BA_ "CI_ParId" SG_ 2565865488 ActRetPcTrq "520";
BA_ "CI_SigId" SG_ 2565865488 ActRetPcTrq 990;
BA_ "CI_SigName" SG_ 2565865488 ActRetPcTrq "Actual Retarder - Percent Torque";
BA_ "GenSigTimeoutTime_PCM" SG_ 2565865488 ActRetPcTrq 500;
BA_ "SPN" SG_ 2565865488 ActRetPcTrq 520;
BA_ "SigType" SG_ 2565865488 ActRetPcTrq 1;
BA_ "CI_ParId" SG_ 2565865488 RetEnaBrkAssSw_F00010 "571";
BA_ "CI_SigId" SG_ 2565865488 RetEnaBrkAssSw_F00010 988;
BA_ "CI_SigName" SG_ 2565865488 RetEnaBrkAssSw_F00010 "Retarder Enable - Brake Assist Switch";
BA_ "GenSigTimeoutTime_PCM" SG_ 2565865488 RetEnaBrkAssSw_F00010 500;
BA_ "SPN" SG_ 2565865488 RetEnaBrkAssSw_F00010 571;
BA_ "SigType" SG_ 2565865488 RetEnaBrkAssSw_F00010 4;
BA_ "CI_ParId" SG_ 2565865488 RetTrqMode "900";
BA_ "CI_SigId" SG_ 2565865488 RetTrqMode 987;
BA_ "CI_SigName" SG_ 2565865488 RetTrqMode "Retarder Torque Mode";
BA_ "GenSigTimeoutTime_PCM" SG_ 2565865488 RetTrqMode 500;
BA_ "SPN" SG_ 2565865488 RetTrqMode 900;
BA_ "CI_ParId" SG_ 2566843904 EngFuel1Temp1 "174";
BA_ "CI_SigId" SG_ 2566843904 EngFuel1Temp1 2018;
BA_ "CI_SigName" SG_ 2566843904 EngFuel1Temp1 "Engine Fuel 1 Temperature 1";
BA_ "GenSigTimeoutTime_PCM" SG_ 2566843904 EngFuel1Temp1 5000;
BA_ "SPN" SG_ 2566843904 EngFuel1Temp1 174;
BA_ "SigType" SG_ 2566843904 EngFuel1Temp1 1;
BA_ "CI_ParId" SG_ 2566843904 EngCoolTemp "110";
BA_ "CI_SigId" SG_ 2566843904 EngCoolTemp 2017;
BA_ "CI_SigName" SG_ 2566843904 EngCoolTemp "Engine Coolant Temperature";
BA_ "GenSigTimeoutTime_PCM" SG_ 2566843904 EngCoolTemp 5000;
BA_ "SPN" SG_ 2566843904 EngCoolTemp 110;
BA_ "SigType" SG_ 2566843904 EngCoolTemp 1;
BA_ "CI_ParId" SG_ 2364539395 SaOfCtrlDevForTransmCtrl "1482";
BA_ "CI_SigId" SG_ 2364539395 SaOfCtrlDevForTransmCtrl 1262;
BA_ "CI_SigName" SG_ 2364539395 SaOfCtrlDevForTransmCtrl "Source Address of Controlling Device for Transmission Control";
BA_ "GenSigTimeoutTime_PCM" SG_ 2364539395 SaOfCtrlDevForTransmCtrl 500;
BA_ "SPN" SG_ 2364539395 SaOfCtrlDevForTransmCtrl 1482;
BA_ "SigType" SG_ 2364539395 SaOfCtrlDevForTransmCtrl 1;
BA_ "CI_ParId" SG_ 2364539395 TransmInSpeed "161";
BA_ "CI_SigId" SG_ 2364539395 TransmInSpeed 1261;
BA_ "CI_SigName" SG_ 2364539395 TransmInSpeed "Transmission 1 Input Shaft Speed";
BA_ "GenSigTimeoutTime_PCM" SG_ 2364539395 TransmInSpeed 500;
BA_ "SPN" SG_ 2364539395 TransmInSpeed 161;
BA_ "SigType" SG_ 2364539395 TransmInSpeed 1;
BA_ "CI_ParId" SG_ 2364539395 TransmOutSpeed "191";
BA_ "CI_SigId" SG_ 2364539395 TransmOutSpeed 1256;
BA_ "CI_SigName" SG_ 2364539395 TransmOutSpeed "Transmission 1 Output Shaft Speed";
BA_ "GenSigTimeoutTime_PCM" SG_ 2364539395 TransmOutSpeed 500;
BA_ "SPN" SG_ 2364539395 TransmOutSpeed 191;
BA_ "SigType" SG_ 2364539395 TransmOutSpeed 1;
BA_ "CI_ParId" SG_ 2364539395 TransmShiftInProc "574";
BA_ "CI_SigId" SG_ 2364539395 TransmShiftInProc 1254;
BA_ "CI_SigName" SG_ 2364539395 TransmShiftInProc "Transmission Shift In Process";
BA_ "GenSigTimeoutTime_PCM" SG_ 2364539395 TransmShiftInProc 500;
BA_ "SPN" SG_ 2364539395 TransmShiftInProc 574;
BA_ "SigType" SG_ 2364539395 TransmShiftInProc 4;
BA_ "CI_ParId" SG_ 2364539395 TransmTrqConvLckEngd "573";
BA_ "CI_SigId" SG_ 2364539395 TransmTrqConvLckEngd 1253;
BA_ "CI_SigName" SG_ 2364539395 TransmTrqConvLckEngd "Transmission Torque Converter Lockup Engaged";
BA_ "GenSigTimeoutTime_PCM" SG_ 2364539395 TransmTrqConvLckEngd 500;
BA_ "SPN" SG_ 2364539395 TransmTrqConvLckEngd 573;
BA_ "SigType" SG_ 2364539395 TransmTrqConvLckEngd 4;
BA_ "CI_ParId" SG_ 2364539395 TransmDrvlEngd "560";
BA_ "CI_SigId" SG_ 2364539395 TransmDrvlEngd 1252;
BA_ "CI_SigName" SG_ 2364539395 TransmDrvlEngd "Transmission Driveline Engaged";
BA_ "GenSigTimeoutTime_PCM" SG_ 2364539395 TransmDrvlEngd 500;
BA_ "SPN" SG_ 2364539395 TransmDrvlEngd 560;
BA_ "SigType" SG_ 2364539395 TransmDrvlEngd 4;
BA_ "CI_ParId" SG_ 2565866755 TransmCurRng "163";
BA_ "CI_SigId" SG_ 2565866755 TransmCurRng 1293;
BA_ "CI_SigName" SG_ 2565866755 TransmCurRng "Transmission Current Range";
BA_ "GenSigTimeoutTime_PCM" SG_ 2565866755 TransmCurRng 500;
BA_ "SPN" SG_ 2565866755 TransmCurRng 163;
BA_ "SigType" SG_ 2565866755 TransmCurRng 3;
BA_ "CI_ParId" SG_ 2565866755 TransmReqRng "162";
BA_ "CI_SigId" SG_ 2565866755 TransmReqRng 1292;
BA_ "CI_SigName" SG_ 2565866755 TransmReqRng "Transmission Requested Range";
BA_ "GenSigTimeoutTime_PCM" SG_ 2565866755 TransmReqRng 500;
BA_ "SPN" SG_ 2565866755 TransmReqRng 162;
BA_ "SigType" SG_ 2565866755 TransmReqRng 3;
BA_ "CI_ParId" SG_ 2565866755 TransmCurGear "523";
BA_ "CI_SigId" SG_ 2565866755 TransmCurGear 1291;
BA_ "CI_SigName" SG_ 2565866755 TransmCurGear "Transmission Current Gear";
BA_ "GenSigStartValue" SG_ 2565866755 TransmCurGear 255;
BA_ "GenSigTimeoutTime_PCM" SG_ 2565866755 TransmCurGear 500;
BA_ "SPN" SG_ 2565866755 TransmCurGear 523;
BA_ "SigType" SG_ 2565866755 TransmCurGear 1;
BA_ "CI_ParId" SG_ 2565866755 TransmActGr "526";
BA_ "CI_SigId" SG_ 2565866755 TransmActGr 1290;
BA_ "CI_SigName" SG_ 2565866755 TransmActGr "Transmission Actual Gear Ratio";
BA_ "GenSigTimeoutTime_PCM" SG_ 2565866755 TransmActGr 500;
BA_ "SPN" SG_ 2565866755 TransmActGr 526;
BA_ "CI_ParId" SG_ 2565866755 TransmSelGear "524";
BA_ "CI_SigId" SG_ 2565866755 TransmSelGear 1289;
BA_ "CI_SigName" SG_ 2565866755 TransmSelGear "Transmission Selected Gear";
BA_ "GenSigTimeoutTime_PCM" SG_ 2565866755 TransmSelGear 500;
BA_ "SPN" SG_ 2565866755 TransmSelGear 524;
BA_ "SigType" SG_ 2565866755 TransmSelGear 1;
BA_ "CI_ParId" SG_ 2633941763 TransmRevDirSw "767";
BA_ "CI_SigId" SG_ 2633941763 TransmRevDirSw 1326;
BA_ "CI_SigName" SG_ 2633941763 TransmRevDirSw "Transmission Reverse Direction Switch";
BA_ "GenSigSendType" SG_ 2633941763 TransmRevDirSw 3;
BA_ "GenSigTimeoutTime_PCM" SG_ 2633941763 TransmRevDirSw 5000;
BA_ "SPN" SG_ 2633941763 TransmRevDirSw 767;
BA_ "SigType" SG_ 2633941763 TransmRevDirSw 4;
BA_ "CI_ParId" SG_ 2566801923 TransmMode5Ind "4250";
BA_ "CI_SigId" SG_ 2566801923 TransmMode5Ind 1371;
BA_ "CI_SigName" SG_ 2566801923 TransmMode5Ind "Transmission Mode 5 Indicator";
BA_ "GenSigTimeoutTime_PCM" SG_ 2566801923 TransmMode5Ind 500;
BA_ "SPN" SG_ 2566801923 TransmMode5Ind 4250;
BA_ "SigType" SG_ 2566801923 TransmMode5Ind 4;
BA_ "CI_ParId" SG_ 2566801923 TransmMode1Ind "2536";
BA_ "CI_SigId" SG_ 2566801923 TransmMode1Ind 1369;
BA_ "CI_SigName" SG_ 2566801923 TransmMode1Ind "Transmission Mode 1 Indicator";
BA_ "GenSigTimeoutTime_PCM" SG_ 2566801923 TransmMode1Ind 500;
BA_ "SPN" SG_ 2566801923 TransmMode1Ind 2536;
BA_ "SigType" SG_ 2566801923 TransmMode1Ind 4;
BA_ "CI_ParId" SG_ 2566801923 TransmEngCrkEna "2900";
BA_ "CI_SigId" SG_ 2566801923 TransmEngCrkEna 1364;
BA_ "CI_SigName" SG_ 2566801923 TransmEngCrkEna "Transmission Engine Crank Enable";
BA_ "GenSigTimeoutTime_PCM" SG_ 2566801923 TransmEngCrkEna 500;
BA_ "SPN" SG_ 2566801923 TransmEngCrkEna 2900;
BA_ "SigType" SG_ 2566801923 TransmEngCrkEna 4;
BA_ "CI_ParId" SG_ 2364541955 TransmTrqConvRatio "3030";
BA_ "CI_SigId" SG_ 2364541955 TransmTrqConvRatio 1390;
BA_ "CI_SigName" SG_ 2364541955 TransmTrqConvRatio "Transmission Torque Converter Ratio";
BA_ "GenSigTimeoutTime_PCM" SG_ 2364541955 TransmTrqConvRatio 500;
BA_ "SPN" SG_ 2364541955 TransmTrqConvRatio 3030;
BA_ "CI_ParId" SG_ 2431649578 DrivAlertWarn "7473";
BA_ "CI_SigId" SG_ 2431649578 DrivAlertWarn 5836;
BA_ "CI_SigName" SG_ 2431649578 DrivAlertWarn "Driver Alertness Warning";
BA_ "GenSigTimeoutTime_PCM" SG_ 2431649578 DrivAlertWarn 500;
BA_ "SPN" SG_ 2431649578 DrivAlertWarn 7473;
BA_ "CI_ParId" SG_ 2431649578 LaneDepImmLh "1700";
BA_ "CI_SigId" SG_ 2431649578 LaneDepImmLh 5835;
BA_ "CI_SigName" SG_ 2431649578 LaneDepImmLh "Lane Departure Imminent, Left Side";
BA_ "GenSigTimeoutTime_PCM" SG_ 2431649578 LaneDepImmLh 500;
BA_ "SPN" SG_ 2431649578 LaneDepImmLh 1700;
BA_ "SigType" SG_ 2431649578 LaneDepImmLh 4;
BA_ "CI_ParId" SG_ 2431649578 LaneDepImmRh "1701";
BA_ "CI_SigId" SG_ 2431649578 LaneDepImmRh 5834;
BA_ "CI_SigName" SG_ 2431649578 LaneDepImmRh "Lane Departure Imminent, Right Side";
BA_ "GenSigTimeoutTime_PCM" SG_ 2431649578 LaneDepImmRh 500;
BA_ "SPN" SG_ 2431649578 LaneDepImmRh 1701;
BA_ "SigType" SG_ 2431649578 LaneDepImmRh 4;
BA_ "CI_ParId" SG_ 2431649578 LaneDepRight "3566";
BA_ "CI_SigId" SG_ 2431649578 LaneDepRight 5833;
BA_ "CI_SigName" SG_ 2431649578 LaneDepRight "Lane Departure Right";
BA_ "GenSigTimeoutTime_PCM" SG_ 2431649578 LaneDepRight 500;
BA_ "SPN" SG_ 2431649578 LaneDepRight 3566;
BA_ "SigType" SG_ 2431649578 LaneDepRight 4;
BA_ "CI_ParId" SG_ 2431649578 LaneDepLeft "3565";
BA_ "CI_SigId" SG_ 2431649578 LaneDepLeft 5832;
BA_ "CI_SigName" SG_ 2431649578 LaneDepLeft "Lane Departure Left";
BA_ "GenSigTimeoutTime_PCM" SG_ 2431649578 LaneDepLeft 500;
BA_ "SPN" SG_ 2431649578 LaneDepLeft 3565;
BA_ "SigType" SG_ 2431649578 LaneDepLeft 4;
BA_ "CI_ParId" SG_ 2566806314 LdwSysSts "8141";
BA_ "CI_SigId" SG_ 2566806314 LdwSysSts 5849;
BA_ "CI_SigName" SG_ 2566806314 LdwSysSts "Lane Departure Warning System State";
BA_ "GenSigTimeoutTime_PCM" SG_ 2566806314 LdwSysSts 500;
BA_ "SPN" SG_ 2566806314 LdwSysSts 8141;
BA_ "CI_ParId" SG_ 2566806314 LaneDepIndEnaSts "1702";
BA_ "CI_SigId" SG_ 2566806314 LaneDepIndEnaSts 5844;
BA_ "CI_SigName" SG_ 2566806314 LaneDepIndEnaSts "Lane Departure Indication Enable Status";
BA_ "GenSigTimeoutTime_PCM" SG_ 2566806314 LaneDepIndEnaSts 500;
BA_ "SPN" SG_ 2566806314 LaneDepIndEnaSts 1702;
BA_ "SigType" SG_ 2566806314 LaneDepIndEnaSts 4;
BA_ "CI_ParId" SG_ 2566806314 LaneTrackStsLh "1710";
BA_ "CI_SigId" SG_ 2566806314 LaneTrackStsLh 5843;
BA_ "CI_SigName" SG_ 2566806314 LaneTrackStsLh "Lane Tracking Status Left Side";
BA_ "GenSigTimeoutTime_PCM" SG_ 2566806314 LaneTrackStsLh 500;
BA_ "SPN" SG_ 2566806314 LaneTrackStsLh 1710;
BA_ "SigType" SG_ 2566806314 LaneTrackStsLh 4;
BA_ "CI_ParId" SG_ 2566806314 LaneTrackStsRh "1711";
BA_ "CI_SigId" SG_ 2566806314 LaneTrackStsRh 5842;
BA_ "CI_SigName" SG_ 2566806314 LaneTrackStsRh "Lane Tracking Status Right Side";
BA_ "GenSigTimeoutTime_PCM" SG_ 2566806314 LaneTrackStsRh 500;
BA_ "SPN" SG_ 2566806314 LaneTrackStsRh 1711;
BA_ "SigType" SG_ 2566806314 LaneTrackStsRh 4;
BA_ "CI_ParId" SG_ 2566662442 LhLaneMarkerType "8144";
BA_ "CI_SigId" SG_ 2566662442 LhLaneMarkerType 5860;
BA_ "CI_SigName" SG_ 2566662442 LhLaneMarkerType "Left Lane Marker Type";
BA_ "GenSigTimeoutTime_PCM" SG_ 2566662442 LhLaneMarkerType 500;
BA_ "SPN" SG_ 2566662442 LhLaneMarkerType 8144;
BA_ "CI_ParId" SG_ 2566662442 RhLaneMarkerType "8143";
BA_ "CI_SigId" SG_ 2566662442 RhLaneMarkerType 5859;
BA_ "CI_SigName" SG_ 2566662442 RhLaneMarkerType "Right Lane Marker Type";
BA_ "GenSigTimeoutTime_PCM" SG_ 2566662442 RhLaneMarkerType 500;
BA_ "SPN" SG_ 2566662442 RhLaneMarkerType 8143;
BA_ "CI_ParId" SG_ 2566662442 RightDistToLaneMarkFromVehMid "7477";
BA_ "CI_SigId" SG_ 2566662442 RightDistToLaneMarkFromVehMid 5853;
BA_ "CI_SigName" SG_ 2566662442 RightDistToLaneMarkFromVehMid "Right Distance to Lane Mark from Vehicle's Middle";
BA_ "GenSigTimeoutTime_PCM" SG_ 2566662442 RightDistToLaneMarkFromVehMid 500;
BA_ "SPN" SG_ 2566662442 RightDistToLaneMarkFromVehMid 7477;
BA_ "SigType" SG_ 2566662442 RightDistToLaneMarkFromVehMid 1;
BA_ "CI_ParId" SG_ 2566662442 LeftDistToLaneMarkFromVehMid "7476";
BA_ "CI_SigId" SG_ 2566662442 LeftDistToLaneMarkFromVehMid 5852;
BA_ "CI_SigName" SG_ 2566662442 LeftDistToLaneMarkFromVehMid "Left Distance to Lane Mark from Vehicle's Middle";
BA_ "GenSigTimeoutTime_PCM" SG_ 2566662442 LeftDistToLaneMarkFromVehMid 500;
BA_ "SPN" SG_ 2566662442 LeftDistToLaneMarkFromVehMid 7476;
BA_ "SigType" SG_ 2566662442 LeftDistToLaneMarkFromVehMid 1;
BA_ "CI_ParId" SG_ 2561223201 LdwEnaCmd "3564";
BA_ "CI_SigId" SG_ 2561223201 LdwEnaCmd 5863;
BA_ "CI_SigName" SG_ 2561223201 LdwEnaCmd "Lane Departure Warning Enable Command";
BA_ "SPN" SG_ 2561223201 LdwEnaCmd 3564;
BA_ "SigType" SG_ 2561223201 LdwEnaCmd 4;
BA_ "CI_ParId" SG_ 2566749463 FrontFogLight "FMS015";
BA_ "CI_SigId" SG_ 2566749463 FrontFogLight 5976;
BA_ "CI_SigName" SG_ 2566749463 FrontFogLight "Front fog light";
BA_ "GenSigTimeoutTime_PCM" SG_ 2566749463 FrontFogLight 5000;
BA_ "CI_ParId" SG_ 2566749463 LdwSwdOff "FMS015";
BA_ "CI_SigId" SG_ 2566749463 LdwSwdOff 6021;
BA_ "CI_SigName" SG_ 2566749463 LdwSwdOff "Lane departure warning switched off";
BA_ "GenSigTimeoutTime_PCM" SG_ 2566749463 LdwSwdOff 5000;
BA_ "CI_ParId" SG_ 2566749463 PosLightSideLight "FMS014";
BA_ "CI_SigId" SG_ 2566749463 PosLightSideLight 5975;
BA_ "CI_SigName" SG_ 2566749463 PosLightSideLight "Position lights,side lights";
BA_ "GenSigTimeoutTime_PCM" SG_ 2566749463 PosLightSideLight 5000;
BA_ "CI_ParId" SG_ 2566749463 EngCoolLev "FMS014";
BA_ "CI_SigId" SG_ 2566749463 EngCoolLev 5990;
BA_ "CI_SigName" SG_ 2566749463 EngCoolLev "Engine coolant level";
BA_ "GenSigTimeoutTime_PCM" SG_ 2566749463 EngCoolLev 5000;
BA_ "CI_ParId" SG_ 2566749463 EscSwdOff "FMS014";
BA_ "CI_SigId" SG_ 2566749463 EscSwdOff 6020;
BA_ "CI_SigName" SG_ 2566749463 EscSwdOff "ESC switched off";
BA_ "GenSigTimeoutTime_PCM" SG_ 2566749463 EscSwdOff 5000;
BA_ "CI_ParId" SG_ 2566749463 EngOil "FMS013";
BA_ "CI_SigId" SG_ 2566749463 EngOil 5974;
BA_ "CI_SigName" SG_ 2566749463 EngOil "Engine oil";
BA_ "GenSigTimeoutTime_PCM" SG_ 2566749463 EngOil 5000;
BA_ "CI_ParId" SG_ 2566749463 EngOilLev_FD7D17 "FMS013";
BA_ "CI_SigId" SG_ 2566749463 EngOilLev_FD7D17 5989;
BA_ "CI_SigName" SG_ 2566749463 EngOilLev_FD7D17 "Engine oil level";
BA_ "GenSigTimeoutTime_PCM" SG_ 2566749463 EngOilLev_FD7D17 5000;
BA_ "CI_ParId" SG_ 2566749463 TcoInd "FMS013";
BA_ "CI_SigId" SG_ 2566749463 TcoInd 6019;
BA_ "CI_SigName" SG_ 2566749463 TcoInd "Tachograph indication";
BA_ "GenSigTimeoutTime_PCM" SG_ 2566749463 TcoInd 5000;
BA_ "CI_ParId" SG_ 2566749463 BatChgCond "FMS012";
BA_ "CI_SigId" SG_ 2566749463 BatChgCond 5973;
BA_ "CI_SigName" SG_ 2566749463 BatChgCond "Battery charging condition";
BA_ "GenSigTimeoutTime_PCM" SG_ 2566749463 BatChgCond 5000;
BA_ "CI_ParId" SG_ 2566749463 EngCoolTemp_FD7D17 "FMS011";
BA_ "CI_SigId" SG_ 2566749463 EngCoolTemp_FD7D17 5972;
BA_ "CI_SigName" SG_ 2566749463 EngCoolTemp_FD7D17 "Engine coolant temperature";
BA_ "GenSigTimeoutTime_PCM" SG_ 2566749463 EngCoolTemp_FD7D17 5000;
BA_ "CI_ParId" SG_ 2566749463 Malf_GenFail "FMS011";
BA_ "CI_SigId" SG_ 2566749463 Malf_GenFail 5987;
BA_ "CI_SigName" SG_ 2566749463 Malf_GenFail "Malfunction/general failure";
BA_ "GenSigTimeoutTime_PCM" SG_ 2566749463 Malf_GenFail 5000;
BA_ "CI_ParId" SG_ 2566749463 AdblueLev "FMS011";
BA_ "CI_SigId" SG_ 2566749463 AdblueLev 6002;
BA_ "CI_SigName" SG_ 2566749463 AdblueLev "AdBlue level";
BA_ "GenSigTimeoutTime_PCM" SG_ 2566749463 AdblueLev 5000;
BA_ "CI_ParId" SG_ 2566749463 Airbag "FMS011";
BA_ "CI_SigId" SG_ 2566749463 Airbag 6017;
BA_ "CI_SigName" SG_ 2566749463 Airbag "Airbag";
BA_ "GenSigTimeoutTime_PCM" SG_ 2566749463 Airbag 5000;
BA_ "CI_ParId" SG_ 2566749463 FuelLev "FMS010";
BA_ "CI_SigId" SG_ 2566749463 FuelLev 5971;
BA_ "CI_SigName" SG_ 2566749463 FuelLev "Fuel level";
BA_ "GenSigTimeoutTime_PCM" SG_ 2566749463 FuelLev 5000;
BA_ "CI_ParId" SG_ 2566749463 TireFail_Malf "FMS010";
BA_ "CI_SigId" SG_ 2566749463 TireFail_Malf 5986;
BA_ "CI_SigName" SG_ 2566749463 TireFail_Malf "Tire failure/malfunction";
BA_ "GenSigTimeoutTime_PCM" SG_ 2566749463 TireFail_Malf 5000;
BA_ "CI_ParId" SG_ 2566749463 ElMotSts "FMS010";
BA_ "CI_SigId" SG_ 2566749463 ElMotSts 41674;
BA_ "CI_SigName" SG_ 2566749463 ElMotSts "Electric Motor Status";
BA_ "GenSigTimeoutTime_PCM" SG_ 2566749463 ElMotSts 5000;
BA_ "CI_ParId" SG_ 2566749463 HatchOpen "FMS009";
BA_ "CI_SigId" SG_ 2566749463 HatchOpen 5970;
BA_ "CI_SigName" SG_ 2566749463 HatchOpen "Hatch open";
BA_ "GenSigTimeoutTime_PCM" SG_ 2566749463 HatchOpen 5000;
BA_ "CI_ParId" SG_ 2566749463 BatCool "FMS009";
BA_ "CI_SigId" SG_ 2566749463 BatCool 41673;
BA_ "CI_SigName" SG_ 2566749463 BatCool "Battery pack cooling ";
BA_ "GenSigTimeoutTime_PCM" SG_ 2566749463 BatCool 5000;
BA_ "CI_ParId" SG_ 2566749463 BrkFail_BrkSysMalf "FMS008";
BA_ "CI_SigId" SG_ 2566749463 BrkFail_BrkSysMalf 5969;
BA_ "CI_SigName" SG_ 2566749463 BrkFail_BrkSysMalf "Brake failure/brake system malfunction";
BA_ "GenSigTimeoutTime_PCM" SG_ 2566749463 BrkFail_BrkSysMalf 5000;
BA_ "CI_ParId" SG_ 2566749463 WornBrkLin "FMS008";
BA_ "CI_SigId" SG_ 2566749463 WornBrkLin 5984;
BA_ "CI_SigName" SG_ 2566749463 WornBrkLin "Worn brake linings";
BA_ "GenSigTimeoutTime_PCM" SG_ 2566749463 WornBrkLin 5000;
BA_ "CI_ParId" SG_ 2566749463 Acc "FMS008";
BA_ "CI_SigId" SG_ 2566749463 Acc 6014;
BA_ "CI_SigName" SG_ 2566749463 Acc "ACC";
BA_ "GenSigTimeoutTime_PCM" SG_ 2566749463 Acc 5000;
BA_ "CI_ParId" SG_ 2566749463 LimPerfElMot "FMS008";
BA_ "CI_SigId" SG_ 2566749463 LimPerfElMot 41672;
BA_ "CI_SigName" SG_ 2566749463 LimPerfElMot "Limited performance electric motor";
BA_ "GenSigTimeoutTime_PCM" SG_ 2566749463 LimPerfElMot 5000;
BA_ "CI_ParId" SG_ 2566749463 ParkBrk "FMS007";
BA_ "CI_SigId" SG_ 2566749463 ParkBrk 5968;
BA_ "CI_SigName" SG_ 2566749463 ParkBrk "Parking Brake";
BA_ "GenSigTimeoutTime_PCM" SG_ 2566749463 ParkBrk 5000;
BA_ "CI_ParId" SG_ 2566749463 AntiLckBrkSysFail "FMS007";
BA_ "CI_SigId" SG_ 2566749463 AntiLckBrkSysFail 5983;
BA_ "CI_SigName" SG_ 2566749463 AntiLckBrkSysFail "Anti-lock brake system failure";
BA_ "GenSigTimeoutTime_PCM" SG_ 2566749463 AntiLckBrkSysFail 5000;
BA_ "CI_ParId" SG_ 2566749463 Aebs "FMS007";
BA_ "CI_SigId" SG_ 2566749463 Aebs 6013;
BA_ "CI_SigName" SG_ 2566749463 Aebs "Advanced emergency braking system";
BA_ "GenSigTimeoutTime_PCM" SG_ 2566749463 Aebs 5000;
BA_ "CI_ParId" SG_ 2566749463 BatTemp_FD7D17 "FMS007";
BA_ "CI_SigId" SG_ 2566749463 BatTemp_FD7D17 41671;
BA_ "CI_SigName" SG_ 2566749463 BatTemp_FD7D17 "Battery pack temperature";
BA_ "GenSigTimeoutTime_PCM" SG_ 2566749463 BatTemp_FD7D17 5000;
BA_ "CI_ParId" SG_ 2566749463 TransmFail_Malf "FMS006";
BA_ "CI_SigId" SG_ 2566749463 TransmFail_Malf 5982;
BA_ "CI_SigName" SG_ 2566749463 TransmFail_Malf "Transmission failure/malfunction";
BA_ "GenSigTimeoutTime_PCM" SG_ 2566749463 TransmFail_Malf 5000;
BA_ "CI_ParId" SG_ 2566749463 BrkLight "FMS006";
BA_ "CI_SigId" SG_ 2566749463 BrkLight 5997;
BA_ "CI_SigName" SG_ 2566749463 BrkLight "Brake lights";
BA_ "GenSigTimeoutTime_PCM" SG_ 2566749463 BrkLight 5000;
BA_ "CI_ParId" SG_ 2566749463 LaneDepInd "FMS006";
BA_ "CI_SigId" SG_ 2566749463 LaneDepInd 6012;
BA_ "CI_SigName" SG_ 2566749463 LaneDepInd "Lane departure indication";
BA_ "GenSigTimeoutTime_PCM" SG_ 2566749463 LaneDepInd 5000;
BA_ "CI_ParId" SG_ 2566749463 HighVSysCaution "FMS006";
BA_ "CI_SigId" SG_ 2566749463 HighVSysCaution 41670;
BA_ "CI_SigName" SG_ 2566749463 HighVSysCaution "High voltage system caution ";
BA_ "GenSigTimeoutTime_PCM" SG_ 2566749463 HighVSysCaution 5000;
BA_ "CI_ParId" SG_ 2566749463 HazardWarn "FMS005";
BA_ "CI_SigId" SG_ 2566749463 HazardWarn 5966;
BA_ "CI_SigName" SG_ 2566749463 HazardWarn "Hazard warning";
BA_ "GenSigTimeoutTime_PCM" SG_ 2566749463 HazardWarn 5000;
BA_ "CI_ParId" SG_ 2566749463 TransmFluidTemp "FMS005";
BA_ "CI_SigId" SG_ 2566749463 TransmFluidTemp 5981;
BA_ "CI_SigName" SG_ 2566749463 TransmFluidTemp "Transmission fluid temperature";
BA_ "GenSigTimeoutTime_PCM" SG_ 2566749463 TransmFluidTemp 5000;
BA_ "CI_ParId" SG_ 2566749463 EscInd "FMS005";
BA_ "CI_SigId" SG_ 2566749463 EscInd 5996;
BA_ "CI_SigName" SG_ 2566749463 EscInd "ESC indication";
BA_ "GenSigTimeoutTime_PCM" SG_ 2566749463 EscInd 5000;
BA_ "CI_ParId" SG_ 2566749463 Bat "FMS005";
BA_ "CI_SigId" SG_ 2566749463 Bat 41669;
BA_ "CI_SigName" SG_ 2566749463 Bat "Battery pack";
BA_ "GenSigTimeoutTime_PCM" SG_ 2566749463 Bat 5000;
BA_ "CI_ParId" SG_ 2566749463 TurnSigs "FMS004";
BA_ "CI_SigId" SG_ 2566749463 TurnSigs 5965;
BA_ "CI_SigName" SG_ 2566749463 TurnSigs "Turn signals";
BA_ "GenSigTimeoutTime_PCM" SG_ 2566749463 TurnSigs 5000;
BA_ "CI_ParId" SG_ 2566749463 ServCallForMaint "FMS004";
BA_ "CI_SigId" SG_ 2566749463 ServCallForMaint 5980;
BA_ "CI_SigName" SG_ 2566749463 ServCallForMaint "Service, call for maintenance";
BA_ "GenSigTimeoutTime_PCM" SG_ 2566749463 ServCallForMaint 5000;
BA_ "CI_ParId" SG_ 2566749463 EngEmisSysFailMil "FMS004";
BA_ "CI_SigId" SG_ 2566749463 EngEmisSysFailMil 5995;
BA_ "CI_SigName" SG_ 2566749463 EngEmisSysFailMil "Engine Emission system failure -Mil indicator";
BA_ "GenSigTimeoutTime_PCM" SG_ 2566749463 EngEmisSysFailMil 5000;
BA_ "CI_ParId" SG_ 2566749463 SeatBelt "FMS004";
BA_ "CI_SigId" SG_ 2566749463 SeatBelt 6010;
BA_ "CI_SigName" SG_ 2566749463 SeatBelt "Seat belt";
BA_ "GenSigTimeoutTime_PCM" SG_ 2566749463 SeatBelt 5000;
BA_ "CI_ParId" SG_ 2566749463 LowBeamDipBeam "FMS003";
BA_ "CI_SigId" SG_ 2566749463 LowBeamDipBeam 5964;
BA_ "CI_SigName" SG_ 2566749463 LowBeamDipBeam "Low beam, dipped beam";
BA_ "GenSigTimeoutTime_PCM" SG_ 2566749463 LowBeamDipBeam 5000;
BA_ "CI_ParId" SG_ 2566749463 Eng_Mil "FMS003";
BA_ "CI_SigId" SG_ 2566749463 Eng_Mil 5979;
BA_ "CI_SigName" SG_ 2566749463 Eng_Mil "Engine / Mil indicator";
BA_ "GenSigTimeoutTime_PCM" SG_ 2566749463 Eng_Mil 5000;
BA_ "CI_ParId" SG_ 2566749463 Ret "FMS003";
BA_ "CI_SigId" SG_ 2566749463 Ret 5994;
BA_ "CI_SigName" SG_ 2566749463 Ret "Retarder";
BA_ "GenSigTimeoutTime_PCM" SG_ 2566749463 Ret 5000;
BA_ "CI_ParId" SG_ 2566749463 FuelFiltDiffPrs "FMS003";
BA_ "CI_SigId" SG_ 2566749463 FuelFiltDiffPrs 6009;
BA_ "CI_SigName" SG_ 2566749463 FuelFiltDiffPrs "Fuel filter differential pressure";
BA_ "GenSigTimeoutTime_PCM" SG_ 2566749463 FuelFiltDiffPrs 5000;
BA_ "CI_ParId" SG_ 2566749463 HighBeamMainBeam "FMS002";
BA_ "CI_SigId" SG_ 2566749463 HighBeamMainBeam 5963;
BA_ "CI_SigName" SG_ 2566749463 HighBeamMainBeam "High beam, main beam";
BA_ "GenSigTimeoutTime_PCM" SG_ 2566749463 HighBeamMainBeam 5000;
BA_ "CI_ParId" SG_ 2566749463 HtCtrl "FMS002";
BA_ "CI_SigId" SG_ 2566749463 HtCtrl 5993;
BA_ "CI_SigName" SG_ 2566749463 HtCtrl "Height Control (Levelling)";
BA_ "GenSigTimeoutTime_PCM" SG_ 2566749463 HtCtrl 5000;
BA_ "CI_ParId" SG_ 2566749463 AirFiltClog "FMS002";
BA_ "CI_SigId" SG_ 2566749463 AirFiltClog 6008;
BA_ "CI_SigName" SG_ 2566749463 AirFiltClog "Air filter clogged";
BA_ "GenSigTimeoutTime_PCM" SG_ 2566749463 AirFiltClog 5000;
BA_ "CI_ParId" SG_ 2566749463 ElMotFails "FMS002";
BA_ "CI_SigId" SG_ 2566749463 ElMotFails 6023;
BA_ "CI_SigName" SG_ 2566749463 ElMotFails "Electric motor failures";
BA_ "GenSigTimeoutTime_PCM" SG_ 2566749463 ElMotFails 5000;
BA_ "CI_ParId" SG_ 2566749463 RearFogLight "FMS001";
BA_ "CI_SigId" SG_ 2566749463 RearFogLight 5977;
BA_ "CI_SigName" SG_ 2566749463 RearFogLight "Rear fog light";
BA_ "GenSigTimeoutTime_PCM" SG_ 2566749463 RearFogLight 5000;
BA_ "CI_ParId" SG_ 2566749463 EngEmisFilt "FMS001";
BA_ "CI_SigId" SG_ 2566749463 EngEmisFilt 6022;
BA_ "CI_SigName" SG_ 2566749463 EngEmisFilt "Engine emission filter (Soot Filter)";
BA_ "GenSigTimeoutTime_PCM" SG_ 2566749463 EngEmisFilt 5000;
BA_ "CI_ParId" SG_ 2566749463 TtBlkId "FMS000";
BA_ "CI_SigId" SG_ 2566749463 TtBlkId 5961;
BA_ "CI_SigName" SG_ 2566749463 TtBlkId "Telltale Block ID";
BA_ "GenSigTimeoutTime_PCM" SG_ 2566749463 TtBlkId 5000;
BA_ "CI_ParId" SG_ 2566896128 EngInstFuelEcon "184";
BA_ "CI_SigId" SG_ 2566896128 EngInstFuelEcon 2110;
BA_ "CI_SigName" SG_ 2566896128 EngInstFuelEcon "Engine Instantaneous Fuel Economy";
BA_ "GenSigTimeoutTime_PCM" SG_ 2566896128 EngInstFuelEcon 500;
BA_ "SPN" SG_ 2566896128 EngInstFuelEcon 184;
BA_ "SigType" SG_ 2566896128 EngInstFuelEcon 1;
BA_ "CI_ParId" SG_ 2566896128 EngFuelRate "183";
BA_ "CI_SigId" SG_ 2566896128 EngFuelRate 2109;
BA_ "CI_SigName" SG_ 2566896128 EngFuelRate "Engine Fuel Rate";
BA_ "GenSigTimeoutTime_PCM" SG_ 2566896128 EngFuelRate 500;
BA_ "SPN" SG_ 2566896128 EngFuelRate 183;
BA_ "SigType" SG_ 2566896128 EngFuelRate 1;
BA_ "CI_ParId" SG_ 2566841600 EngTotRevl "249";
BA_ "CI_SigId" SG_ 2566841600 EngTotRevl 2072;
BA_ "CI_SigName" SG_ 2566841600 EngTotRevl "Engine Total Revolutions";
BA_ "GenSigTimeoutTime_PCM" SG_ 2566841600 EngTotRevl 5000;
BA_ "SPN" SG_ 2566841600 EngTotRevl 249;
BA_ "SigType" SG_ 2566841600 EngTotRevl 1;
BA_ "CI_ParId" SG_ 2566841600 EngTotHrOfOp "247";
BA_ "CI_SigId" SG_ 2566841600 EngTotHrOfOp 2071;
BA_ "CI_SigName" SG_ 2566841600 EngTotHrOfOp "Engine Total Hours of Operation";
BA_ "GenSigTimeoutTime_PCM" SG_ 2566841600 EngTotHrOfOp 5000;
BA_ "SPN" SG_ 2566841600 EngTotHrOfOp 247;
BA_ "SigType" SG_ 2566841600 EngTotHrOfOp 1;
BA_ "CI_ParId" SG_ 2566719744 EngTotFuelUsedHr "5054";
BA_ "CI_SigId" SG_ 2566719744 EngTotFuelUsedHr 2097;
BA_ "CI_SigName" SG_ 2566719744 EngTotFuelUsedHr "Engine Total Fuel Used (High Resolution)";
BA_ "GenSigTimeoutTime_PCM" SG_ 2566719744 EngTotFuelUsedHr 5000;
BA_ "SPN" SG_ 2566719744 EngTotFuelUsedHr 5054;
BA_ "SigType" SG_ 2566719744 EngTotFuelUsedHr 1;
BA_ "CI_ParId" SG_ 2298375691 RaRSpeed "1595";
BA_ "CI_SigId" SG_ 2298375691 RaRSpeed 727;
BA_ "CI_SigName" SG_ 2298375691 RaRSpeed "Rear axle, right wheel speed";
BA_ "GenSigTimeoutTime_PCM" SG_ 2298375691 RaRSpeed 500;
BA_ "SPN" SG_ 2298375691 RaRSpeed 1595;
BA_ "SigType" SG_ 2298375691 RaRSpeed 1;
BA_ "CI_ParId" SG_ 2298375691 RaLSpeed "1594";
BA_ "CI_SigId" SG_ 2298375691 RaLSpeed 726;
BA_ "CI_SigName" SG_ 2298375691 RaLSpeed "Rear axle, left wheel speed";
BA_ "GenSigTimeoutTime_PCM" SG_ 2298375691 RaLSpeed 500;
BA_ "SPN" SG_ 2298375691 RaLSpeed 1594;
BA_ "SigType" SG_ 2298375691 RaLSpeed 1;
BA_ "CI_ParId" SG_ 2298375691 FaRSpeed "1593";
BA_ "CI_SigId" SG_ 2298375691 FaRSpeed 725;
BA_ "CI_SigName" SG_ 2298375691 FaRSpeed "Front axle, right wheel speed";
BA_ "GenSigTimeoutTime_PCM" SG_ 2298375691 FaRSpeed 500;
BA_ "SPN" SG_ 2298375691 FaRSpeed 1593;
BA_ "SigType" SG_ 2298375691 FaRSpeed 1;
BA_ "CI_ParId" SG_ 2298375691 FaLSpeed "1592";
BA_ "CI_SigId" SG_ 2298375691 FaLSpeed 724;
BA_ "CI_SigName" SG_ 2298375691 FaLSpeed "Front Axle, Left Wheel Speed";
BA_ "GenSigTimeoutTime_PCM" SG_ 2298375691 FaLSpeed 500;
BA_ "SPN" SG_ 2298375691 FaLSpeed 1592;
BA_ "SigType" SG_ 2298375691 FaLSpeed 1;
BA_ "CI_ParId" SG_ 2566609652 Hvesp1CellVminLim "11140";
BA_ "CI_SigId" SG_ 2566609652 Hvesp1CellVminLim 3741;
BA_ "CI_SigName" SG_ 2566609652 Hvesp1CellVminLim "HVESP1 Cell Minimum Voltage Limit";
BA_ "SPN" SG_ 2566609652 Hvesp1CellVminLim 11140;
BA_ "SigType" SG_ 2566609652 Hvesp1CellVminLim 1;
BA_ "CI_ParId" SG_ 2566609652 Hvesp1CellVmaxLim "11139";
BA_ "CI_SigId" SG_ 2566609652 Hvesp1CellVmaxLim 3740;
BA_ "CI_SigName" SG_ 2566609652 Hvesp1CellVmaxLim "HVESP1 Cell Maximum Voltage Limit";
BA_ "SPN" SG_ 2566609652 Hvesp1CellVmaxLim 11139;
BA_ "SigType" SG_ 2566609652 Hvesp1CellVmaxLim 1;
BA_ "CI_ParId" SG_ 2566609652 Hvesp1RecomMinOpTemp "11138";
BA_ "CI_SigId" SG_ 2566609652 Hvesp1RecomMinOpTemp 3739;
BA_ "CI_SigName" SG_ 2566609652 Hvesp1RecomMinOpTemp "HVESP1 Recommended Minimum Operating Temperature";
BA_ "SPN" SG_ 2566609652 Hvesp1RecomMinOpTemp 11138;
BA_ "SigType" SG_ 2566609652 Hvesp1RecomMinOpTemp 1;
BA_ "CI_ParId" SG_ 2566609652 Hvesp1RecomMaxOpTemp "11137";
BA_ "CI_SigId" SG_ 2566609652 Hvesp1RecomMaxOpTemp 3738;
BA_ "CI_SigName" SG_ 2566609652 Hvesp1RecomMaxOpTemp "HVESP1 Recommended Maximum Operating Temperature";
BA_ "SPN" SG_ 2566609652 Hvesp1RecomMaxOpTemp 11137;
BA_ "SigType" SG_ 2566609652 Hvesp1RecomMaxOpTemp 1;
BA_ "CI_ParId" SG_ 2566609652 Hvesp1RecomMaxSoc "11136";
BA_ "CI_SigId" SG_ 2566609652 Hvesp1RecomMaxSoc 3737;
BA_ "CI_SigName" SG_ 2566609652 Hvesp1RecomMaxSoc "HVESP1 Recommended Maximum State Of Charge";
BA_ "SPN" SG_ 2566609652 Hvesp1RecomMaxSoc 11136;
BA_ "SigType" SG_ 2566609652 Hvesp1RecomMaxSoc 1;
BA_ "CI_ParId" SG_ 2566609652 Hvesp1RecomMinSoc "11135";
BA_ "CI_SigId" SG_ 2566609652 Hvesp1RecomMinSoc 3736;
BA_ "CI_SigName" SG_ 2566609652 Hvesp1RecomMinSoc "HVESP1 Recommended Minimum State Of Charge";
BA_ "SPN" SG_ 2566609652 Hvesp1RecomMinSoc 11135;
BA_ "SigType" SG_ 2566609652 Hvesp1RecomMinSoc 1;
BA_ "CI_ParId" SG_ 2566609652 Hvesp1RecomMaxOpV "11134";
BA_ "CI_SigId" SG_ 2566609652 Hvesp1RecomMaxOpV 3735;
BA_ "CI_SigName" SG_ 2566609652 Hvesp1RecomMaxOpV "HVESP1 Recommended Maximum Operating Voltage";
BA_ "SPN" SG_ 2566609652 Hvesp1RecomMaxOpV 11134;
BA_ "SigType" SG_ 2566609652 Hvesp1RecomMaxOpV 1;
BA_ "CI_ParId" SG_ 2566609652 Hvesp1RecomMinOpV "11133";
BA_ "CI_SigId" SG_ 2566609652 Hvesp1RecomMinOpV 3734;
BA_ "CI_SigName" SG_ 2566609652 Hvesp1RecomMinOpV "HVESP1 Recommended Minimum Operating Voltage";
BA_ "SPN" SG_ 2566609652 Hvesp1RecomMinOpV 11133;
BA_ "SigType" SG_ 2566609652 Hvesp1RecomMinOpV 1;
BA_ "CI_ParId" SG_ 2566609652 Hvesp1NomV "11132";
BA_ "CI_SigId" SG_ 2566609652 Hvesp1NomV 3733;
BA_ "CI_SigName" SG_ 2566609652 Hvesp1NomV "HVESP1 Nominal Voltage";
BA_ "SPN" SG_ 2566609652 Hvesp1NomV 11132;
BA_ "SigType" SG_ 2566609652 Hvesp1NomV 1;
BA_ "CI_ParId" SG_ 2566609141 Hvesp2CellVminLim "11256";
BA_ "CI_SigId" SG_ 2566609141 Hvesp2CellVminLim 3751;
BA_ "CI_SigName" SG_ 2566609141 Hvesp2CellVminLim "HVESP2 Cell Minimum Voltage Limit";
BA_ "SPN" SG_ 2566609141 Hvesp2CellVminLim 11256;
BA_ "SigType" SG_ 2566609141 Hvesp2CellVminLim 1;
BA_ "CI_ParId" SG_ 2566609141 Hvesp2CellVmaxLim "11255";
BA_ "CI_SigId" SG_ 2566609141 Hvesp2CellVmaxLim 3750;
BA_ "CI_SigName" SG_ 2566609141 Hvesp2CellVmaxLim "HVESP2 Cell Maximum Voltage Limit";
BA_ "SPN" SG_ 2566609141 Hvesp2CellVmaxLim 11255;
BA_ "SigType" SG_ 2566609141 Hvesp2CellVmaxLim 1;
BA_ "CI_ParId" SG_ 2566609141 Hvesp2RecomMinOpTemp "11254";
BA_ "CI_SigId" SG_ 2566609141 Hvesp2RecomMinOpTemp 3749;
BA_ "CI_SigName" SG_ 2566609141 Hvesp2RecomMinOpTemp "HVESP2 Recommended Minimum Operating Temperature";
BA_ "SPN" SG_ 2566609141 Hvesp2RecomMinOpTemp 11254;
BA_ "SigType" SG_ 2566609141 Hvesp2RecomMinOpTemp 1;
BA_ "CI_ParId" SG_ 2566609141 Hvesp2RecomMaxOpTemp "11253";
BA_ "CI_SigId" SG_ 2566609141 Hvesp2RecomMaxOpTemp 3748;
BA_ "CI_SigName" SG_ 2566609141 Hvesp2RecomMaxOpTemp "HVESP2 Recommended Maximum Operating Temperature";
BA_ "SPN" SG_ 2566609141 Hvesp2RecomMaxOpTemp 11253;
BA_ "SigType" SG_ 2566609141 Hvesp2RecomMaxOpTemp 1;
BA_ "CI_ParId" SG_ 2566609141 Hvesp2RecomMaxSoc "11252";
BA_ "CI_SigId" SG_ 2566609141 Hvesp2RecomMaxSoc 3747;
BA_ "CI_SigName" SG_ 2566609141 Hvesp2RecomMaxSoc "HVESP2 Recommended Maximum State Of Charge";
BA_ "SPN" SG_ 2566609141 Hvesp2RecomMaxSoc 11252;
BA_ "SigType" SG_ 2566609141 Hvesp2RecomMaxSoc 1;
BA_ "CI_ParId" SG_ 2566609141 Hvesp2RecomMinSoc "11251";
BA_ "CI_SigId" SG_ 2566609141 Hvesp2RecomMinSoc 3746;
BA_ "CI_SigName" SG_ 2566609141 Hvesp2RecomMinSoc "HVESP2 Recommended Minimum State Of Charge";
BA_ "SPN" SG_ 2566609141 Hvesp2RecomMinSoc 11251;
BA_ "SigType" SG_ 2566609141 Hvesp2RecomMinSoc 1;
BA_ "CI_ParId" SG_ 2566609141 Hvesp2RecomMaxOpV "11250";
BA_ "CI_SigId" SG_ 2566609141 Hvesp2RecomMaxOpV 3745;
BA_ "CI_SigName" SG_ 2566609141 Hvesp2RecomMaxOpV "HVESP2 Recommended Maximum Operating Voltage";
BA_ "SPN" SG_ 2566609141 Hvesp2RecomMaxOpV 11250;
BA_ "SigType" SG_ 2566609141 Hvesp2RecomMaxOpV 1;
BA_ "CI_ParId" SG_ 2566609141 Hvesp2RecomMinOpV "11249";
BA_ "CI_SigId" SG_ 2566609141 Hvesp2RecomMinOpV 3744;
BA_ "CI_SigName" SG_ 2566609141 Hvesp2RecomMinOpV "HVESP2 Recommended Minimum Operating Voltage";
BA_ "SPN" SG_ 2566609141 Hvesp2RecomMinOpV 11249;
BA_ "SigType" SG_ 2566609141 Hvesp2RecomMinOpV 1;
BA_ "CI_ParId" SG_ 2566609141 Hvesp2NomV "11248";
BA_ "CI_SigId" SG_ 2566609141 Hvesp2NomV 3743;
BA_ "CI_SigName" SG_ 2566609141 Hvesp2NomV "HVESP2 Nominal Voltage";
BA_ "SPN" SG_ 2566609141 Hvesp2NomV 11248;
BA_ "SigType" SG_ 2566609141 Hvesp2NomV 1;
BA_ "CI_ParId" SG_ 2566608630 Hvesp3CellVminLim "11372";
BA_ "CI_SigId" SG_ 2566608630 Hvesp3CellVminLim 3761;
BA_ "CI_SigName" SG_ 2566608630 Hvesp3CellVminLim "HVESP3 Cell Minimum Voltage Limit";
BA_ "SPN" SG_ 2566608630 Hvesp3CellVminLim 11372;
BA_ "SigType" SG_ 2566608630 Hvesp3CellVminLim 1;
BA_ "CI_ParId" SG_ 2566608630 Hvesp3CellVmaxLim "11371";
BA_ "CI_SigId" SG_ 2566608630 Hvesp3CellVmaxLim 3760;
BA_ "CI_SigName" SG_ 2566608630 Hvesp3CellVmaxLim "HVESP3 Cell Maximum Voltage Limit";
BA_ "SPN" SG_ 2566608630 Hvesp3CellVmaxLim 11371;
BA_ "SigType" SG_ 2566608630 Hvesp3CellVmaxLim 1;
BA_ "CI_ParId" SG_ 2566608630 Hvesp3RecomMinOpTemp "11370";
BA_ "CI_SigId" SG_ 2566608630 Hvesp3RecomMinOpTemp 3759;
BA_ "CI_SigName" SG_ 2566608630 Hvesp3RecomMinOpTemp "HVESP3 Recommended Minimum Operating Temperature";
BA_ "SPN" SG_ 2566608630 Hvesp3RecomMinOpTemp 11370;
BA_ "SigType" SG_ 2566608630 Hvesp3RecomMinOpTemp 1;
BA_ "CI_ParId" SG_ 2566608630 Hvesp3RecomMaxOpTemp "11369";
BA_ "CI_SigId" SG_ 2566608630 Hvesp3RecomMaxOpTemp 3758;
BA_ "CI_SigName" SG_ 2566608630 Hvesp3RecomMaxOpTemp "HVESP3 Recommended Maximum Operating Temperature";
BA_ "SPN" SG_ 2566608630 Hvesp3RecomMaxOpTemp 11369;
BA_ "SigType" SG_ 2566608630 Hvesp3RecomMaxOpTemp 1;
BA_ "CI_ParId" SG_ 2566608630 Hvesp3RecomMaxSoc "11368";
BA_ "CI_SigId" SG_ 2566608630 Hvesp3RecomMaxSoc 3757;
BA_ "CI_SigName" SG_ 2566608630 Hvesp3RecomMaxSoc "HVESP3 Recommended Maximum State Of Charge";
BA_ "SPN" SG_ 2566608630 Hvesp3RecomMaxSoc 11368;
BA_ "SigType" SG_ 2566608630 Hvesp3RecomMaxSoc 1;
BA_ "CI_ParId" SG_ 2566608630 Hvesp3RecomMinSoc "11367";
BA_ "CI_SigId" SG_ 2566608630 Hvesp3RecomMinSoc 3756;
BA_ "CI_SigName" SG_ 2566608630 Hvesp3RecomMinSoc "HVESP3 Recommended Minimum State Of Charge";
BA_ "SPN" SG_ 2566608630 Hvesp3RecomMinSoc 11367;
BA_ "SigType" SG_ 2566608630 Hvesp3RecomMinSoc 1;
BA_ "CI_ParId" SG_ 2566608630 Hvesp3RecomMaxOpV "11366";
BA_ "CI_SigId" SG_ 2566608630 Hvesp3RecomMaxOpV 3755;
BA_ "CI_SigName" SG_ 2566608630 Hvesp3RecomMaxOpV "HVESP3 Recommended Maximum Operating Voltage";
BA_ "SPN" SG_ 2566608630 Hvesp3RecomMaxOpV 11366;
BA_ "SigType" SG_ 2566608630 Hvesp3RecomMaxOpV 1;
BA_ "CI_ParId" SG_ 2566608630 Hvesp3RecomMinOpV "11365";
BA_ "CI_SigId" SG_ 2566608630 Hvesp3RecomMinOpV 3754;
BA_ "CI_SigName" SG_ 2566608630 Hvesp3RecomMinOpV "HVESP3 Recommended Minimum Operating Voltage";
BA_ "SPN" SG_ 2566608630 Hvesp3RecomMinOpV 11365;
BA_ "SigType" SG_ 2566608630 Hvesp3RecomMinOpV 1;
BA_ "CI_ParId" SG_ 2566608630 Hvesp3NomV "11364";
BA_ "CI_SigId" SG_ 2566608630 Hvesp3NomV 3753;
BA_ "CI_SigName" SG_ 2566608630 Hvesp3NomV "HVESP3 Nominal Voltage";
BA_ "SPN" SG_ 2566608630 Hvesp3NomV 11364;
BA_ "SigType" SG_ 2566608630 Hvesp3NomV 1;
BA_ "CI_ParId" SG_ 2566608006 Hvesp4CellVminLim "11488";
BA_ "CI_SigId" SG_ 2566608006 Hvesp4CellVminLim 40454;
BA_ "CI_SigName" SG_ 2566608006 Hvesp4CellVminLim "HVESP4 Cell Minimum Voltage Limit";
BA_ "SPN" SG_ 2566608006 Hvesp4CellVminLim 11488;
BA_ "SigType" SG_ 2566608006 Hvesp4CellVminLim 1;
BA_ "CI_ParId" SG_ 2566608006 Hvesp4CellVmaxLim "11487";
BA_ "CI_SigId" SG_ 2566608006 Hvesp4CellVmaxLim 40453;
BA_ "CI_SigName" SG_ 2566608006 Hvesp4CellVmaxLim "HVESP4 Cell Maximum Voltage Limit";
BA_ "SPN" SG_ 2566608006 Hvesp4CellVmaxLim 11487;
BA_ "SigType" SG_ 2566608006 Hvesp4CellVmaxLim 1;
BA_ "CI_ParId" SG_ 2566608006 Hvesp4RecomMinOpTemp "11486";
BA_ "CI_SigId" SG_ 2566608006 Hvesp4RecomMinOpTemp 40452;
BA_ "CI_SigName" SG_ 2566608006 Hvesp4RecomMinOpTemp "HVESP4 Recommended Minimum Operating Temperature";
BA_ "SPN" SG_ 2566608006 Hvesp4RecomMinOpTemp 11486;
BA_ "SigType" SG_ 2566608006 Hvesp4RecomMinOpTemp 1;
BA_ "CI_ParId" SG_ 2566608006 Hvesp4RecomMaxOpTemp "11485";
BA_ "CI_SigId" SG_ 2566608006 Hvesp4RecomMaxOpTemp 40451;
BA_ "CI_SigName" SG_ 2566608006 Hvesp4RecomMaxOpTemp "HVESP4 Recommended Maximum Operating Temperature";
BA_ "SPN" SG_ 2566608006 Hvesp4RecomMaxOpTemp 11485;
BA_ "SigType" SG_ 2566608006 Hvesp4RecomMaxOpTemp 1;
BA_ "CI_ParId" SG_ 2566608006 Hvesp4RecomMaxSoc "11484";
BA_ "CI_SigId" SG_ 2566608006 Hvesp4RecomMaxSoc 40450;
BA_ "CI_SigName" SG_ 2566608006 Hvesp4RecomMaxSoc "HVESP4 Recommended Maximum State Of Charge";
BA_ "SPN" SG_ 2566608006 Hvesp4RecomMaxSoc 11484;
BA_ "SigType" SG_ 2566608006 Hvesp4RecomMaxSoc 1;
BA_ "CI_ParId" SG_ 2566608006 Hvesp4RecomMinSoc "11483";
BA_ "CI_SigId" SG_ 2566608006 Hvesp4RecomMinSoc 40449;
BA_ "CI_SigName" SG_ 2566608006 Hvesp4RecomMinSoc "HVESP4 Recommended Minimum State Of Charge";
BA_ "SPN" SG_ 2566608006 Hvesp4RecomMinSoc 11483;
BA_ "SigType" SG_ 2566608006 Hvesp4RecomMinSoc 1;
BA_ "CI_ParId" SG_ 2566608006 Hvesp4RecomMaxOpV "11482";
BA_ "CI_SigId" SG_ 2566608006 Hvesp4RecomMaxOpV 40448;
BA_ "CI_SigName" SG_ 2566608006 Hvesp4RecomMaxOpV "HVESP4 Recommended Maximum Operating Voltage";
BA_ "SPN" SG_ 2566608006 Hvesp4RecomMaxOpV 11482;
BA_ "SigType" SG_ 2566608006 Hvesp4RecomMaxOpV 1;
BA_ "CI_ParId" SG_ 2566608006 Hvesp4RecomMinOpV "11481";
BA_ "CI_SigId" SG_ 2566608006 Hvesp4RecomMinOpV 40447;
BA_ "CI_SigName" SG_ 2566608006 Hvesp4RecomMinOpV "HVESP4 Recommended Minimum Operating Voltage";
BA_ "SPN" SG_ 2566608006 Hvesp4RecomMinOpV 11481;
BA_ "SigType" SG_ 2566608006 Hvesp4RecomMinOpV 1;
BA_ "CI_ParId" SG_ 2566608006 Hvesp4NomV "11480";
BA_ "CI_SigId" SG_ 2566608006 Hvesp4NomV 40446;
BA_ "CI_SigName" SG_ 2566608006 Hvesp4NomV "HVESP4 Nominal Voltage";
BA_ "SPN" SG_ 2566608006 Hvesp4NomV 11480;
BA_ "SigType" SG_ 2566608006 Hvesp4NomV 1;
BA_ "CI_ParId" SG_ 2566607495 Hvesp5CellVminLim "11604";
BA_ "CI_SigId" SG_ 2566607495 Hvesp5CellVminLim 40465;
BA_ "CI_SigName" SG_ 2566607495 Hvesp5CellVminLim "HVESP5 Cell Minimum Voltage Limit";
BA_ "SPN" SG_ 2566607495 Hvesp5CellVminLim 11604;
BA_ "SigType" SG_ 2566607495 Hvesp5CellVminLim 1;
BA_ "CI_ParId" SG_ 2566607495 Hvesp5CellVmaxLim "11603";
BA_ "CI_SigId" SG_ 2566607495 Hvesp5CellVmaxLim 40464;
BA_ "CI_SigName" SG_ 2566607495 Hvesp5CellVmaxLim "HVESP5 Cell Maximum Voltage Limit";
BA_ "SPN" SG_ 2566607495 Hvesp5CellVmaxLim 11603;
BA_ "SigType" SG_ 2566607495 Hvesp5CellVmaxLim 1;
BA_ "CI_ParId" SG_ 2566607495 Hvesp5RecomMinOpTemp "11602";
BA_ "CI_SigId" SG_ 2566607495 Hvesp5RecomMinOpTemp 40463;
BA_ "CI_SigName" SG_ 2566607495 Hvesp5RecomMinOpTemp "HVESP5 Recommended Minimum Operating Temperature";
BA_ "SPN" SG_ 2566607495 Hvesp5RecomMinOpTemp 11602;
BA_ "SigType" SG_ 2566607495 Hvesp5RecomMinOpTemp 1;
BA_ "CI_ParId" SG_ 2566607495 Hvesp5RecomMaxOpTemp "11601";
BA_ "CI_SigId" SG_ 2566607495 Hvesp5RecomMaxOpTemp 40462;
BA_ "CI_SigName" SG_ 2566607495 Hvesp5RecomMaxOpTemp "HVESP5 Recommended Maximum Operating Temperature";
BA_ "SPN" SG_ 2566607495 Hvesp5RecomMaxOpTemp 11601;
BA_ "SigType" SG_ 2566607495 Hvesp5RecomMaxOpTemp 1;
BA_ "CI_ParId" SG_ 2566607495 Hvesp5RecomMaxSoc "11600";
BA_ "CI_SigId" SG_ 2566607495 Hvesp5RecomMaxSoc 40461;
BA_ "CI_SigName" SG_ 2566607495 Hvesp5RecomMaxSoc "HVESP5 Recommended Maximum State Of Charge";
BA_ "SPN" SG_ 2566607495 Hvesp5RecomMaxSoc 11600;
BA_ "SigType" SG_ 2566607495 Hvesp5RecomMaxSoc 1;
BA_ "CI_ParId" SG_ 2566607495 Hvesp5RecomMinSoc "11599";
BA_ "CI_SigId" SG_ 2566607495 Hvesp5RecomMinSoc 40460;
BA_ "CI_SigName" SG_ 2566607495 Hvesp5RecomMinSoc "HVESP5 Recommended Minimum State Of Charge";
BA_ "SPN" SG_ 2566607495 Hvesp5RecomMinSoc 11599;
BA_ "SigType" SG_ 2566607495 Hvesp5RecomMinSoc 1;
BA_ "CI_ParId" SG_ 2566607495 Hvesp5RecomMaxOpV "11598";
BA_ "CI_SigId" SG_ 2566607495 Hvesp5RecomMaxOpV 40459;
BA_ "CI_SigName" SG_ 2566607495 Hvesp5RecomMaxOpV "HVESP5 Recommended Maximum Operating Voltage";
BA_ "SPN" SG_ 2566607495 Hvesp5RecomMaxOpV 11598;
BA_ "SigType" SG_ 2566607495 Hvesp5RecomMaxOpV 1;
BA_ "CI_ParId" SG_ 2566607495 Hvesp5RecomMinOpV "11597";
BA_ "CI_SigId" SG_ 2566607495 Hvesp5RecomMinOpV 40458;
BA_ "CI_SigName" SG_ 2566607495 Hvesp5RecomMinOpV "HVESP5 Recommended Minimum Operating Voltage";
BA_ "SPN" SG_ 2566607495 Hvesp5RecomMinOpV 11597;
BA_ "SigType" SG_ 2566607495 Hvesp5RecomMinOpV 1;
BA_ "CI_ParId" SG_ 2566607495 Hvesp5NomV "11596";
BA_ "CI_SigId" SG_ 2566607495 Hvesp5NomV 40457;
BA_ "CI_SigName" SG_ 2566607495 Hvesp5NomV "HVESP5 Nominal Voltage";
BA_ "SPN" SG_ 2566607495 Hvesp5NomV 11596;
BA_ "SigType" SG_ 2566607495 Hvesp5NomV 1;
VAL_ 2565865739 TractMountTrailAbsWarnSig 0 "Off" 1 "On" 2 "Reserved" 3 "Take no action" ;
VAL_ 2565865739 TrailAbsSts 0 "Available But Not Active" 1 "Active" 2 "Reserved" 3 "Not Available" ;
VAL_ 2565865739 Atc_AsrInfoSig 0 "Off" 1 "On" 2 "Reserved" 3 "Take no action" ;
VAL_ 2565865739 Abs_EbsAmberWarnSig 0 "Off" 1 "On" 2 "Reserved" 3 "Take no action" ;
VAL_ 2565865739 AbsFullyOp 0 "Not Fully Operational" 1 "Fully Operational" 2 "Reserved" 3 "Not Available" ;
VAL_ 2565865739 AsrOffRoadSw 0 "Passive" 1 "Active" 2 "Error" 3 "Not Available" ;
VAL_ 2565865739 EbsBrkSw 0 "Brake pedal is not being pressed" 1 "Brake pedal is being pressed" 2 "Error" 3 "Not Available" ;
VAL_ 2565865739 AbsActv 0 "Passive but installed" 1 "Active" 2 "Reserved" 3 "Not Available" ;
VAL_ 2565865739 AsrBrkCtrlActv 0 "Passive but installed" 1 "Active" 2 "Reserved" 3 "Not Available" ;
VAL_ 2565865739 AsrEngCtrlActv 0 "Passive but installed" 1 "Active" 2 "Reserved" 3 "Not Available" ;
VAL_ 2566767627 XbrBrkHoldMode 0 "Inactive" 1 "Active" 2 "Active to inactive" 3 "Active parking brake if needed" 4 "Active restricted functionality" 5 "Brake Hold Request not accepted" 6 "Reserved" 7 "Reserved" 8 "Reserved" 9 "Reserved" 10 "Reserved" 11 "Reserved" 12 "Reserved" 13 "Reserved" 14 "Not functional/error" 15 "Not available" ;
VAL_ 2566767627 EmerBrkActv 0 "Inactive" 1 "Active" 2 "Reserved" 3 "Not Available" ;
VAL_ 2566767627 ParkBrkActFullyActv 0 "Not fully activated" 1 "Fully activated" 2 "Error" 3 "Not Available" ;
VAL_ 2566767627 XbrActvCtrlMode 0 "No demand being executing" 1 "Driver's demand executing" 2 "Addition XBR mode executing" 3 "Maximum XBR mode executing" 4 "XBR Brake Hold executed" 5 "Reserved1" 6 "Reserved2" 7 "Reserved3" 8 "Reserved4" 9 "Reserved5" 10 "Reserved6" 11 "Reserved7" 12 "Reserved8" 13 "Reserved9" 14 "Reserved10" 15 "Not Available" ;
VAL_ 2566767627 XbrSysSts 0 "Any demand will be accepted" 1 "Only highest Prio dem accepted" 2 "No demand will be accepted" 3 "Not Available" ;
VAL_ 2566767627 FoundBrkUse 0 "Foundation brakes not in use" 1 "Foundation brakes in use" 2 "Reserved" 3 "Not Available" ;
VAL_ 2566767627 HhMode 0 "Inactive" 1 "Active" 2 "Active, will change to inactive" 3 "Active, may activate park brake" 4 "Reserved" 5 "Reserved" 6 "Hill holder not functional" 7 "Not Available" ;
VAL_ 2566767627 HaltBrkMode 0 "Inactive" 1 "Active" 2 "Active, but not functioning" 3 "Not defined1" 4 "Not defined2" 5 "Not defined3" 6 "Not functional" 7 "Not Available" ;
VAL_ 2566767627 BrkTempWarn 0 "Not Active" 1 "Active" 2 "Reserved" 3 "not available" ;
VAL_ 2566841088 EngMaxMomOvrTimeLim 0 "No Override" 255 "Not applicable" ;
VAL_ 2566856960 AtDpfAregenSts 0 "Not active" 1 "Active" 2 "Needed, automatically imminent" 3 "Not Available" ;
VAL_ 2566856960 FuelType 0 "CNG" 1 "Gasoline" 2 "Diesel" 3 "Not Available" ;
VAL_ 2566856960 AcComprSts 0 "A/C compressor Off" 1 "A/C compressor On" 2 "Error" 3 "Not Available." ;
VAL_ 2566856960 EdcOpSts 0 "Normal Operation" 1 "Afterrun Drive" 2 "Diagnostic Test" 3 "Overrun Monitoring Active" 4 "Not defined" 15 "Not defined" ;
VAL_ 2566856960 EngDegrLev 0 "No degradation" 1 "Degradation Level 1" 2 "Degradation Level 2" 3 "Degradation Level 3" 4 "Degradation Level 4" 5 "Degradation Level 5" 6 "Degradation Level 6" 15 "Not defined" ;
VAL_ 2566856960 FuelFiltHeat 0 "Off" 1 "On" 2 "Error" 3 "Not Available" ;
VAL_ 2566856960 WaterInFuelInd1 0 "No" 1 "Yes" 2 "Error" 3 "Not Available" ;
VAL_ 2566856960 EngOilPrsLow 0 "Normal" 1 "Below operating range" 2 "Error" 3 "Not Available" ;
VAL_ 2566856960 RegenStsLamp 0 "Off" 1 "On" 2 "Blinking" 3 "Not Available" ;
VAL_ 2566856960 OilLifeMonSts 0 "Normal oil properties" 1 "Reset procedure feedback" 2 "Oil change required" 3 "Not Available" ;
VAL_ 2566856960 ExhGasTempSts 0 "Below Exceeding Range" 1 "Pre-warning" 2 "Warning (not reversible)" 3 "Not Available" ;
VAL_ 2566856960 VslaSts 0 "Off" 1 "Override Allowed" 2 "Override Active" 3 "Not Available" ;
VAL_ 2566856960 ElLoadReq 0 "Add.power consump not req" 1 "Add. power consump. req." 2 "Not used" 3 "Signal not available" ;
VAL_ 2566856960 ObdMilSts 0 "Off" 1 "On" 2 "Blinking" 3 "Not Available" ;
VAL_ 2566856960 EngOverTemp 0 "No warning" 1 "Prewarning" 2 "Warning" ;
VAL_ 2566856960 UnsuccRegenStsLamp1 0 "On, Unsucc. regen. above thresh." 1 "Off, Not Available" ;
VAL_ 2566856960 EngOverspeed 0 "Normal" 1 "Above operating range" 3 "Not Available" ;
VAL_ 2566856960 VslSts 0 "No Speed Limit" 1 "2nd Speed Limit" 2 "Adjustable Speed Limit" 3 "2nd and Adj. Speed Limit" ;
VAL_ 2566856960 FuelBlkByImmo 0 "Fuel released" 1 "Fuel blocked" 2 "No Immobilizer" 3 "Not Available" ;
VAL_ 2566856960 AtDpfSts 0 "Not needed" 1 "Needed, lowest level" 2 "Needed, moderate level" 3 "Needed,highest level" 4 "Reserved" 5 "Reserved" 6 "Reserved" 7 "Not Available" ;
VAL_ 2364539904 EngStarterMode 0 "Not requested" 1 "Active, gear not engaged" 2 "Active, gear engaged" 3 "Finished" 4 "Inhibited, engine running" 5 "Inhibited, engine not ready" 6 "Inhibited, driveline engaged" 7 "Inhibited, active immobilizer" 8 "Inhibited, starter over-temp" 9 "Inhibited, intake valve active" 10 "Inhibited, SCR inducement" 11 "Reserved" 12 "Inhibited, reason unknown" 13 "Error1" 14 "Error2" 15 "Not Available" ;
VAL_ 2364539904 ActEngPcTrqFract 0 "+0.000%" 1 "+0.125%" 2 "+0,250%" 3 "+0,375%" 4 "+0,500%" 5 "+0,625%" 6 "+0,750%" 7 "+0,875%" 15 "Not Available" ;
VAL_ 2364539904 EngTrqMode 0 "Low idle / No request" 1 "APP/operator selection" 2 "Cruise control" 3 "PTO governor" 4 "Road speed governor" 5 "ASR control" 6 "Transmission control" 7 "ABS control" 8 "Torque limiting" 9 "High speed governor" 10 "Braking system" 11 "Remote accelerator" 12 "Service procedure" 13 "not defined" 14 "Other" 15 "Not Available" ;
VAL_ 2566767104 FuelType_FDC200 0 "Not Available, NONE" 1 "GAS" 2 "METH" 3 "ETH" 4 "DSL" 5 "LPG" 6 "CNG" 7 "PROP" 8 "ELEC" 9 "BI_GAS" 10 "BI_METH" 11 "BI_ETH" 12 "BI_LPG" 13 "BI_CNG" 14 "BI_PROP" 15 "BI_ELEC" 16 "BI_MIX" 17 "HYB_GAS" 18 "HYB_ETH" 19 "HYB_DSL" 20 "HYB_ELEC" 21 "HYB_MIX" 22 "HYB_REG" 23 "NG" 24 "BI_NG" 25 "Bi-fuel using diesel" 26 "Natural Gas (Compr. or Liquid)" 27 "Dual Fuel, Diesel and CNG" 28 "Dual Fuel, Diesel and LNG" 29 "Fuel Cell Utilizing Hydrogen" 30 "Hydrogen Internal Combustion" 31 "Kerosene" 32 "Heavy Fuel Oil" 33 "Reserved" 253 "Reserved" 254 "Error" 255 "Not Available" ;
VAL_ 2364539648 AccPedKdSw 0 "Kickdown passive" 1 "Kickdown active" 2 "Error" 3 "Not Available" ;
VAL_ 2364539648 AccPed1LowIdleSw 0 "Not in low idle" 1 "Low idle" 2 "Error" 3 "Not Available" ;
VAL_ 2566840064 EstEngParLossPcTrq 0 "0xFB Included in SPN514" ;
VAL_ 2566898290 ApplCnt 15 "Not Available" ;
VAL_ 2566898290 MssSts 0 "Mode 0" 1 "Mode 1" 2 "Mode 2" 3 "Mode 3" 14 "Error Indicator" 15 "Not Available" ;
VAL_ 2566898290 BbPwrCons 0 "BB not active, no pwr cons" 255 "BB active, pwr cons unknown" ;
VAL_ 2566898290 ReqIscRes 0 "Off" 1 "On" ;
VAL_ 2566898290 ReqIscOff 0 "Off" 1 "On" ;
VAL_ 2566898290 EngStartSw 0 "Off" 1 "On" ;
VAL_ 2566898290 EngStopSw 0 "Off" 1 "On" ;
VAL_ 2566911858 CcAccelSw_FFF772 0 "Off" 1 "On" 2 "Error" 3 "Not Available" ;
VAL_ 2566911858 CcCoastDecelSw_FFF772 0 "Off" 1 "On" 2 "Error" 3 "Not Available" ;
VAL_ 2566911858 Vsl2Req_FFF772 0 "Off" 1 "On" 2 "Reserved" 3 "No Action" ;
VAL_ 2565865505 RetEnaBrkAssSw 0 "Disabled" 1 "Enabled" 2 "Error" 3 "Not Available" ;
VAL_ 2565865488 RetReqBrkLight 0 "Off" 1 "On" 2 "Reserved" 3 "Not Available/Take no action" ;
VAL_ 2565865488 RetEnaBrkAssSw_F00010 0 "Disabled" 1 "Enabled" 2 "Error" 3 "Not Available" ;
VAL_ 2565865488 RetTrqMode 0 "Low idle / No request" 1 "APP / Operator selection" 2 "Cruise control" 3 "PTO governor" 4 "Road speed governor" 5 "ASR control" 6 "Transmission control" 7 "ABS control" 8 "Torque limiting" 9 "High speed governor" 10 "Braking system" 11 "Remote accelerator" 12 "Service procedure" 13 "not defined" 14 "Other" 15 "Not Available" ;
VAL_ 2364539395 TransmShiftInProc 0 "Not in process" 1 "In process" 2 "Error" 3 "Not Available" ;
VAL_ 2364539395 TransmTrqConvLckEngd 0 "Differential lock disengaged" 1 "Differential lock engaged" 2 "Error" 3 "Not Available" ;
VAL_ 2364539395 TransmDrvlEngd 0 "Driveline disengaged" 1 "Driveline engaged" 2 "Error" 3 "Not Available" ;
VAL_ 2565866755 TransmCurGear 124 "Reverse" 125 "Neutral" 126 "1st Gear" 127 "2nd Gear" 128 "3rd Gear" 129 "4th Gear" 130 "5th Gear" 131 "6th Gear" 132 "7th Gear" 133 "8th Gear" 251 "Park" 254 "Error" 255 "Not Available" ;
VAL_ 2565866755 TransmSelGear 124 "Reverse" 125 "Neutral" 126 "1st Gear" 127 "2nd Gear" 128 "3rd Gear" 129 "4th Gear" 130 "5th Gear" 131 "6th Gear" 132 "7th Gear" 133 "8th Gear" 251 "Park" 254 "Error" 255 "Not Available" ;
VAL_ 2633941763 TransmRevDirSw 0 "Off" 1 "On" 2 "Error" 3 "Not Available" ;
VAL_ 2566801923 TransmMode5Ind 0 "Not active" 1 "Active" 2 "Error" 3 "Not Available" ;
VAL_ 2566801923 TransmMode1Ind 0 "Not active" 1 "Active" 2 "Error" 3 "Not Available" ;
VAL_ 2566801923 TransmEngCrkEna 0 "Cranking disabled" 1 "Cranking enabled" 2 "Error" 3 "Not Available" ;
VAL_ 2431649578 DrivAlertWarn 0 "No distracted condition detected" 1 "Level 1 - Mild distraction" 2 "Level 2 - Degradation" 3 "Level 3 - Warning" 4 "Reserved1" 5 "Reserved2" 6 "Reserved3" 7 "Not Available" ;
VAL_ 2431649578 LaneDepImmLh 0 "Not imminent" 1 "Imminent" 2 "Reserved" 3 "Not used" ;
VAL_ 2431649578 LaneDepImmRh 0 "Not imminent" 1 "Imminent" 2 "Reserved" 3 "Not Used" ;
VAL_ 2431649578 LaneDepRight 0 "Not lane depart" 1 "Lane depart" 2 "Reserved" 3 "Take no action" ;
VAL_ 2431649578 LaneDepLeft 0 "Not lane depart" 1 "Lane depart" 2 "Reserved" 3 "Take no action" ;
VAL_ 2566806314 LdwSysSts 0 "Not ready" 1 "Temporarily not available" 2 "Deactivated by driver" 3 "Ready (no warnings active)" 4 "Suppressed by operator behavior" 5 "Warning lane departure" 6 "Reserved1" 7 "Reserved2" 8 "Reserved3" 9 "Reserved4" 10 "Reserved5" 11 "Reserved6" 12 "Reserved7" 13 "Reserved8" 14 "Error" 15 "Not Available" ;
VAL_ 2566806314 LaneDepIndEnaSts 0 "Disabled" 1 "Enabled" 2 "Reserved" 3 "Not Used" ;
VAL_ 2566806314 LaneTrackStsLh 0 "Not Tracking Left side" 1 "Tracking Left side" 2 "Reserved" 3 "Don�t Care / Take no action" ;
VAL_ 2566806314 LaneTrackStsRh 0 "Not Tracking Right side" 1 "Tracking Right side" 2 "Reserved" 3 "Don�t Care / Take no action" ;
VAL_ 2566662442 LhLaneMarkerType 0 "Processing or not identified" 1 "Solid" 2 "Road edge" 3 "Dashed" 4 "Double lane marker" 5 "Raised lane marker" 6 "Reserved1" 7 "Reserved2" 8 "Reserved3" 9 "Reserved4" 10 "Reserved5" 11 "Reserved6" 12 "Reserved7" 13 "Reserved8" 14 "Error" 15 "Not Available" ;
VAL_ 2566662442 RhLaneMarkerType 0 "Processing or not identified" 1 "Solid" 2 "Road edge" 3 "Dashed" 4 "Double lane marker" 5 "Raised lane marker" 6 "Reserved1" 7 "Reserved2" 8 "Reserved3" 9 "Reserved4" 10 "Reserved5" 11 "Reserved6" 12 "Reserved7" 13 "Reserved8" 14 "Error" 15 "Not Available" ;
VAL_ 2566662442 RightDistToLaneMarkFromVehMid 251 "Not in range" 252 "Not reliable" 253 "Reserved / not used" 254 "Error" 255 "Not Available or not installed" ;
VAL_ 2566662442 LeftDistToLaneMarkFromVehMid 251 "Not in range" 252 "Not reliable" 253 "Reserved / not used" 254 "Error" 255 "Not Available or not installed" ;
VAL_ 2561223201 LdwEnaCmd 0 "Disable Lane Departure Warning" 1 "Enable Lane Departure Warning" 2 "Reserved" 3 "Don�t care" ;
VAL_ 2566749463 FrontFogLight 0 "Off" 1 "Cond. Red" 2 "Cond. Yellow" 3 "Cond. Info" 7 "Not Available" ;
VAL_ 2566749463 LdwSwdOff 0 "Off" 1 "Cond. Red" 2 "Cond. Yellow" 3 "Cond. Info" 7 "Not Available" ;
VAL_ 2566749463 PosLightSideLight 0 "Off" 1 "Cond. Red" 2 "Cond. Yellow" 3 "Cond. Info" 7 "Not Available" ;
VAL_ 2566749463 EngCoolLev 0 "Off" 1 "Cond. Red" 2 "Cond. Yellow" 3 "Cond. Info" 7 "Not Available" ;
VAL_ 2566749463 EscSwdOff 0 "Off" 1 "Cond. Red" 2 "Cond. Yellow" 3 "Cond. Info" 7 "Not Available" ;
VAL_ 2566749463 EngOil 0 "Off" 1 "Cond. Red" 2 "Cond. Yellow" 3 "Cond. Info" 7 "Not Available" ;
VAL_ 2566749463 EngOilLev_FD7D17 0 "Off" 1 "Cond. Red" 2 "Cond. Yellow" 3 "Cond. Info" 7 "Not Available" ;
VAL_ 2566749463 TcoInd 0 "Off" 1 "Cond. Red" 2 "Cond. Yellow" 3 "Cond. Info" 7 "Not Available" ;
VAL_ 2566749463 BatChgCond 0 "Off" 1 "Cond. Red" 2 "Cond. Yellow" 3 "Cond. Info" 7 "Not Available" ;
VAL_ 2566749463 EngCoolTemp_FD7D17 0 "Off" 1 "Cond. Red" 2 "Cond. Yellow" 3 "Cond. Info" 7 "Not Available" ;
VAL_ 2566749463 Malf_GenFail 0 "Off" 1 "Cond. Red" 2 "Cond. Yellow" 3 "Cond. Info" 7 "Not Available" ;
VAL_ 2566749463 AdblueLev 0 "Off" 1 "Cond. Red" 2 "Cond. Yellow" 3 "Cond. Info" 7 "Not Available" ;
VAL_ 2566749463 Airbag 0 "Off" 1 "Cond. Red" 2 "Cond. Yellow" 3 "Cond. Info" 7 "Not Available" ;
VAL_ 2566749463 FuelLev 0 "Off" 1 "Cond. Red" 2 "Cond. Yellow" 3 "Cond. Info" 7 "Not Available" ;
VAL_ 2566749463 TireFail_Malf 0 "Off" 1 "Cond. Red" 2 "Cond. Yellow" 3 "Cond. Info" 7 "Not Available" ;
VAL_ 2566749463 ElMotSts 0 "Off" 1 "Cond. Red" 2 "Cond. Yellow" 3 "Cond. Info" 7 "Not Available" ;
VAL_ 2566749463 HatchOpen 0 "Off" 1 "Cond. Red" 2 "Cond. Yellow" 3 "Cond. Info" 7 "Not Available" ;
VAL_ 2566749463 BatCool 0 "Off" 1 "Cond. Red" 2 "Cond. Yellow" 3 "Cond. Info" 7 "Not Available" ;
VAL_ 2566749463 BrkFail_BrkSysMalf 0 "Off" 1 "Cond. Red" 2 "Cond. Yellow" 3 "Cond. Info" 7 "Not Available" ;
VAL_ 2566749463 WornBrkLin 0 "Off" 1 "Cond. Red" 2 "Cond. Yellow" 3 "Cond. Info" 7 "Not Available" ;
VAL_ 2566749463 Acc 0 "Off" 1 "Cond. Red" 2 "Cond. Yellow" 3 "Cond. Info" 7 "Not Available" ;
VAL_ 2566749463 LimPerfElMot 0 "Off" 1 "Cond. Red" 2 "Cond. Yellow" 3 "Cond. Info" 7 "Not Available" ;
VAL_ 2566749463 ParkBrk 0 "Off" 1 "Cond. Red" 2 "Cond. Yellow" 3 "Cond. Info" 7 "Not Available" ;
VAL_ 2566749463 AntiLckBrkSysFail 0 "Off" 1 "Cond. Red" 2 "Cond. Yellow" 3 "Cond. Info" 7 "Not Available" ;
VAL_ 2566749463 Aebs 0 "Off" 1 "Cond. Red" 2 "Cond. Yellow" 3 "Cond. Info" 7 "Not Available" ;
VAL_ 2566749463 BatTemp_FD7D17 0 "Off" 1 "Cond. Red" 2 "Cond. Yellow" 3 "Cond. Info" 7 "Not Available" ;
VAL_ 2566749463 TransmFail_Malf 0 "Off" 1 "Cond. Red" 2 "Cond. Yellow" 3 "Cond. Info" 7 "Not Available" ;
VAL_ 2566749463 BrkLight 0 "Off" 1 "Cond. Red" 2 "Cond. Yellow" 3 "Cond. Info" 7 "Not Available" ;
VAL_ 2566749463 LaneDepInd 0 "Off" 1 "Cond. Red" 2 "Cond. Yellow" 3 "Cond. Info" 7 "Not Available" ;
VAL_ 2566749463 HighVSysCaution 0 "Off" 1 "Cond. Red" 2 "Cond. Yellow" 3 "Cond. Info" 7 "Not Available" ;
VAL_ 2566749463 HazardWarn 0 "Off" 1 "Cond. Red" 2 "Cond. Yellow" 3 "Cond. Info" 7 "Not Available" ;
VAL_ 2566749463 TransmFluidTemp 0 "Off" 1 "Cond. Red" 2 "Cond. Yellow" 3 "Cond. Info" 7 "Not Available" ;
VAL_ 2566749463 EscInd 0 "Off" 1 "Cond. Red" 2 "Cond. Yellow" 3 "Cond. Info" 7 "Not Available" ;
VAL_ 2566749463 Bat 0 "Off" 1 "Cond. Red" 2 "Cond. Yellow" 3 "Cond. Info" 7 "Not Available" ;
VAL_ 2566749463 TurnSigs 0 "Off" 1 "Cond. Red" 2 "Cond. Yellow" 3 "Cond. Info" 7 "Not Available" ;
VAL_ 2566749463 ServCallForMaint 0 "Off" 1 "Cond. Red" 2 "Cond. Yellow" 3 "Cond. Info" 7 "Not Available" ;
VAL_ 2566749463 EngEmisSysFailMil 0 "Off" 1 "Cond. Red" 2 "Cond. Yellow" 3 "Cond. Info" 7 "Not Available" ;
VAL_ 2566749463 SeatBelt 0 "Off" 1 "Cond. Red" 2 "Cond. Yellow" 3 "Cond. Info" 7 "Not Available" ;
VAL_ 2566749463 LowBeamDipBeam 0 "Off" 1 "Cond. Red" 2 "Cond. Yellow" 3 "Cond. Info" 7 "Not Available" ;
VAL_ 2566749463 Eng_Mil 0 "Off" 1 "Cond. Red" 2 "Cond. Yellow" 3 "Cond. Info" 7 "Not Available" ;
VAL_ 2566749463 Ret 0 "Off" 1 "Cond. Red" 2 "Cond. Yellow" 3 "Cond. Info" 7 "Not Available" ;
VAL_ 2566749463 FuelFiltDiffPrs 0 "Off" 1 "Cond. Red" 2 "Cond. Yellow" 3 "Cond. Info" 7 "Not Available" ;
VAL_ 2566749463 HighBeamMainBeam 0 "Off" 1 "Cond. Red" 2 "Cond. Yellow" 3 "Cond. Info" 7 "Not Available" ;
VAL_ 2566749463 HtCtrl 0 "Off" 1 "Cond. Red" 2 "Cond. Yellow" 3 "Cond. Info" 7 "Not Available" ;
VAL_ 2566749463 AirFiltClog 0 "Off" 1 "Cond. Red" 2 "Cond. Yellow" 3 "Cond. Info" 7 "Not Available" ;
VAL_ 2566749463 ElMotFails 0 "Off" 1 "Cond. Red" 2 "Cond. Yellow" 3 "Cond. Info" 7 "Not Available" ;
VAL_ 2566749463 RearFogLight 0 "Off" 1 "Cond. Red" 2 "Cond. Yellow" 3 "Cond. Info" 7 "Not Available" ;
VAL_ 2566749463 EngEmisFilt 0 "Off" 1 "Cond. Red" 2 "Cond. Yellow" 3 "Cond. Info" 7 "Not Available" ;
VAL_ 2566896128 EngInstFuelEcon 64256 "Infinite" ;
